VERSION "HNPBNNNYNNNNNNNNNNNNNNNNNNNNNNNNYNYYYYYYYY>4>%%%/4>'%**4YYY///"

NS_ :

BS_:

BU_: ExternalUnit SRR308

BO_ 881 YawRateInformation_7: 2 ExternalUnit
 SG_ RadarDevice_YawRate : 7|16@0+ (0.01,-327.68) [-327.68|327.66] "�/s"  SRR308

BO_ 865 YawRateInformation_6: 2 ExternalUnit
 SG_ RadarDevice_YawRate : 7|16@0+ (0.01,-327.68) [-327.68|327.66] "�/s"  SRR308

BO_ 849 YawRateInformation_5: 2 ExternalUnit
 SG_ RadarDevice_YawRate : 7|16@0+ (0.01,-327.68) [-327.68|327.66] "�/s"  SRR308

BO_ 833 YawRateInformation_4: 2 ExternalUnit
 SG_ RadarDevice_YawRate : 7|16@0+ (0.01,-327.68) [-327.68|327.66] "�/s"  SRR308

BO_ 817 YawRateInformation_3: 2 ExternalUnit
 SG_ RadarDevice_YawRate : 7|16@0+ (0.01,-327.68) [-327.68|327.66] "�/s"  SRR308

BO_ 801 YawRateInformation_2: 2 ExternalUnit
 SG_ RadarDevice_YawRate : 7|16@0+ (0.01,-327.68) [-327.68|327.66] "�/s"  SRR308

BO_ 785 YawRateInformation_1: 2 ExternalUnit
 SG_ RadarDevice_YawRate : 7|16@0+ (0.01,-327.68) [-327.68|327.66] "�/s"  SRR308

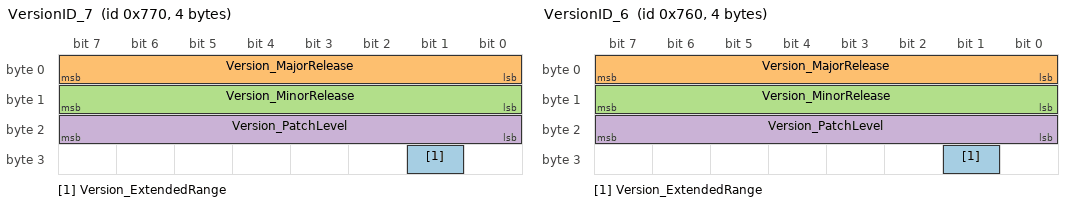
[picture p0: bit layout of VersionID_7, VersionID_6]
BO_ 1904 VersionID_7: 4 SRR308
 SG_ Version_ExtendedRange : 25|1@0+ (1,0) [0|0] ""  ExternalUnit
 SG_ Version_MajorRelease : 7|8@0+ (1,0) [0|256] ""  ExternalUnit
 SG_ Version_MinorRelease : 15|8@0+ (1,0) [0|256] ""  ExternalUnit
 SG_ Version_PatchLevel : 23|8@0+ (1,0) [0|256] ""  ExternalUnit

BO_ 1888 VersionID_6: 4 SRR308
 SG_ Version_ExtendedRange : 25|1@0+ (1,0) [0|0] ""  ExternalUnit
 SG_ Version_MajorRelease : 7|8@0+ (1,0) [0|256] ""  ExternalUnit
 SG_ Version_MinorRelease : 15|8@0+ (1,0) [0|256] ""  ExternalUnit
 SG_ Version_PatchLevel : 23|8@0+ (1,0) [0|256] ""  ExternalUnit

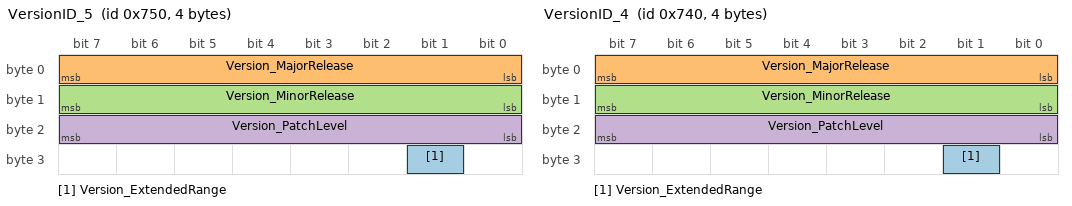
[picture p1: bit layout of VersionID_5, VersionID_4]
BO_ 1872 VersionID_5: 4 SRR308
 SG_ Version_ExtendedRange : 25|1@0+ (1,0) [0|0] ""  ExternalUnit
 SG_ Version_MajorRelease : 7|8@0+ (1,0) [0|256] ""  ExternalUnit
 SG_ Version_MinorRelease : 15|8@0+ (1,0) [0|256] ""  ExternalUnit
 SG_ Version_PatchLevel : 23|8@0+ (1,0) [0|256] ""  ExternalUnit

BO_ 1856 VersionID_4: 4 SRR308
 SG_ Version_ExtendedRange : 25|1@0+ (1,0) [0|0] ""  ExternalUnit
 SG_ Version_MajorRelease : 7|8@0+ (1,0) [0|256] ""  ExternalUnit
 SG_ Version_MinorRelease : 15|8@0+ (1,0) [0|256] ""  ExternalUnit
 SG_ Version_PatchLevel : 23|8@0+ (1,0) [0|256] ""  ExternalUnit

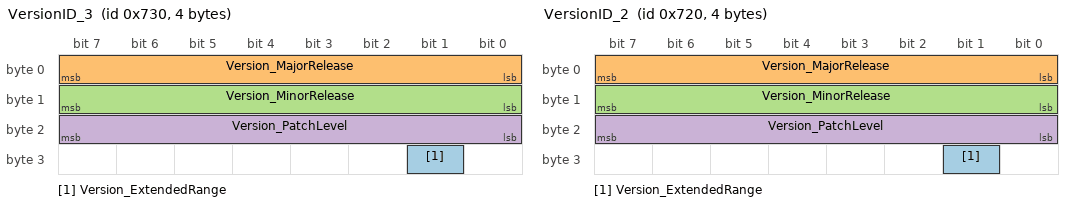
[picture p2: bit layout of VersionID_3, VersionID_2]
BO_ 1840 VersionID_3: 4 SRR308
 SG_ Version_ExtendedRange : 25|1@0+ (1,0) [0|0] ""  ExternalUnit
 SG_ Version_MajorRelease : 7|8@0+ (1,0) [0|256] ""  ExternalUnit
 SG_ Version_MinorRelease : 15|8@0+ (1,0) [0|256] ""  ExternalUnit
 SG_ Version_PatchLevel : 23|8@0+ (1,0) [0|256] ""  ExternalUnit

BO_ 1824 VersionID_2: 4 SRR308
 SG_ Version_ExtendedRange : 25|1@0+ (1,0) [0|0] ""  ExternalUnit
 SG_ Version_MajorRelease : 7|8@0+ (1,0) [0|256] ""  ExternalUnit
 SG_ Version_MinorRelease : 15|8@0+ (1,0) [0|256] ""  ExternalUnit
 SG_ Version_PatchLevel : 23|8@0+ (1,0) [0|256] ""  ExternalUnit

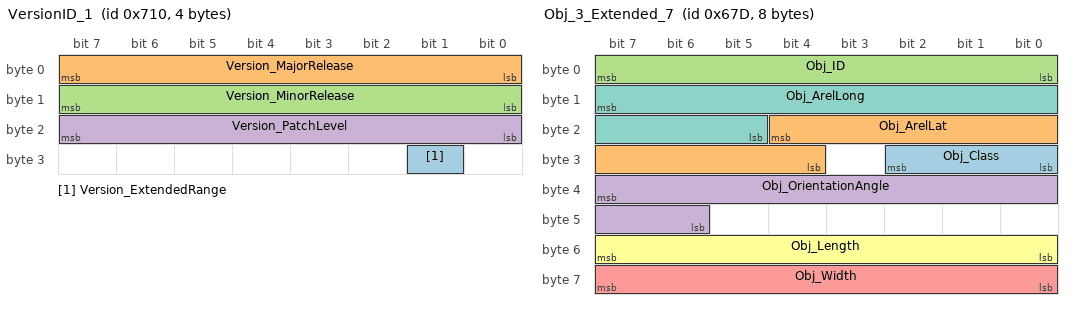
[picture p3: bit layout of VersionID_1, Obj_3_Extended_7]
BO_ 1808 VersionID_1: 4 SRR308
 SG_ Version_ExtendedRange : 25|1@0+ (1,0) [0|0] ""  ExternalUnit
 SG_ Version_MajorRelease : 7|8@0+ (1,0) [0|256] ""  ExternalUnit
 SG_ Version_MinorRelease : 15|8@0+ (1,0) [0|256] ""  ExternalUnit
 SG_ Version_PatchLevel : 23|8@0+ (1,0) [0|256] ""  ExternalUnit

BO_ 880 SpeedInformation_7: 2 ExternalUnit
 SG_ RadarDevice_Speed : 4|13@0+ (0.02,0) [0|163.8] "m/s"  SRR308
 SG_ RadarDevice_SpeedDirection : 7|2@0+ (1,0) [0|2] ""  SRR308

BO_ 864 SpeedInformation_6: 2 ExternalUnit
 SG_ RadarDevice_Speed : 4|13@0+ (0.02,0) [0|163.8] "m/s"  SRR308
 SG_ RadarDevice_SpeedDirection : 7|2@0+ (1,0) [0|2] ""  SRR308

BO_ 848 SpeedInformation_5: 2 ExternalUnit
 SG_ RadarDevice_Speed : 4|13@0+ (0.02,0) [0|163.8] "m/s"  SRR308
 SG_ RadarDevice_SpeedDirection : 7|2@0+ (1,0) [0|2] ""  SRR308

BO_ 832 SpeedInformation_4: 2 ExternalUnit
 SG_ RadarDevice_Speed : 4|13@0+ (0.02,0) [0|163.8] "m/s"  SRR308
 SG_ RadarDevice_SpeedDirection : 7|2@0+ (1,0) [0|2] ""  SRR308

BO_ 816 SpeedInformation_3: 2 ExternalUnit
 SG_ RadarDevice_Speed : 4|13@0+ (0.02,0) [0|163.8] "m/s"  SRR308
 SG_ RadarDevice_SpeedDirection : 7|2@0+ (1,0) [0|2] ""  SRR308

BO_ 800 SpeedInformation_2: 2 ExternalUnit
 SG_ RadarDevice_Speed : 4|13@0+ (0.02,0) [0|163.8] "m/s"  SRR308
 SG_ RadarDevice_SpeedDirection : 7|2@0+ (1,0) [0|2] ""  SRR308

BO_ 784 SpeedInformation_1: 2 ExternalUnit
 SG_ RadarDevice_Speed : 4|13@0+ (0.02,0) [0|163.8] "m/s"  SRR308
 SG_ RadarDevice_SpeedDirection : 7|2@0+ (1,0) [0|2] ""  SRR308

BO_ 625 RadarState_7: 8 SRR308
 SG_ RadarState_InvalidClusters : 55|8@0+ (1,0) [0|255] ""  ExternalUnit
 SG_ RadarState_Voltage_Error : 17|1@0+ (1,0) [0|0] ""  ExternalUnit
 SG_ RadarState_Temporary_Error : 18|1@0+ (1,0) [0|0] ""  ExternalUnit
 SG_ RadarState_Temperature_Error : 19|1@0+ (1,0) [0|0] ""  ExternalUnit
 SG_ RadarState_Interference : 20|1@0+ (1,0) [0|0] ""  ExternalUnit
 SG_ RadarState_Persistent_Error : 21|1@0+ (1,0) [0|0] ""  ExternalUnit
 SG_ RadarState_SortIndex : 38|3@0+ (1,0) [0|0] ""  ExternalUnit
 SG_ RadarState_RCS_Threshold : 60|3@0+ (1,0) [0|7] ""  ExternalUnit
 SG_ RadarState_CtrlRelayCfg : 41|1@0+ (1,0) [0|1] ""  ExternalUnit
 SG_ RadarState_SendQualityCfg : 44|1@0+ (1,0) [0|1] ""  ExternalUnit
 SG_ RadarState_SendExtInfoCfg : 45|1@0+ (1,0) [0|1] ""  ExternalUnit
 SG_ RadarState_MotionRxState : 47|2@0+ (1,0) [0|3] ""  ExternalUnit
 SG_ RadarState_SensorID : 34|3@0+ (1,0) [0|7] ""  ExternalUnit
 SG_ RadarState_OutputTypeCfg : 43|2@0+ (1,0) [0|3] ""  ExternalUnit
 SG_ RadarState_RadarPowerCfg : 25|3@0+ (1,0) [0|7] ""  ExternalUnit
 SG_ RadarState_NVMReadStatus : 6|1@0+ (1,0) [0|1] ""  ExternalUnit
 SG_ RadarState_NVMwriteStatus : 7|1@0+ (1,0) [0|1] ""  ExternalUnit
 SG_ RadarState_MaxDistanceCfg : 15|10@0+ (2,0) [0|2046] ""  ExternalUnit

BO_ 609 RadarState_6: 8 SRR308
 SG_ RadarState_InvalidClusters : 55|8@0+ (1,0) [0|255] ""  ExternalUnit
 SG_ RadarState_Voltage_Error : 17|1@0+ (1,0) [0|0] ""  ExternalUnit
 SG_ RadarState_Temporary_Error : 18|1@0+ (1,0) [0|0] ""  ExternalUnit
 SG_ RadarState_Temperature_Error : 19|1@0+ (1,0) [0|0] ""  ExternalUnit
 SG_ RadarState_Interference : 20|1@0+ (1,0) [0|0] ""  ExternalUnit
 SG_ RadarState_Persistent_Error : 21|1@0+ (1,0) [0|0] ""  ExternalUnit
 SG_ RadarState_SortIndex : 38|3@0+ (1,0) [0|0] ""  ExternalUnit
 SG_ RadarState_RCS_Threshold : 60|3@0+ (1,0) [0|7] ""  ExternalUnit
 SG_ RadarState_CtrlRelayCfg : 41|1@0+ (1,0) [0|1] ""  ExternalUnit
 SG_ RadarState_SendQualityCfg : 44|1@0+ (1,0) [0|1] ""  ExternalUnit
 SG_ RadarState_SendExtInfoCfg : 45|1@0+ (1,0) [0|1] ""  ExternalUnit
 SG_ RadarState_MotionRxState : 47|2@0+ (1,0) [0|3] ""  ExternalUnit
 SG_ RadarState_SensorID : 34|3@0+ (1,0) [0|7] ""  ExternalUnit
 SG_ RadarState_OutputTypeCfg : 43|2@0+ (1,0) [0|3] ""  ExternalUnit
 SG_ RadarState_RadarPowerCfg : 25|3@0+ (1,0) [0|7] ""  ExternalUnit
 SG_ RadarState_NVMReadStatus : 6|1@0+ (1,0) [0|1] ""  ExternalUnit
 SG_ RadarState_NVMwriteStatus : 7|1@0+ (1,0) [0|1] ""  ExternalUnit
 SG_ RadarState_MaxDistanceCfg : 15|10@0+ (2,0) [0|2046] ""  ExternalUnit

BO_ 593 RadarState_5: 8 SRR308
 SG_ RadarState_InvalidClusters : 55|8@0+ (1,0) [0|255] ""  ExternalUnit
 SG_ RadarState_Voltage_Error : 17|1@0+ (1,0) [0|0] ""  ExternalUnit
 SG_ RadarState_Temporary_Error : 18|1@0+ (1,0) [0|0] ""  ExternalUnit
 SG_ RadarState_Temperature_Error : 19|1@0+ (1,0) [0|0] ""  ExternalUnit
 SG_ RadarState_Interference : 20|1@0+ (1,0) [0|0] ""  ExternalUnit
 SG_ RadarState_Persistent_Error : 21|1@0+ (1,0) [0|0] ""  ExternalUnit
 SG_ RadarState_SortIndex : 38|3@0+ (1,0) [0|0] ""  ExternalUnit
 SG_ RadarState_RCS_Threshold : 60|3@0+ (1,0) [0|7] ""  ExternalUnit
 SG_ RadarState_CtrlRelayCfg : 41|1@0+ (1,0) [0|1] ""  ExternalUnit
 SG_ RadarState_SendQualityCfg : 44|1@0+ (1,0) [0|1] ""  ExternalUnit
 SG_ RadarState_SendExtInfoCfg : 45|1@0+ (1,0) [0|1] ""  ExternalUnit
 SG_ RadarState_MotionRxState : 47|2@0+ (1,0) [0|3] ""  ExternalUnit
 SG_ RadarState_SensorID : 34|3@0+ (1,0) [0|7] ""  ExternalUnit
 SG_ RadarState_OutputTypeCfg : 43|2@0+ (1,0) [0|3] ""  ExternalUnit
 SG_ RadarState_RadarPowerCfg : 25|3@0+ (1,0) [0|7] ""  ExternalUnit
 SG_ RadarState_NVMReadStatus : 6|1@0+ (1,0) [0|1] ""  ExternalUnit
 SG_ RadarState_NVMwriteStatus : 7|1@0+ (1,0) [0|1] ""  ExternalUnit
 SG_ RadarState_MaxDistanceCfg : 15|10@0+ (2,0) [0|2046] ""  ExternalUnit

BO_ 577 RadarState_4: 8 SRR308
 SG_ RadarState_InvalidClusters : 55|8@0+ (1,0) [0|255] ""  ExternalUnit
 SG_ RadarState_Voltage_Error : 17|1@0+ (1,0) [0|0] ""  ExternalUnit
 SG_ RadarState_Temporary_Error : 18|1@0+ (1,0) [0|0] ""  ExternalUnit
 SG_ RadarState_Temperature_Error : 19|1@0+ (1,0) [0|0] ""  ExternalUnit
 SG_ RadarState_Interference : 20|1@0+ (1,0) [0|0] ""  ExternalUnit
 SG_ RadarState_Persistent_Error : 21|1@0+ (1,0) [0|0] ""  ExternalUnit
 SG_ RadarState_SortIndex : 38|3@0+ (1,0) [0|0] ""  ExternalUnit
 SG_ RadarState_RCS_Threshold : 60|3@0+ (1,0) [0|7] ""  ExternalUnit
 SG_ RadarState_CtrlRelayCfg : 41|1@0+ (1,0) [0|1] ""  ExternalUnit
 SG_ RadarState_SendQualityCfg : 44|1@0+ (1,0) [0|1] ""  ExternalUnit
 SG_ RadarState_SendExtInfoCfg : 45|1@0+ (1,0) [0|1] ""  ExternalUnit
 SG_ RadarState_MotionRxState : 47|2@0+ (1,0) [0|3] ""  ExternalUnit
 SG_ RadarState_SensorID : 34|3@0+ (1,0) [0|7] ""  ExternalUnit
 SG_ RadarState_OutputTypeCfg : 43|2@0+ (1,0) [0|3] ""  ExternalUnit
 SG_ RadarState_RadarPowerCfg : 25|3@0+ (1,0) [0|7] ""  ExternalUnit
 SG_ RadarState_NVMReadStatus : 6|1@0+ (1,0) [0|1] ""  ExternalUnit
 SG_ RadarState_NVMwriteStatus : 7|1@0+ (1,0) [0|1] ""  ExternalUnit
 SG_ RadarState_MaxDistanceCfg : 15|10@0+ (2,0) [0|2046] ""  ExternalUnit

BO_ 561 RadarState_3: 8 SRR308
 SG_ RadarState_InvalidClusters : 55|8@0+ (1,0) [0|255] ""  ExternalUnit
 SG_ RadarState_Voltage_Error : 17|1@0+ (1,0) [0|0] ""  ExternalUnit
 SG_ RadarState_Temporary_Error : 18|1@0+ (1,0) [0|0] ""  ExternalUnit
 SG_ RadarState_Temperature_Error : 19|1@0+ (1,0) [0|0] ""  ExternalUnit
 SG_ RadarState_Interference : 20|1@0+ (1,0) [0|0] ""  ExternalUnit
 SG_ RadarState_Persistent_Error : 21|1@0+ (1,0) [0|0] ""  ExternalUnit
 SG_ RadarState_SortIndex : 38|3@0+ (1,0) [0|0] ""  ExternalUnit
 SG_ RadarState_RCS_Threshold : 60|3@0+ (1,0) [0|7] ""  ExternalUnit
 SG_ RadarState_CtrlRelayCfg : 41|1@0+ (1,0) [0|1] ""  ExternalUnit
 SG_ RadarState_SendQualityCfg : 44|1@0+ (1,0) [0|1] ""  ExternalUnit
 SG_ RadarState_SendExtInfoCfg : 45|1@0+ (1,0) [0|1] ""  ExternalUnit
 SG_ RadarState_MotionRxState : 47|2@0+ (1,0) [0|3] ""  ExternalUnit
 SG_ RadarState_SensorID : 34|3@0+ (1,0) [0|7] ""  ExternalUnit
 SG_ RadarState_OutputTypeCfg : 43|2@0+ (1,0) [0|3] ""  ExternalUnit
 SG_ RadarState_RadarPowerCfg : 25|3@0+ (1,0) [0|7] ""  ExternalUnit
 SG_ RadarState_NVMReadStatus : 6|1@0+ (1,0) [0|1] ""  ExternalUnit
 SG_ RadarState_NVMwriteStatus : 7|1@0+ (1,0) [0|1] ""  ExternalUnit
 SG_ RadarState_MaxDistanceCfg : 15|10@0+ (2,0) [0|2046] ""  ExternalUnit

BO_ 545 RadarState_2: 8 SRR308
 SG_ RadarState_InvalidClusters : 55|8@0+ (1,0) [0|255] ""  ExternalUnit
 SG_ RadarState_Voltage_Error : 17|1@0+ (1,0) [0|0] ""  ExternalUnit
 SG_ RadarState_Temporary_Error : 18|1@0+ (1,0) [0|0] ""  ExternalUnit
 SG_ RadarState_Temperature_Error : 19|1@0+ (1,0) [0|0] ""  ExternalUnit
 SG_ RadarState_Interference : 20|1@0+ (1,0) [0|0] ""  ExternalUnit
 SG_ RadarState_Persistent_Error : 21|1@0+ (1,0) [0|0] ""  ExternalUnit
 SG_ RadarState_SortIndex : 38|3@0+ (1,0) [0|0] ""  ExternalUnit
 SG_ RadarState_RCS_Threshold : 60|3@0+ (1,0) [0|7] ""  ExternalUnit
 SG_ RadarState_CtrlRelayCfg : 41|1@0+ (1,0) [0|1] ""  ExternalUnit
 SG_ RadarState_SendQualityCfg : 44|1@0+ (1,0) [0|1] ""  ExternalUnit
 SG_ RadarState_SendExtInfoCfg : 45|1@0+ (1,0) [0|1] ""  ExternalUnit
 SG_ RadarState_MotionRxState : 47|2@0+ (1,0) [0|3] ""  ExternalUnit
 SG_ RadarState_SensorID : 34|3@0+ (1,0) [0|7] ""  ExternalUnit
 SG_ RadarState_OutputTypeCfg : 43|2@0+ (1,0) [0|3] ""  ExternalUnit
 SG_ RadarState_RadarPowerCfg : 25|3@0+ (1,0) [0|7] ""  ExternalUnit
 SG_ RadarState_NVMReadStatus : 6|1@0+ (1,0) [0|1] ""  ExternalUnit
 SG_ RadarState_NVMwriteStatus : 7|1@0+ (1,0) [0|1] ""  ExternalUnit
 SG_ RadarState_MaxDistanceCfg : 15|10@0+ (2,0) [0|2046] ""  ExternalUnit

BO_ 529 RadarState_1: 8 SRR308
 SG_ RadarState_InvalidClusters : 55|8@0+ (1,0) [0|255] ""  ExternalUnit
 SG_ RadarState_Voltage_Error : 17|1@0+ (1,0) [0|0] ""  ExternalUnit
 SG_ RadarState_Temporary_Error : 18|1@0+ (1,0) [0|0] ""  ExternalUnit
 SG_ RadarState_Temperature_Error : 19|1@0+ (1,0) [0|0] ""  ExternalUnit
 SG_ RadarState_Interference : 20|1@0+ (1,0) [0|0] ""  ExternalUnit
 SG_ RadarState_Persistent_Error : 21|1@0+ (1,0) [0|0] ""  ExternalUnit
 SG_ RadarState_SortIndex : 38|3@0+ (1,0) [0|0] ""  ExternalUnit
 SG_ RadarState_RCS_Threshold : 60|3@0+ (1,0) [0|7] ""  ExternalUnit
 SG_ RadarState_CtrlRelayCfg : 41|1@0+ (1,0) [0|1] ""  ExternalUnit
 SG_ RadarState_SendQualityCfg : 44|1@0+ (1,0) [0|1] ""  ExternalUnit
 SG_ RadarState_SendExtInfoCfg : 45|1@0+ (1,0) [0|1] ""  ExternalUnit
 SG_ RadarState_MotionRxState : 47|2@0+ (1,0) [0|3] ""  ExternalUnit
 SG_ RadarState_SensorID : 34|3@0+ (1,0) [0|7] ""  ExternalUnit
 SG_ RadarState_OutputTypeCfg : 43|2@0+ (1,0) [0|3] ""  ExternalUnit
 SG_ RadarState_RadarPowerCfg : 25|3@0+ (1,0) [0|7] ""  ExternalUnit
 SG_ RadarState_NVMReadStatus : 6|1@0+ (1,0) [0|1] ""  ExternalUnit
 SG_ RadarState_NVMwriteStatus : 7|1@0+ (1,0) [0|1] ""  ExternalUnit
 SG_ RadarState_MaxDistanceCfg : 15|10@0+ (2,0) [0|2046] ""  ExternalUnit

BO_ 624 RadarConfiguration_7: 8 ExternalUnit
 SG_ RadarCfg_InvalidClusters_valid : 52|1@0+ (1,0) [0|1] ""  SRR308,ExternalUnit
 SG_ RadarCfg_InvalidClusters : 63|8@0+ (1,0) [0|255] ""  SRR308,ExternalUnit
 SG_ RadarCfg_RCS_Threshold_Valid : 48|1@0+ (1,0) [0|1] ""  SRR308,ExternalUnit
 SG_ RadarCfg_RCS_Threshold : 51|3@0+ (1,0) [0|7] ""  SRR308,ExternalUnit
 SG_ RadarCfg_StoreInNVM_valid : 7|1@0+ (1,0) [0|1] ""  SRR308,ExternalUnit
 SG_ RadarCfg_SortIndex_valid : 6|1@0+ (1,0) [0|1] ""  SRR308,ExternalUnit
 SG_ RadarCfg_SortIndex : 46|3@0+ (1,0) [0|7] ""  SRR308,ExternalUnit
 SG_ RadarCfg_StoreInNVM : 47|1@0+ (1,0) [0|1] ""  SRR308,ExternalUnit
 SG_ RadarCfg_SendExtInfo_valid : 5|1@0+ (1,0) [0|1] ""  SRR308,ExternalUnit
 SG_ RadarCfg_SendExtInfo : 43|1@0+ (1,0) [0|1] ""  SRR308,ExternalUnit
 SG_ RadarCfg_CtrlRelay_valid : 40|1@0+ (1,0) [0|1] ""  SRR308,ExternalUnit
 SG_ RadarCfg_CtrlRelay : 41|1@0+ (1,0) [0|1] ""  SRR308,ExternalUnit
 SG_ RadarCfg_SendQuality_valid : 4|1@0+ (1,0) [0|1] ""  SRR308,ExternalUnit
 SG_ RadarCfg_SendQuality : 42|1@0+ (1,0) [0|1] ""  SRR308,ExternalUnit
 SG_ RadarCfg_MaxDistance_valid : 0|1@0+ (1,0) [0|1] ""  SRR308,ExternalUnit
 SG_ RadarCfg_OutputType_valid : 3|1@0+ (1,0) [0|1] ""  SRR308,ExternalUnit
 SG_ RadarCfg_SensorID_valid : 1|1@0+ (1,0) [0|1] ""  SRR308,ExternalUnit
 SG_ RadarCfg_MaxDistance : 15|10@0+ (2,0) [0|2046] "m"  SRR308,ExternalUnit
 SG_ RadarCfg_OutputType : 36|2@0+ (1,0) [0|2] ""  SRR308,ExternalUnit
 SG_ RadarCfg_SensorID : 34|3@0+ (1,0) [0|7] ""  SRR308,ExternalUnit

BO_ 608 RadarConfiguration_6: 8 ExternalUnit
 SG_ RadarCfg_InvalidClusters_valid : 52|1@0+ (1,0) [0|1] ""  SRR308,ExternalUnit
 SG_ RadarCfg_InvalidClusters : 63|8@0+ (1,0) [0|255] ""  SRR308,ExternalUnit
 SG_ RadarCfg_RCS_Threshold_Valid : 48|1@0+ (1,0) [0|1] ""  SRR308,ExternalUnit
 SG_ RadarCfg_RCS_Threshold : 51|3@0+ (1,0) [0|7] ""  SRR308,ExternalUnit
 SG_ RadarCfg_StoreInNVM_valid : 7|1@0+ (1,0) [0|1] ""  SRR308,ExternalUnit
 SG_ RadarCfg_SortIndex_valid : 6|1@0+ (1,0) [0|1] ""  SRR308,ExternalUnit
 SG_ RadarCfg_SortIndex : 46|3@0+ (1,0) [0|7] ""  SRR308,ExternalUnit
 SG_ RadarCfg_StoreInNVM : 47|1@0+ (1,0) [0|1] ""  SRR308,ExternalUnit
 SG_ RadarCfg_SendExtInfo_valid : 5|1@0+ (1,0) [0|1] ""  SRR308,ExternalUnit
 SG_ RadarCfg_SendExtInfo : 43|1@0+ (1,0) [0|1] ""  SRR308,ExternalUnit
 SG_ RadarCfg_CtrlRelay_valid : 40|1@0+ (1,0) [0|1] ""  SRR308,ExternalUnit
 SG_ RadarCfg_CtrlRelay : 41|1@0+ (1,0) [0|1] ""  SRR308,ExternalUnit
 SG_ RadarCfg_SendQuality_valid : 4|1@0+ (1,0) [0|1] ""  SRR308,ExternalUnit
 SG_ RadarCfg_SendQuality : 42|1@0+ (1,0) [0|1] ""  SRR308,ExternalUnit
 SG_ RadarCfg_MaxDistance_valid : 0|1@0+ (1,0) [0|1] ""  SRR308,ExternalUnit
 SG_ RadarCfg_OutputType_valid : 3|1@0+ (1,0) [0|1] ""  SRR308,ExternalUnit
 SG_ RadarCfg_SensorID_valid : 1|1@0+ (1,0) [0|1] ""  SRR308,ExternalUnit
 SG_ RadarCfg_MaxDistance : 15|10@0+ (2,0) [0|2046] "m"  SRR308,ExternalUnit
 SG_ RadarCfg_OutputType : 36|2@0+ (1,0) [0|2] ""  SRR308,ExternalUnit
 SG_ RadarCfg_SensorID : 34|3@0+ (1,0) [0|7] ""  SRR308,ExternalUnit

BO_ 592 RadarConfiguration_5: 8 ExternalUnit
 SG_ RadarCfg_InvalidClusters_valid : 52|1@0+ (1,0) [0|1] ""  SRR308,ExternalUnit
 SG_ RadarCfg_InvalidClusters : 63|8@0+ (1,0) [0|255] ""  SRR308,ExternalUnit
 SG_ RadarCfg_RCS_Threshold_Valid : 48|1@0+ (1,0) [0|1] ""  SRR308,ExternalUnit
 SG_ RadarCfg_RCS_Threshold : 51|3@0+ (1,0) [0|7] ""  SRR308,ExternalUnit
 SG_ RadarCfg_StoreInNVM_valid : 7|1@0+ (1,0) [0|1] ""  SRR308,ExternalUnit
 SG_ RadarCfg_SortIndex_valid : 6|1@0+ (1,0) [0|1] ""  SRR308,ExternalUnit
 SG_ RadarCfg_SortIndex : 46|3@0+ (1,0) [0|7] ""  SRR308,ExternalUnit
 SG_ RadarCfg_StoreInNVM : 47|1@0+ (1,0) [0|1] ""  SRR308,ExternalUnit
 SG_ RadarCfg_SendExtInfo_valid : 5|1@0+ (1,0) [0|1] ""  SRR308,ExternalUnit
 SG_ RadarCfg_SendExtInfo : 43|1@0+ (1,0) [0|1] ""  SRR308,ExternalUnit
 SG_ RadarCfg_CtrlRelay_valid : 40|1@0+ (1,0) [0|1] ""  SRR308,ExternalUnit
 SG_ RadarCfg_CtrlRelay : 41|1@0+ (1,0) [0|1] ""  SRR308,ExternalUnit
 SG_ RadarCfg_SendQuality_valid : 4|1@0+ (1,0) [0|1] ""  SRR308,ExternalUnit
 SG_ RadarCfg_SendQuality : 42|1@0+ (1,0) [0|1] ""  SRR308,ExternalUnit
 SG_ RadarCfg_MaxDistance_valid : 0|1@0+ (1,0) [0|1] ""  SRR308,ExternalUnit
 SG_ RadarCfg_OutputType_valid : 3|1@0+ (1,0) [0|1] ""  SRR308,ExternalUnit
 SG_ RadarCfg_SensorID_valid : 1|1@0+ (1,0) [0|1] ""  SRR308,ExternalUnit
 SG_ RadarCfg_MaxDistance : 15|10@0+ (2,0) [0|2046] "m"  SRR308,ExternalUnit
 SG_ RadarCfg_OutputType : 36|2@0+ (1,0) [0|2] ""  SRR308,ExternalUnit
 SG_ RadarCfg_SensorID : 34|3@0+ (1,0) [0|7] ""  SRR308,ExternalUnit

BO_ 576 RadarConfiguration_4: 8 ExternalUnit
 SG_ RadarCfg_InvalidClusters_valid : 52|1@0+ (1,0) [0|1] ""  SRR308,ExternalUnit
 SG_ RadarCfg_InvalidClusters : 63|8@0+ (1,0) [0|255] ""  SRR308,ExternalUnit
 SG_ RadarCfg_RCS_Threshold_Valid : 48|1@0+ (1,0) [0|1] ""  SRR308,ExternalUnit
 SG_ RadarCfg_RCS_Threshold : 51|3@0+ (1,0) [0|7] ""  SRR308,ExternalUnit
 SG_ RadarCfg_StoreInNVM_valid : 7|1@0+ (1,0) [0|1] ""  SRR308,ExternalUnit
 SG_ RadarCfg_SortIndex_valid : 6|1@0+ (1,0) [0|1] ""  SRR308,ExternalUnit
 SG_ RadarCfg_SortIndex : 46|3@0+ (1,0) [0|7] ""  SRR308,ExternalUnit
 SG_ RadarCfg_StoreInNVM : 47|1@0+ (1,0) [0|1] ""  SRR308,ExternalUnit
 SG_ RadarCfg_SendExtInfo_valid : 5|1@0+ (1,0) [0|1] ""  SRR308,ExternalUnit
 SG_ RadarCfg_SendExtInfo : 43|1@0+ (1,0) [0|1] ""  SRR308,ExternalUnit
 SG_ RadarCfg_CtrlRelay_valid : 40|1@0+ (1,0) [0|1] ""  SRR308,ExternalUnit
 SG_ RadarCfg_CtrlRelay : 41|1@0+ (1,0) [0|1] ""  SRR308,ExternalUnit
 SG_ RadarCfg_SendQuality_valid : 4|1@0+ (1,0) [0|1] ""  SRR308,ExternalUnit
 SG_ RadarCfg_SendQuality : 42|1@0+ (1,0) [0|1] ""  SRR308,ExternalUnit
 SG_ RadarCfg_MaxDistance_valid : 0|1@0+ (1,0) [0|1] ""  SRR308,ExternalUnit
 SG_ RadarCfg_OutputType_valid : 3|1@0+ (1,0) [0|1] ""  SRR308,ExternalUnit
 SG_ RadarCfg_SensorID_valid : 1|1@0+ (1,0) [0|1] ""  SRR308,ExternalUnit
 SG_ RadarCfg_MaxDistance : 15|10@0+ (2,0) [0|2046] "m"  SRR308,ExternalUnit
 SG_ RadarCfg_OutputType : 36|2@0+ (1,0) [0|2] ""  SRR308,ExternalUnit
 SG_ RadarCfg_SensorID : 34|3@0+ (1,0) [0|7] ""  SRR308,ExternalUnit

BO_ 560 RadarConfiguration_3: 8 ExternalUnit
 SG_ RadarCfg_InvalidClusters_valid : 52|1@0+ (1,0) [0|1] ""  SRR308,ExternalUnit
 SG_ RadarCfg_InvalidClusters : 63|8@0+ (1,0) [0|255] ""  SRR308,ExternalUnit
 SG_ RadarCfg_RCS_Threshold_Valid : 48|1@0+ (1,0) [0|1] ""  SRR308,ExternalUnit
 SG_ RadarCfg_RCS_Threshold : 51|3@0+ (1,0) [0|7] ""  SRR308,ExternalUnit
 SG_ RadarCfg_StoreInNVM_valid : 7|1@0+ (1,0) [0|1] ""  SRR308,ExternalUnit
 SG_ RadarCfg_SortIndex_valid : 6|1@0+ (1,0) [0|1] ""  SRR308,ExternalUnit
 SG_ RadarCfg_SortIndex : 46|3@0+ (1,0) [0|7] ""  SRR308,ExternalUnit
 SG_ RadarCfg_StoreInNVM : 47|1@0+ (1,0) [0|1] ""  SRR308,ExternalUnit
 SG_ RadarCfg_SendExtInfo_valid : 5|1@0+ (1,0) [0|1] ""  SRR308,ExternalUnit
 SG_ RadarCfg_SendExtInfo : 43|1@0+ (1,0) [0|1] ""  SRR308,ExternalUnit
 SG_ RadarCfg_CtrlRelay_valid : 40|1@0+ (1,0) [0|1] ""  SRR308,ExternalUnit
 SG_ RadarCfg_CtrlRelay : 41|1@0+ (1,0) [0|1] ""  SRR308,ExternalUnit
 SG_ RadarCfg_SendQuality_valid : 4|1@0+ (1,0) [0|1] ""  SRR308,ExternalUnit
 SG_ RadarCfg_SendQuality : 42|1@0+ (1,0) [0|1] ""  SRR308,ExternalUnit
 SG_ RadarCfg_MaxDistance_valid : 0|1@0+ (1,0) [0|1] ""  SRR308,ExternalUnit
 SG_ RadarCfg_OutputType_valid : 3|1@0+ (1,0) [0|1] ""  SRR308,ExternalUnit
 SG_ RadarCfg_SensorID_valid : 1|1@0+ (1,0) [0|1] ""  SRR308,ExternalUnit
 SG_ RadarCfg_MaxDistance : 15|10@0+ (2,0) [0|2046] "m"  SRR308,ExternalUnit
 SG_ RadarCfg_OutputType : 36|2@0+ (1,0) [0|2] ""  SRR308,ExternalUnit
 SG_ RadarCfg_SensorID : 34|3@0+ (1,0) [0|7] ""  SRR308,ExternalUnit

BO_ 544 RadarConfiguration_2: 8 ExternalUnit
 SG_ RadarCfg_InvalidClusters_valid : 52|1@0+ (1,0) [0|1] ""  SRR308,ExternalUnit
 SG_ RadarCfg_InvalidClusters : 63|8@0+ (1,0) [0|255] ""  SRR308,ExternalUnit
 SG_ RadarCfg_RCS_Threshold_Valid : 48|1@0+ (1,0) [0|1] ""  SRR308,ExternalUnit
 SG_ RadarCfg_RCS_Threshold : 51|3@0+ (1,0) [0|7] ""  SRR308,ExternalUnit
 SG_ RadarCfg_StoreInNVM_valid : 7|1@0+ (1,0) [0|1] ""  SRR308,ExternalUnit
 SG_ RadarCfg_SortIndex_valid : 6|1@0+ (1,0) [0|1] ""  SRR308,ExternalUnit
 SG_ RadarCfg_SortIndex : 46|3@0+ (1,0) [0|7] ""  SRR308,ExternalUnit
 SG_ RadarCfg_StoreInNVM : 47|1@0+ (1,0) [0|1] ""  SRR308,ExternalUnit
 SG_ RadarCfg_SendExtInfo_valid : 5|1@0+ (1,0) [0|1] ""  SRR308,ExternalUnit
 SG_ RadarCfg_SendExtInfo : 43|1@0+ (1,0) [0|1] ""  SRR308,ExternalUnit
 SG_ RadarCfg_CtrlRelay_valid : 40|1@0+ (1,0) [0|1] ""  SRR308,ExternalUnit
 SG_ RadarCfg_CtrlRelay : 41|1@0+ (1,0) [0|1] ""  SRR308,ExternalUnit
 SG_ RadarCfg_SendQuality_valid : 4|1@0+ (1,0) [0|1] ""  SRR308,ExternalUnit
 SG_ RadarCfg_SendQuality : 42|1@0+ (1,0) [0|1] ""  SRR308,ExternalUnit
 SG_ RadarCfg_MaxDistance_valid : 0|1@0+ (1,0) [0|1] ""  SRR308,ExternalUnit
 SG_ RadarCfg_OutputType_valid : 3|1@0+ (1,0) [0|1] ""  SRR308,ExternalUnit
 SG_ RadarCfg_SensorID_valid : 1|1@0+ (1,0) [0|1] ""  SRR308,ExternalUnit
 SG_ RadarCfg_MaxDistance : 15|10@0+ (2,0) [0|2046] "m"  SRR308,ExternalUnit
 SG_ RadarCfg_OutputType : 36|2@0+ (1,0) [0|2] ""  SRR308,ExternalUnit
 SG_ RadarCfg_SensorID : 34|3@0+ (1,0) [0|7] ""  SRR308,ExternalUnit

BO_ 528 RadarConfiguration_1: 8 ExternalUnit
 SG_ RadarCfg_InvalidClusters_valid : 52|1@0+ (1,0) [0|1] ""  SRR308,ExternalUnit
 SG_ RadarCfg_InvalidClusters : 63|8@0+ (1,0) [0|255] ""  SRR308,ExternalUnit
 SG_ RadarCfg_RCS_Threshold_Valid : 48|1@0+ (1,0) [0|1] ""  SRR308,ExternalUnit
 SG_ RadarCfg_RCS_Threshold : 51|3@0+ (1,0) [0|7] ""  SRR308,ExternalUnit
 SG_ RadarCfg_StoreInNVM_valid : 7|1@0+ (1,0) [0|1] ""  SRR308,ExternalUnit
 SG_ RadarCfg_SortIndex_valid : 6|1@0+ (1,0) [0|1] ""  SRR308,ExternalUnit
 SG_ RadarCfg_SortIndex : 46|3@0+ (1,0) [0|7] ""  SRR308,ExternalUnit
 SG_ RadarCfg_StoreInNVM : 47|1@0+ (1,0) [0|1] ""  SRR308,ExternalUnit
 SG_ RadarCfg_SendExtInfo_valid : 5|1@0+ (1,0) [0|1] ""  SRR308,ExternalUnit
 SG_ RadarCfg_SendExtInfo : 43|1@0+ (1,0) [0|1] ""  SRR308,ExternalUnit
 SG_ RadarCfg_CtrlRelay_valid : 40|1@0+ (1,0) [0|1] ""  SRR308,ExternalUnit
 SG_ RadarCfg_CtrlRelay : 41|1@0+ (1,0) [0|1] ""  SRR308,ExternalUnit
 SG_ RadarCfg_SendQuality_valid : 4|1@0+ (1,0) [0|1] ""  SRR308,ExternalUnit
 SG_ RadarCfg_SendQuality : 42|1@0+ (1,0) [0|1] ""  SRR308,ExternalUnit
 SG_ RadarCfg_MaxDistance_valid : 0|1@0+ (1,0) [0|1] ""  SRR308,ExternalUnit
 SG_ RadarCfg_OutputType_valid : 3|1@0+ (1,0) [0|1] ""  SRR308,ExternalUnit
 SG_ RadarCfg_SensorID_valid : 1|1@0+ (1,0) [0|1] ""  SRR308,ExternalUnit
 SG_ RadarCfg_MaxDistance : 15|10@0+ (2,0) [0|2046] "m"  SRR308,ExternalUnit
 SG_ RadarCfg_OutputType : 36|2@0+ (1,0) [0|2] ""  SRR308,ExternalUnit
 SG_ RadarCfg_SensorID : 34|3@0+ (1,0) [0|7] ""  SRR308,ExternalUnit

BO_ 1662 Obj_4_Warning_7: 4 SRR308
 SG_ Obj_CollDetRegionBitfield : 15|8@0+ (1,0) [0|255] ""  ExternalUnit
 SG_ Obj_ID : 7|8@0+ (1,0) [0|255] ""  ExternalUnit

BO_ 1646 Obj_4_Warning_6: 4 SRR308
 SG_ Obj_CollDetRegionBitfield : 15|8@0+ (1,0) [0|255] ""  ExternalUnit
 SG_ Obj_ID : 7|8@0+ (1,0) [0|255] ""  ExternalUnit

BO_ 1630 Obj_4_Warning_5: 4 SRR308
 SG_ Obj_CollDetRegionBitfield : 15|8@0+ (1,0) [0|255] ""  ExternalUnit
 SG_ Obj_ID : 7|8@0+ (1,0) [0|255] ""  ExternalUnit

BO_ 1614 Obj_4_Warning_4: 4 SRR308
 SG_ Obj_CollDetRegionBitfield : 15|8@0+ (1,0) [0|255] ""  ExternalUnit
 SG_ Obj_ID : 7|8@0+ (1,0) [0|255] ""  ExternalUnit

BO_ 1598 Obj_4_Warning_3: 4 SRR308
 SG_ Obj_CollDetRegionBitfield : 15|8@0+ (1,0) [0|255] ""  ExternalUnit
 SG_ Obj_ID : 7|8@0+ (1,0) [0|255] ""  ExternalUnit

BO_ 1582 Obj_4_Warning_2: 4 SRR308
 SG_ Obj_CollDetRegionBitfield : 15|8@0+ (1,0) [0|255] ""  ExternalUnit
 SG_ Obj_ID : 7|8@0+ (1,0) [0|255] ""  ExternalUnit

BO_ 1566 Obj_4_Warning_1: 4 SRR308
 SG_ Obj_CollDetRegionBitfield : 15|8@0+ (1,0) [0|255] ""  ExternalUnit
 SG_ Obj_ID : 7|8@0+ (1,0) [0|255] ""  ExternalUnit

BO_ 1661 Obj_3_Extended_7: 8 SRR308
 SG_ Obj_Class : 26|3@0+ (1,0) [0|7] ""  ExternalUnit
 SG_ Obj_ArelLat : 20|9@0+ (0.01,-2.5) [-2.5|2.61] "m/s�"  ExternalUnit
 SG_ Obj_ID : 7|8@0+ (1,0) [0|255] ""  ExternalUnit
 SG_ Obj_OrientationAngle : 39|10@0+ (0.4,-180) [-180|229.2] "deg"  ExternalUnit
 SG_ Obj_Width : 63|8@0+ (0.2,0) [0|51] "m"  ExternalUnit
 SG_ Obj_Length : 55|8@0+ (0.2,0) [0|51] "m"  ExternalUnit
 SG_ Obj_ArelLong : 15|11@0+ (0.01,-10) [-10|10.47] "m/s�"  ExternalUnit

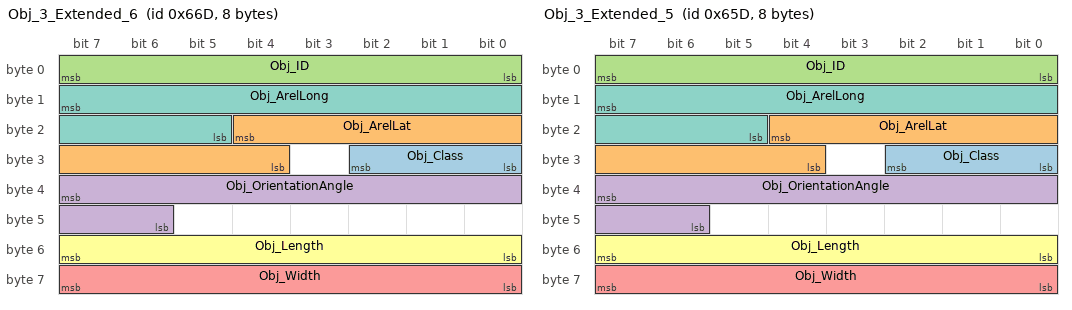
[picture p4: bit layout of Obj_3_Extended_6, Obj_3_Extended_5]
BO_ 1645 Obj_3_Extended_6: 8 SRR308
 SG_ Obj_Class : 26|3@0+ (1,0) [0|7] ""  ExternalUnit
 SG_ Obj_ArelLat : 20|9@0+ (0.01,-2.5) [-2.5|2.61] "m/s�"  ExternalUnit
 SG_ Obj_ID : 7|8@0+ (1,0) [0|255] ""  ExternalUnit
 SG_ Obj_OrientationAngle : 39|10@0+ (0.4,-180) [-180|229.2] "deg"  ExternalUnit
 SG_ Obj_Width : 63|8@0+ (0.2,0) [0|51] "m"  ExternalUnit
 SG_ Obj_Length : 55|8@0+ (0.2,0) [0|51] "m"  ExternalUnit
 SG_ Obj_ArelLong : 15|11@0+ (0.01,-10) [-10|10.47] "m/s�"  ExternalUnit

BO_ 1629 Obj_3_Extended_5: 8 SRR308
 SG_ Obj_Class : 26|3@0+ (1,0) [0|7] ""  ExternalUnit
 SG_ Obj_ArelLat : 20|9@0+ (0.01,-2.5) [-2.5|2.61] "m/s�"  ExternalUnit
 SG_ Obj_ID : 7|8@0+ (1,0) [0|255] ""  ExternalUnit
 SG_ Obj_OrientationAngle : 39|10@0+ (0.4,-180) [-180|229.2] "deg"  ExternalUnit
 SG_ Obj_Width : 63|8@0+ (0.2,0) [0|51] "m"  ExternalUnit
 SG_ Obj_Length : 55|8@0+ (0.2,0) [0|51] "m"  ExternalUnit
 SG_ Obj_ArelLong : 15|11@0+ (0.01,-10) [-10|10.47] "m/s�"  ExternalUnit

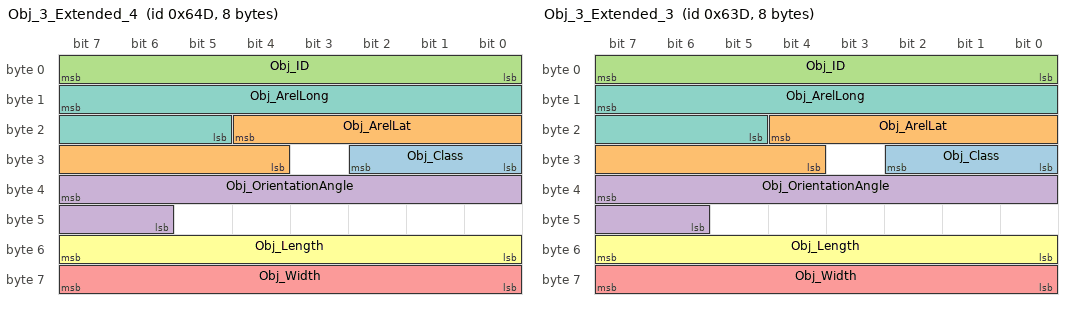
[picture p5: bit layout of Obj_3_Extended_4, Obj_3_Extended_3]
BO_ 1613 Obj_3_Extended_4: 8 SRR308
 SG_ Obj_Class : 26|3@0+ (1,0) [0|7] ""  ExternalUnit
 SG_ Obj_ArelLat : 20|9@0+ (0.01,-2.5) [-2.5|2.61] "m/s�"  ExternalUnit
 SG_ Obj_ID : 7|8@0+ (1,0) [0|255] ""  ExternalUnit
 SG_ Obj_OrientationAngle : 39|10@0+ (0.4,-180) [-180|229.2] "deg"  ExternalUnit
 SG_ Obj_Width : 63|8@0+ (0.2,0) [0|51] "m"  ExternalUnit
 SG_ Obj_Length : 55|8@0+ (0.2,0) [0|51] "m"  ExternalUnit
 SG_ Obj_ArelLong : 15|11@0+ (0.01,-10) [-10|10.47] "m/s�"  ExternalUnit

BO_ 1597 Obj_3_Extended_3: 8 SRR308
 SG_ Obj_Class : 26|3@0+ (1,0) [0|7] ""  ExternalUnit
 SG_ Obj_ArelLat : 20|9@0+ (0.01,-2.5) [-2.5|2.61] "m/s�"  ExternalUnit
 SG_ Obj_ID : 7|8@0+ (1,0) [0|255] ""  ExternalUnit
 SG_ Obj_OrientationAngle : 39|10@0+ (0.4,-180) [-180|229.2] "deg"  ExternalUnit
 SG_ Obj_Width : 63|8@0+ (0.2,0) [0|51] "m"  ExternalUnit
 SG_ Obj_Length : 55|8@0+ (0.2,0) [0|51] "m"  ExternalUnit
 SG_ Obj_ArelLong : 15|11@0+ (0.01,-10) [-10|10.47] "m/s�"  ExternalUnit

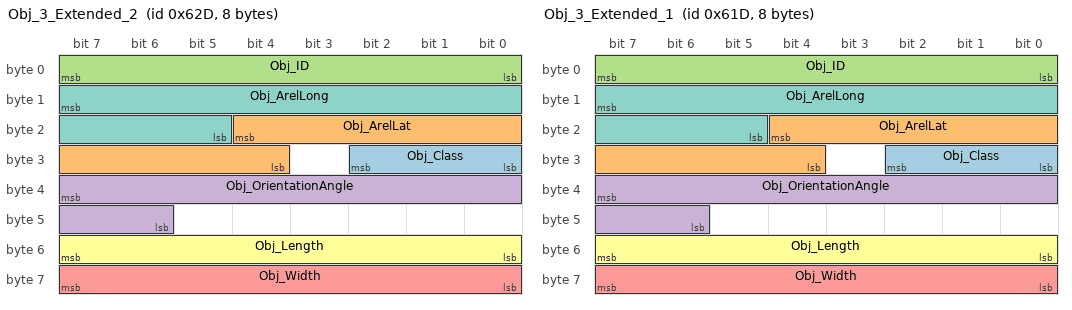
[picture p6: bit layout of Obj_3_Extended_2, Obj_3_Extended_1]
BO_ 1581 Obj_3_Extended_2: 8 SRR308
 SG_ Obj_Class : 26|3@0+ (1,0) [0|7] ""  ExternalUnit
 SG_ Obj_ArelLat : 20|9@0+ (0.01,-2.5) [-2.5|2.61] "m/s�"  ExternalUnit
 SG_ Obj_ID : 7|8@0+ (1,0) [0|255] ""  ExternalUnit
 SG_ Obj_OrientationAngle : 39|10@0+ (0.4,-180) [-180|229.2] "deg"  ExternalUnit
 SG_ Obj_Width : 63|8@0+ (0.2,0) [0|51] "m"  ExternalUnit
 SG_ Obj_Length : 55|8@0+ (0.2,0) [0|51] "m"  ExternalUnit
 SG_ Obj_ArelLong : 15|11@0+ (0.01,-10) [-10|10.47] "m/s�"  ExternalUnit

BO_ 1565 Obj_3_Extended_1: 8 SRR308
 SG_ Obj_Class : 26|3@0+ (1,0) [0|7] ""  ExternalUnit
 SG_ Obj_ArelLat : 20|9@0+ (0.01,-2.5) [-2.5|2.61] "m/s�"  ExternalUnit
 SG_ Obj_ID : 7|8@0+ (1,0) [0|255] ""  ExternalUnit
 SG_ Obj_OrientationAngle : 39|10@0+ (0.4,-180) [-180|229.2] "deg"  ExternalUnit
 SG_ Obj_Width : 63|8@0+ (0.2,0) [0|51] "m"  ExternalUnit
 SG_ Obj_Length : 55|8@0+ (0.2,0) [0|51] "m"  ExternalUnit
 SG_ Obj_ArelLong : 15|11@0+ (0.01,-10) [-10|10.47] "m/s�"  ExternalUnit

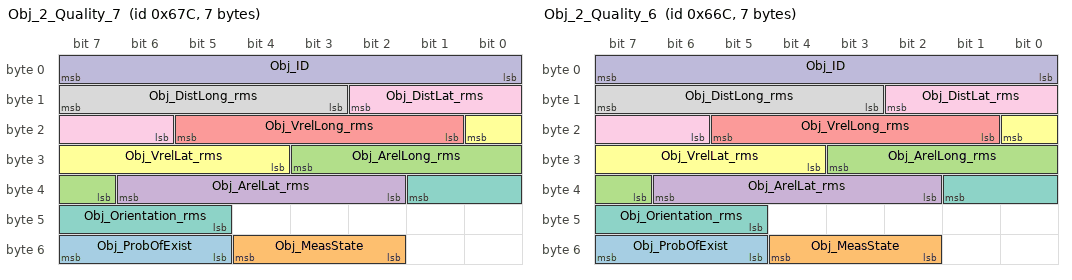
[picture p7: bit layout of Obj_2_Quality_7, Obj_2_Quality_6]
BO_ 1660 Obj_2_Quality_7: 7 SRR308
 SG_ Obj_ProbOfExist : 55|3@0+ (1,0) [0|7] ""  ExternalUnit
 SG_ Obj_MeasState : 52|3@0+ (1,0) [0|7] ""  ExternalUnit
 SG_ Obj_ArelLong_rms : 27|5@0+ (1,0) [0|31] ""  ExternalUnit
 SG_ Obj_ArelLat_rms : 38|5@0+ (1,0) [0|31] ""  ExternalUnit
 SG_ Obj_VrelLong_rms : 21|5@0+ (1,0) [0|31] ""  ExternalUnit
 SG_ Obj_VrelLat_rms : 16|5@0+ (1,0) [0|31] ""  ExternalUnit
 SG_ Obj_Orientation_rms : 33|5@0+ (1,0) [0|31] ""  ExternalUnit
 SG_ Obj_DistLong_rms : 15|5@0+ (1,0) [0|31] ""  ExternalUnit
 SG_ Obj_DistLat_rms : 10|5@0+ (1,0) [0|31] ""  ExternalUnit
 SG_ Obj_ID : 7|8@0+ (1,0) [0|255] ""  ExternalUnit

BO_ 1644 Obj_2_Quality_6: 7 SRR308
 SG_ Obj_ProbOfExist : 55|3@0+ (1,0) [0|7] ""  ExternalUnit
 SG_ Obj_MeasState : 52|3@0+ (1,0) [0|7] ""  ExternalUnit
 SG_ Obj_ArelLong_rms : 27|5@0+ (1,0) [0|31] ""  ExternalUnit
 SG_ Obj_ArelLat_rms : 38|5@0+ (1,0) [0|31] ""  ExternalUnit
 SG_ Obj_VrelLong_rms : 21|5@0+ (1,0) [0|31] ""  ExternalUnit
 SG_ Obj_VrelLat_rms : 16|5@0+ (1,0) [0|31] ""  ExternalUnit
 SG_ Obj_Orientation_rms : 33|5@0+ (1,0) [0|31] ""  ExternalUnit
 SG_ Obj_DistLong_rms : 15|5@0+ (1,0) [0|31] ""  ExternalUnit
 SG_ Obj_DistLat_rms : 10|5@0+ (1,0) [0|31] ""  ExternalUnit
 SG_ Obj_ID : 7|8@0+ (1,0) [0|255] ""  ExternalUnit

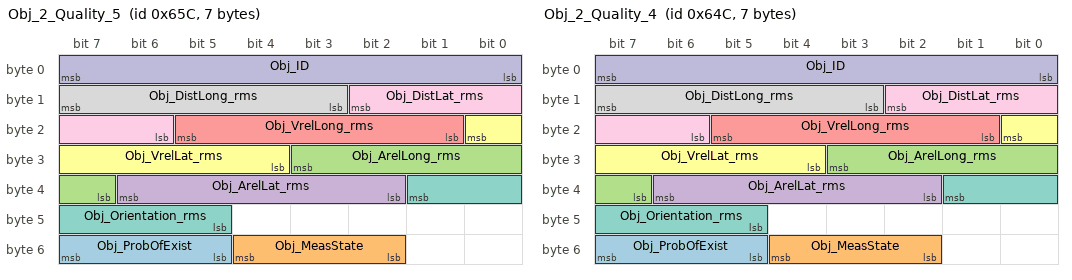
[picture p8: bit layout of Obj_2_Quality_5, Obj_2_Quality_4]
BO_ 1628 Obj_2_Quality_5: 7 SRR308
 SG_ Obj_ProbOfExist : 55|3@0+ (1,0) [0|7] ""  ExternalUnit
 SG_ Obj_MeasState : 52|3@0+ (1,0) [0|7] ""  ExternalUnit
 SG_ Obj_ArelLong_rms : 27|5@0+ (1,0) [0|31] ""  ExternalUnit
 SG_ Obj_ArelLat_rms : 38|5@0+ (1,0) [0|31] ""  ExternalUnit
 SG_ Obj_VrelLong_rms : 21|5@0+ (1,0) [0|31] ""  ExternalUnit
 SG_ Obj_VrelLat_rms : 16|5@0+ (1,0) [0|31] ""  ExternalUnit
 SG_ Obj_Orientation_rms : 33|5@0+ (1,0) [0|31] ""  ExternalUnit
 SG_ Obj_DistLong_rms : 15|5@0+ (1,0) [0|31] ""  ExternalUnit
 SG_ Obj_DistLat_rms : 10|5@0+ (1,0) [0|31] ""  ExternalUnit
 SG_ Obj_ID : 7|8@0+ (1,0) [0|255] ""  ExternalUnit

BO_ 1612 Obj_2_Quality_4: 7 SRR308
 SG_ Obj_ProbOfExist : 55|3@0+ (1,0) [0|7] ""  ExternalUnit
 SG_ Obj_MeasState : 52|3@0+ (1,0) [0|7] ""  ExternalUnit
 SG_ Obj_ArelLong_rms : 27|5@0+ (1,0) [0|31] ""  ExternalUnit
 SG_ Obj_ArelLat_rms : 38|5@0+ (1,0) [0|31] ""  ExternalUnit
 SG_ Obj_VrelLong_rms : 21|5@0+ (1,0) [0|31] ""  ExternalUnit
 SG_ Obj_VrelLat_rms : 16|5@0+ (1,0) [0|31] ""  ExternalUnit
 SG_ Obj_Orientation_rms : 33|5@0+ (1,0) [0|31] ""  ExternalUnit
 SG_ Obj_DistLong_rms : 15|5@0+ (1,0) [0|31] ""  ExternalUnit
 SG_ Obj_DistLat_rms : 10|5@0+ (1,0) [0|31] ""  ExternalUnit
 SG_ Obj_ID : 7|8@0+ (1,0) [0|255] ""  ExternalUnit

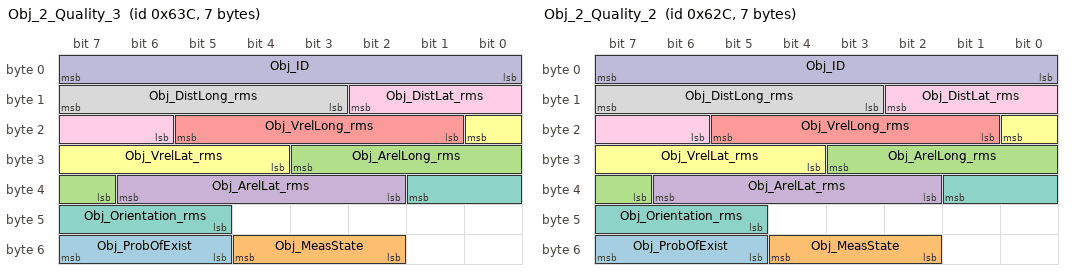
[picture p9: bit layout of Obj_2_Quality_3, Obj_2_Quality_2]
BO_ 1596 Obj_2_Quality_3: 7 SRR308
 SG_ Obj_ProbOfExist : 55|3@0+ (1,0) [0|7] ""  ExternalUnit
 SG_ Obj_MeasState : 52|3@0+ (1,0) [0|7] ""  ExternalUnit
 SG_ Obj_ArelLong_rms : 27|5@0+ (1,0) [0|31] ""  ExternalUnit
 SG_ Obj_ArelLat_rms : 38|5@0+ (1,0) [0|31] ""  ExternalUnit
 SG_ Obj_VrelLong_rms : 21|5@0+ (1,0) [0|31] ""  ExternalUnit
 SG_ Obj_VrelLat_rms : 16|5@0+ (1,0) [0|31] ""  ExternalUnit
 SG_ Obj_Orientation_rms : 33|5@0+ (1,0) [0|31] ""  ExternalUnit
 SG_ Obj_DistLong_rms : 15|5@0+ (1,0) [0|31] ""  ExternalUnit
 SG_ Obj_DistLat_rms : 10|5@0+ (1,0) [0|31] ""  ExternalUnit
 SG_ Obj_ID : 7|8@0+ (1,0) [0|255] ""  ExternalUnit

BO_ 1580 Obj_2_Quality_2: 7 SRR308
 SG_ Obj_ProbOfExist : 55|3@0+ (1,0) [0|7] ""  ExternalUnit
 SG_ Obj_MeasState : 52|3@0+ (1,0) [0|7] ""  ExternalUnit
 SG_ Obj_ArelLong_rms : 27|5@0+ (1,0) [0|31] ""  ExternalUnit
 SG_ Obj_ArelLat_rms : 38|5@0+ (1,0) [0|31] ""  ExternalUnit
 SG_ Obj_VrelLong_rms : 21|5@0+ (1,0) [0|31] ""  ExternalUnit
 SG_ Obj_VrelLat_rms : 16|5@0+ (1,0) [0|31] ""  ExternalUnit
 SG_ Obj_Orientation_rms : 33|5@0+ (1,0) [0|31] ""  ExternalUnit
 SG_ Obj_DistLong_rms : 15|5@0+ (1,0) [0|31] ""  ExternalUnit
 SG_ Obj_DistLat_rms : 10|5@0+ (1,0) [0|31] ""  ExternalUnit
 SG_ Obj_ID : 7|8@0+ (1,0) [0|255] ""  ExternalUnit

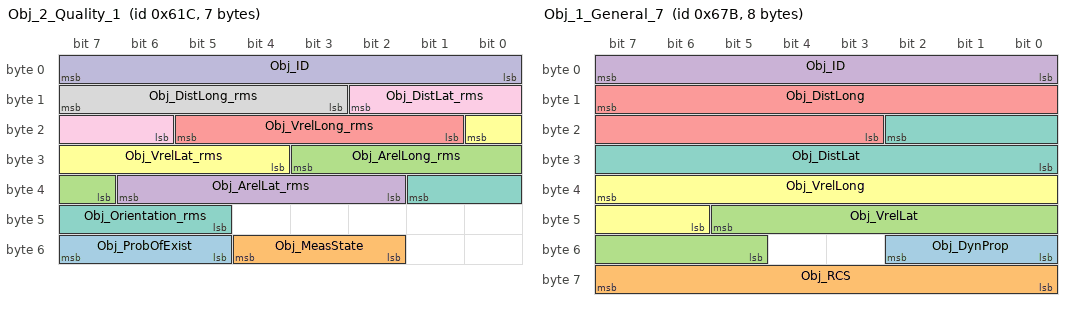
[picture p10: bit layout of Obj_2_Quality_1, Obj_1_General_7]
BO_ 1564 Obj_2_Quality_1: 7 SRR308
 SG_ Obj_ProbOfExist : 55|3@0+ (1,0) [0|7] ""  ExternalUnit
 SG_ Obj_MeasState : 52|3@0+ (1,0) [0|7] ""  ExternalUnit
 SG_ Obj_ArelLong_rms : 27|5@0+ (1,0) [0|31] ""  ExternalUnit
 SG_ Obj_ArelLat_rms : 38|5@0+ (1,0) [0|31] ""  ExternalUnit
 SG_ Obj_VrelLong_rms : 21|5@0+ (1,0) [0|31] ""  ExternalUnit
 SG_ Obj_VrelLat_rms : 16|5@0+ (1,0) [0|31] ""  ExternalUnit
 SG_ Obj_Orientation_rms : 33|5@0+ (1,0) [0|31] ""  ExternalUnit
 SG_ Obj_DistLong_rms : 15|5@0+ (1,0) [0|31] ""  ExternalUnit
 SG_ Obj_DistLat_rms : 10|5@0+ (1,0) [0|31] ""  ExternalUnit
 SG_ Obj_ID : 7|8@0+ (1,0) [0|255] ""  ExternalUnit

BO_ 1659 Obj_1_General_7: 8 SRR308
 SG_ Obj_DynProp : 50|3@0+ (1,0) [0|7] ""  ExternalUnit
 SG_ Obj_RCS : 63|8@0+ (0.5,-64) [-64|63.5] "dBm�"  ExternalUnit
 SG_ Obj_VrelLat : 45|9@0+ (0.25,-64) [-64|63.75] "m/s"  ExternalUnit
 SG_ Obj_ID : 7|8@0+ (1,0) [0|255] ""  ExternalUnit
 SG_ Obj_DistLong : 15|13@0+ (0.2,-500) [-500|1138.2] "m"  ExternalUnit
 SG_ Obj_VrelLong : 39|10@0+ (0.25,-128) [-128|127.75] "m/s"  ExternalUnit
 SG_ Obj_DistLat : 18|11@0+ (0.2,-204.6) [-204.6|204.8] "m"  ExternalUnit

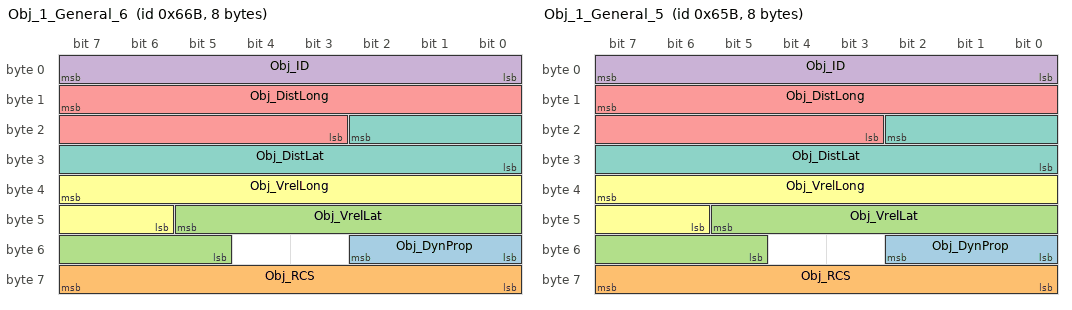
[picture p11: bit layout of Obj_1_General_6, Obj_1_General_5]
BO_ 1643 Obj_1_General_6: 8 SRR308
 SG_ Obj_DynProp : 50|3@0+ (1,0) [0|7] ""  ExternalUnit
 SG_ Obj_RCS : 63|8@0+ (0.5,-64) [-64|63.5] "dBm�"  ExternalUnit
 SG_ Obj_VrelLat : 45|9@0+ (0.25,-64) [-64|63.75] "m/s"  ExternalUnit
 SG_ Obj_ID : 7|8@0+ (1,0) [0|255] ""  ExternalUnit
 SG_ Obj_DistLong : 15|13@0+ (0.2,-500) [-500|1138.2] "m"  ExternalUnit
 SG_ Obj_VrelLong : 39|10@0+ (0.25,-128) [-128|127.75] "m/s"  ExternalUnit
 SG_ Obj_DistLat : 18|11@0+ (0.2,-204.6) [-204.6|204.8] "m"  ExternalUnit

BO_ 1627 Obj_1_General_5: 8 SRR308
 SG_ Obj_DynProp : 50|3@0+ (1,0) [0|7] ""  ExternalUnit
 SG_ Obj_RCS : 63|8@0+ (0.5,-64) [-64|63.5] "dBm�"  ExternalUnit
 SG_ Obj_VrelLat : 45|9@0+ (0.25,-64) [-64|63.75] "m/s"  ExternalUnit
 SG_ Obj_ID : 7|8@0+ (1,0) [0|255] ""  ExternalUnit
 SG_ Obj_DistLong : 15|13@0+ (0.2,-500) [-500|1138.2] "m"  ExternalUnit
 SG_ Obj_VrelLong : 39|10@0+ (0.25,-128) [-128|127.75] "m/s"  ExternalUnit
 SG_ Obj_DistLat : 18|11@0+ (0.2,-204.6) [-204.6|204.8] "m"  ExternalUnit

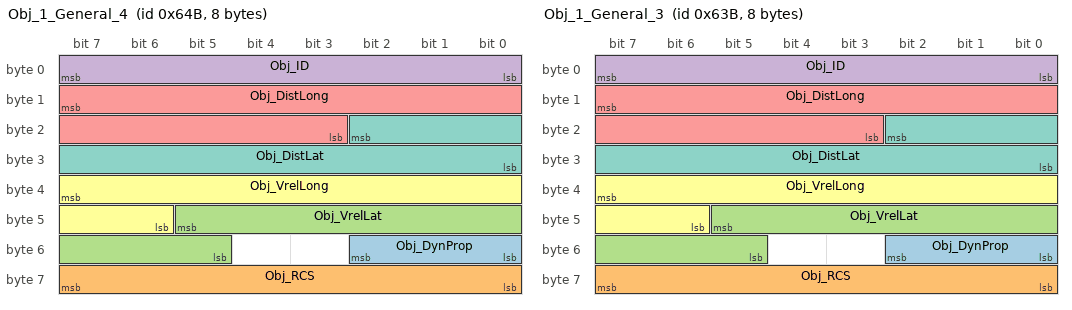
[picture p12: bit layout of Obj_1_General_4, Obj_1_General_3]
BO_ 1611 Obj_1_General_4: 8 SRR308
 SG_ Obj_DynProp : 50|3@0+ (1,0) [0|7] ""  ExternalUnit
 SG_ Obj_RCS : 63|8@0+ (0.5,-64) [-64|63.5] "dBm�"  ExternalUnit
 SG_ Obj_VrelLat : 45|9@0+ (0.25,-64) [-64|63.75] "m/s"  ExternalUnit
 SG_ Obj_ID : 7|8@0+ (1,0) [0|255] ""  ExternalUnit
 SG_ Obj_DistLong : 15|13@0+ (0.2,-500) [-500|1138.2] "m"  ExternalUnit
 SG_ Obj_VrelLong : 39|10@0+ (0.25,-128) [-128|127.75] "m/s"  ExternalUnit
 SG_ Obj_DistLat : 18|11@0+ (0.2,-204.6) [-204.6|204.8] "m"  ExternalUnit

BO_ 1595 Obj_1_General_3: 8 SRR308
 SG_ Obj_DynProp : 50|3@0+ (1,0) [0|7] ""  ExternalUnit
 SG_ Obj_RCS : 63|8@0+ (0.5,-64) [-64|63.5] "dBm�"  ExternalUnit
 SG_ Obj_VrelLat : 45|9@0+ (0.25,-64) [-64|63.75] "m/s"  ExternalUnit
 SG_ Obj_ID : 7|8@0+ (1,0) [0|255] ""  ExternalUnit
 SG_ Obj_DistLong : 15|13@0+ (0.2,-500) [-500|1138.2] "m"  ExternalUnit
 SG_ Obj_VrelLong : 39|10@0+ (0.25,-128) [-128|127.75] "m/s"  ExternalUnit
 SG_ Obj_DistLat : 18|11@0+ (0.2,-204.6) [-204.6|204.8] "m"  ExternalUnit

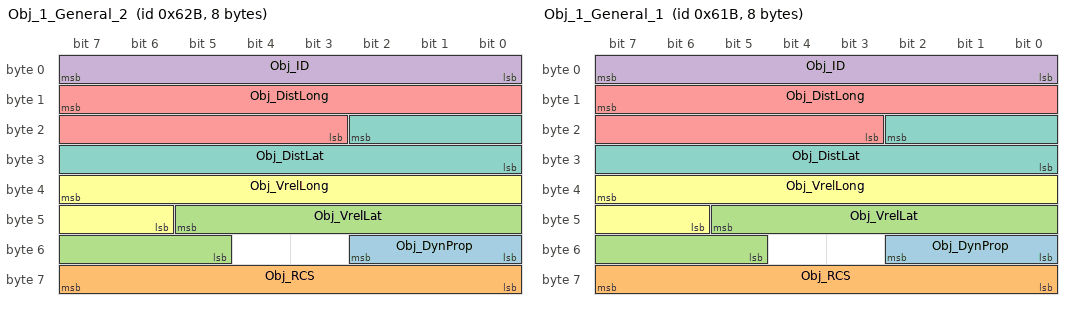
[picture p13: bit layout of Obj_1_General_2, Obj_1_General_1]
BO_ 1579 Obj_1_General_2: 8 SRR308
 SG_ Obj_DynProp : 50|3@0+ (1,0) [0|7] ""  ExternalUnit
 SG_ Obj_RCS : 63|8@0+ (0.5,-64) [-64|63.5] "dBm�"  ExternalUnit
 SG_ Obj_VrelLat : 45|9@0+ (0.25,-64) [-64|63.75] "m/s"  ExternalUnit
 SG_ Obj_ID : 7|8@0+ (1,0) [0|255] ""  ExternalUnit
 SG_ Obj_DistLong : 15|13@0+ (0.2,-500) [-500|1138.2] "m"  ExternalUnit
 SG_ Obj_VrelLong : 39|10@0+ (0.25,-128) [-128|127.75] "m/s"  ExternalUnit
 SG_ Obj_DistLat : 18|11@0+ (0.2,-204.6) [-204.6|204.8] "m"  ExternalUnit

BO_ 1563 Obj_1_General_1: 8 SRR308
 SG_ Obj_DynProp : 50|3@0+ (1,0) [0|7] ""  ExternalUnit
 SG_ Obj_RCS : 63|8@0+ (0.5,-64) [-64|63.5] "dBm�"  ExternalUnit
 SG_ Obj_VrelLat : 45|9@0+ (0.25,-64) [-64|63.75] "m/s"  ExternalUnit
 SG_ Obj_ID : 7|8@0+ (1,0) [0|255] ""  ExternalUnit
 SG_ Obj_DistLong : 15|13@0+ (0.2,-500) [-500|1138.2] "m"  ExternalUnit
 SG_ Obj_VrelLong : 39|10@0+ (0.25,-128) [-128|127.75] "m/s"  ExternalUnit
 SG_ Obj_DistLat : 18|11@0+ (0.2,-204.6) [-204.6|204.8] "m"  ExternalUnit

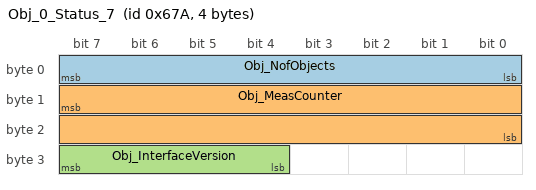
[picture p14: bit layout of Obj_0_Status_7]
BO_ 1658 Obj_0_Status_7: 4 SRR308
 SG_ Obj_NofObjects : 7|8@0+ (1,0) [0|255] "1"  ExternalUnit
 SG_ Obj_MeasCounter : 15|16@0+ (1,0) [0|65535] ""  ExternalUnit
 SG_ Obj_InterfaceVersion : 31|4@0+ (1,0) [0|16] ""  ExternalUnit

CM_ BO_ 881 "Device movement yaw rate";
CM_ SG_ 881 RadarDevice_YawRate "Yaw rate of the radar unit";
CM_ BO_ 865 "Device movement yaw rate";
CM_ SG_ 865 RadarDevice_YawRate "Yaw rate of the radar unit";
CM_ BO_ 849 "Device movement yaw rate";
CM_ SG_ 849 RadarDevice_YawRate "Yaw rate of the radar unit";
CM_ BO_ 833 "Device movement yaw rate";
CM_ SG_ 833 RadarDevice_YawRate "Yaw rate of the radar unit";
CM_ BO_ 817 "Device movement yaw rate";
CM_ SG_ 817 RadarDevice_YawRate "Yaw rate of the radar unit";
CM_ BO_ 801 "Device movement yaw rate";
CM_ SG_ 801 RadarDevice_YawRate "Yaw rate of the radar unit";
CM_ BO_ 785 "Device movement yaw rate";
CM_ SG_ 785 RadarDevice_YawRate "Yaw rate of the radar unit";
CM_ BO_ 1904 "Firmware version";
CM_ SG_ 1904 Version_MajorRelease "Major Release Number";
CM_ SG_ 1904 Version_MinorRelease "Minor Release Number";
CM_ SG_ 1904 Version_PatchLevel "Patch Level";
CM_ BO_ 1888 "Firmware version";
CM_ SG_ 1888 Version_MajorRelease "Major Release Number";
CM_ SG_ 1888 Version_MinorRelease "Minor Release Number";
CM_ SG_ 1888 Version_PatchLevel "Patch Level";
CM_ BO_ 1872 "Firmware version";
CM_ SG_ 1872 Version_MajorRelease "Major Release Number";
CM_ SG_ 1872 Version_MinorRelease "Minor Release Number";
CM_ SG_ 1872 Version_PatchLevel "Patch Level";
CM_ BO_ 1856 "Firmware version";
CM_ SG_ 1856 Version_MajorRelease "Major Release Number";
CM_ SG_ 1856 Version_MinorRelease "Minor Release Number";
CM_ SG_ 1856 Version_PatchLevel "Patch Level";
CM_ BO_ 1840 "Firmware version";
CM_ SG_ 1840 Version_MajorRelease "Major Release Number";
CM_ SG_ 1840 Version_MinorRelease "Minor Release Number";
CM_ SG_ 1840 Version_PatchLevel "Patch Level";
CM_ BO_ 1824 "Firmware version";
CM_ SG_ 1824 Version_MajorRelease "Major Release Number";
CM_ SG_ 1824 Version_MinorRelease "Minor Release Number";
CM_ SG_ 1824 Version_PatchLevel "Patch Level";
CM_ BO_ 1808 "Firmware version";
CM_ SG_ 1808 Version_MajorRelease "Major Release Number";
CM_ SG_ 1808 Version_MinorRelease "Minor Release Number";
CM_ SG_ 1808 Version_PatchLevel "Patch Level";
CM_ BO_ 880 "Device movement speed";
CM_ SG_ 880 RadarDevice_Speed "Speed of the radar unit";
CM_ SG_ 880 RadarDevice_SpeedDirection "Speed direction of the radar unit";
CM_ BO_ 864 "Device movement speed";
CM_ SG_ 864 RadarDevice_Speed "Speed of the radar unit";
CM_ SG_ 864 RadarDevice_SpeedDirection "Speed direction of the radar unit";
CM_ BO_ 848 "Device movement speed";
CM_ SG_ 848 RadarDevice_Speed "Speed of the radar unit";
CM_ SG_ 848 RadarDevice_SpeedDirection "Speed direction of the radar unit";
CM_ BO_ 832 "Device movement speed";
CM_ SG_ 832 RadarDevice_Speed "Speed of the radar unit";
CM_ SG_ 832 RadarDevice_SpeedDirection "Speed direction of the radar unit";
CM_ BO_ 816 "Device movement speed";
CM_ SG_ 816 RadarDevice_Speed "Speed of the radar unit";
CM_ SG_ 816 RadarDevice_SpeedDirection "Speed direction of the radar unit";
CM_ BO_ 800 "Device movement speed";
CM_ SG_ 800 RadarDevice_Speed "Speed of the radar unit";
CM_ SG_ 800 RadarDevice_SpeedDirection "Speed direction of the radar unit";
CM_ BO_ 784 "Device movement speed";
CM_ SG_ 784 RadarDevice_Speed "Speed of the radar unit";
CM_ SG_ 784 RadarDevice_SpeedDirection "Speed direction of the radar unit";
CM_ BO_ 625 "Radar configuration status";
CM_ SG_ 625 RadarState_InvalidClusters "Status of invalid clusters output";
CM_ SG_ 625 RadarState_SortIndex "Current sorting of object list";
CM_ SG_ 625 RadarState_RCS_Threshold "Current sensitivity mode";
CM_ SG_ 625 RadarState_CtrlRelayCfg "Status of control relay message output";
CM_ SG_ 625 RadarState_SendQualityCfg "Status of quality information output";
CM_ SG_ 625 RadarState_SendExtInfoCfg "Status of extended information output";
CM_ SG_ 625 RadarState_MotionRxState "Status of motion input signals";
CM_ SG_ 625 RadarState_SensorID "Sensor ID (0 to 7)";
CM_ SG_ 625 RadarState_OutputTypeCfg "Current output list type";
CM_ SG_ 625 RadarState_RadarPowerCfg "Radar Tx output level (Tx attenuation)";
CM_ SG_ 625 RadarState_NVMReadStatus "Gives the status of reading the radar configuration from EEPROM";
CM_ SG_ 625 RadarState_NVMwriteStatus "Gives the status of writing the radar configuration from EEPROM";
CM_ SG_ 625 RadarState_MaxDistanceCfg "Currently configured maximum distance of far scan";
CM_ BO_ 609 "Radar configuration status";
CM_ SG_ 609 RadarState_InvalidClusters "Status of invalid clusters output";
CM_ SG_ 609 RadarState_SortIndex "Current sorting of object list";
CM_ SG_ 609 RadarState_RCS_Threshold "Current sensitivity mode";
CM_ SG_ 609 RadarState_CtrlRelayCfg "Status of control relay message output";
CM_ SG_ 609 RadarState_SendQualityCfg "Status of quality information output";
CM_ SG_ 609 RadarState_SendExtInfoCfg "Status of extended information output";
CM_ SG_ 609 RadarState_MotionRxState "Status of motion input signals";
CM_ SG_ 609 RadarState_SensorID "Sensor ID (0 to 7)";
CM_ SG_ 609 RadarState_OutputTypeCfg "Current output list type";
CM_ SG_ 609 RadarState_RadarPowerCfg "Radar Tx output level (Tx attenuation)";
CM_ SG_ 609 RadarState_NVMReadStatus "Gives the status of reading the radar configuration from EEPROM";
CM_ SG_ 609 RadarState_NVMwriteStatus "Gives the status of writing the radar configuration from EEPROM";
CM_ SG_ 609 RadarState_MaxDistanceCfg "Currently configured maximum distance of far scan";
CM_ BO_ 593 "Radar configuration status";
CM_ SG_ 593 RadarState_InvalidClusters "Status of invalid clusters output";
CM_ SG_ 593 RadarState_SortIndex "Current sorting of object list";
CM_ SG_ 593 RadarState_RCS_Threshold "Current sensitivity mode";
CM_ SG_ 593 RadarState_CtrlRelayCfg "Status of control relay message output";
CM_ SG_ 593 RadarState_SendQualityCfg "Status of quality information output";
CM_ SG_ 593 RadarState_SendExtInfoCfg "Status of extended information output";
CM_ SG_ 593 RadarState_MotionRxState "Status of motion input signals";
CM_ SG_ 593 RadarState_SensorID "Sensor ID (0 to 7)";
CM_ SG_ 593 RadarState_OutputTypeCfg "Current output list type";
CM_ SG_ 593 RadarState_RadarPowerCfg "Radar Tx output level (Tx attenuation)";
CM_ SG_ 593 RadarState_NVMReadStatus "Gives the status of reading the radar configuration from EEPROM";
CM_ SG_ 593 RadarState_NVMwriteStatus "Gives the status of writing the radar configuration from EEPROM";
CM_ SG_ 593 RadarState_MaxDistanceCfg "Currently configured maximum distance of far scan";
CM_ BO_ 577 "Radar configuration status";
CM_ SG_ 577 RadarState_InvalidClusters "Status of invalid clusters output";
CM_ SG_ 577 RadarState_SortIndex "Current sorting of object list";
CM_ SG_ 577 RadarState_RCS_Threshold "Current sensitivity mode";
CM_ SG_ 577 RadarState_CtrlRelayCfg "Status of control relay message output";
CM_ SG_ 577 RadarState_SendQualityCfg "Status of quality information output";
CM_ SG_ 577 RadarState_SendExtInfoCfg "Status of extended information output";
CM_ SG_ 577 RadarState_MotionRxState "Status of motion input signals";
CM_ SG_ 577 RadarState_SensorID "Sensor ID (0 to 7)";
CM_ SG_ 577 RadarState_OutputTypeCfg "Current output list type";
CM_ SG_ 577 RadarState_RadarPowerCfg "Radar Tx output level (Tx attenuation)";
CM_ SG_ 577 RadarState_NVMReadStatus "Gives the status of reading the radar configuration from EEPROM";
CM_ SG_ 577 RadarState_NVMwriteStatus "Gives the status of writing the radar configuration from EEPROM";
CM_ SG_ 577 RadarState_MaxDistanceCfg "Currently configured maximum distance of far scan";
CM_ BO_ 561 "Radar configuration status";
CM_ SG_ 561 RadarState_InvalidClusters "Status of invalid clusters output";
CM_ SG_ 561 RadarState_SortIndex "Current sorting of object list";
CM_ SG_ 561 RadarState_RCS_Threshold "Current sensitivity mode";
CM_ SG_ 561 RadarState_CtrlRelayCfg "Status of control relay message output";
CM_ SG_ 561 RadarState_SendQualityCfg "Status of quality information output";
CM_ SG_ 561 RadarState_SendExtInfoCfg "Status of extended information output";
CM_ SG_ 561 RadarState_MotionRxState "Status of motion input signals";
CM_ SG_ 561 RadarState_SensorID "Sensor ID (0 to 7)";
CM_ SG_ 561 RadarState_OutputTypeCfg "Current output list type";
CM_ SG_ 561 RadarState_RadarPowerCfg "Radar Tx output level (Tx attenuation)";
CM_ SG_ 561 RadarState_NVMReadStatus "Gives the status of reading the radar configuration from EEPROM";
CM_ SG_ 561 RadarState_NVMwriteStatus "Gives the status of writing the radar configuration from EEPROM";
CM_ SG_ 561 RadarState_MaxDistanceCfg "Currently configured maximum distance of far scan";
CM_ BO_ 545 "Radar configuration status";
CM_ SG_ 545 RadarState_InvalidClusters "Status of invalid clusters output";
CM_ SG_ 545 RadarState_SortIndex "Current sorting of object list";
CM_ SG_ 545 RadarState_RCS_Threshold "Current sensitivity mode";
CM_ SG_ 545 RadarState_CtrlRelayCfg "Status of control relay message output";
CM_ SG_ 545 RadarState_SendQualityCfg "Status of quality information output";
CM_ SG_ 545 RadarState_SendExtInfoCfg "Status of extended information output";
CM_ SG_ 545 RadarState_MotionRxState "Status of motion input signals";
CM_ SG_ 545 RadarState_SensorID "Sensor ID (0 to 7)";
CM_ SG_ 545 RadarState_OutputTypeCfg "Current output list type";
CM_ SG_ 545 RadarState_RadarPowerCfg "Radar Tx output level (Tx attenuation)";
CM_ SG_ 545 RadarState_NVMReadStatus "Gives the status of reading the radar configuration from EEPROM";
CM_ SG_ 545 RadarState_NVMwriteStatus "Gives the status of writing the radar configuration from EEPROM";
CM_ SG_ 545 RadarState_MaxDistanceCfg "Currently configured maximum distance of far scan";
CM_ BO_ 529 "Radar configuration status";
CM_ SG_ 529 RadarState_InvalidClusters "Status of invalid clusters output";
CM_ SG_ 529 RadarState_SortIndex "Current sorting of object list";
CM_ SG_ 529 RadarState_RCS_Threshold "Current sensitivity mode";
CM_ SG_ 529 RadarState_CtrlRelayCfg "Status of control relay message output";
CM_ SG_ 529 RadarState_SendQualityCfg "Status of quality information output";
CM_ SG_ 529 RadarState_SendExtInfoCfg "Status of extended information output";
CM_ SG_ 529 RadarState_MotionRxState "Status of motion input signals";
CM_ SG_ 529 RadarState_SensorID "Sensor ID (0 to 7)";
CM_ SG_ 529 RadarState_OutputTypeCfg "Current output list type";
CM_ SG_ 529 RadarState_RadarPowerCfg "Radar Tx output level (Tx attenuation)";
CM_ SG_ 529 RadarState_NVMReadStatus "Gives the status of reading the radar configuration from EEPROM";
CM_ SG_ 529 RadarState_NVMwriteStatus "Gives the status of writing the radar configuration from EEPROM";
CM_ SG_ 529 RadarState_MaxDistanceCfg "Currently configured maximum distance of far scan";
CM_ BO_ 624 "Radar configuration";
CM_ SG_ 624 RadarCfg_InvalidClusters_valid "Allows changing the InvalidClusters parameter";
CM_ SG_ 624 RadarCfg_InvalidClusters "Enables selective output of invalid clusters";
CM_ SG_ 624 RadarCfg_RCS_Threshold_Valid "Allows changing the RCS_Threshold parameter";
CM_ SG_ 624 RadarCfg_RCS_Threshold "Standard or high sensitivity for cluster list output";
CM_ SG_ 624 RadarCfg_StoreInNVM_valid "Allows changing the StoreInNvm parameter";
CM_ SG_ 624 RadarCfg_SortIndex_valid "Allows changing the SortIndex parameter";
CM_ SG_ 624 RadarCfg_SortIndex "Object sort index";
CM_ SG_ 624 RadarCfg_StoreInNVM "Store configuration in Nvm";
CM_ SG_ 624 RadarCfg_SendExtInfo_valid "Allows changing the SendExtInfo parameter";
CM_ SG_ 624 RadarCfg_SendExtInfo "Enables output of extended message";
CM_ SG_ 624 RadarCfg_CtrlRelay_valid "Allows changing the CtrlRelay parameter";
CM_ SG_ 624 RadarCfg_CtrlRelay "Enables output of CtrlRelay message if CollDet is active";
CM_ SG_ 624 RadarCfg_SendQuality_valid "Allows changing the SendQuality parameter";
CM_ SG_ 624 RadarCfg_SendQuality "Enables output of quality message";
CM_ SG_ 624 RadarCfg_MaxDistance_valid "Allows changing the MaxDistance parameter";
CM_ SG_ 624 RadarCfg_OutputType_valid "Allows changing the OutputType parameter";
CM_ SG_ 624 RadarCfg_SensorID_valid "Allows changing the SensorId parameter";
CM_ SG_ 624 RadarCfg_MaxDistance "Maximum distance of far scan";
CM_ SG_ 624 RadarCfg_OutputType "Data output type";
CM_ SG_ 624 RadarCfg_SensorID "Sensor ID (0 to 7)";
CM_ BO_ 608 "Radar configuration";
CM_ SG_ 608 RadarCfg_InvalidClusters_valid "Allows changing the InvalidClusters parameter";
CM_ SG_ 608 RadarCfg_InvalidClusters "Enables selective output of invalid clusters";
CM_ SG_ 608 RadarCfg_RCS_Threshold_Valid "Allows changing the RCS_Threshold parameter";
CM_ SG_ 608 RadarCfg_RCS_Threshold "Standard or high sensitivity for cluster list output";
CM_ SG_ 608 RadarCfg_StoreInNVM_valid "Allows changing the StoreInNvm parameter";
CM_ SG_ 608 RadarCfg_SortIndex_valid "Allows changing the SortIndex parameter";
CM_ SG_ 608 RadarCfg_SortIndex "Object sort index";
CM_ SG_ 608 RadarCfg_StoreInNVM "Store configuration in Nvm";
CM_ SG_ 608 RadarCfg_SendExtInfo_valid "Allows changing the SendExtInfo parameter";
CM_ SG_ 608 RadarCfg_SendExtInfo "Enables output of extended message";
CM_ SG_ 608 RadarCfg_CtrlRelay_valid "Allows changing the CtrlRelay parameter";
CM_ SG_ 608 RadarCfg_CtrlRelay "Enables output of CtrlRelay message if CollDet is active";
CM_ SG_ 608 RadarCfg_SendQuality_valid "Allows changing the SendQuality parameter";
CM_ SG_ 608 RadarCfg_SendQuality "Enables output of quality message";
CM_ SG_ 608 RadarCfg_MaxDistance_valid "Allows changing the MaxDistance parameter";
CM_ SG_ 608 RadarCfg_OutputType_valid "Allows changing the OutputType parameter";
CM_ SG_ 608 RadarCfg_SensorID_valid "Allows changing the SensorId parameter";
CM_ SG_ 608 RadarCfg_MaxDistance "Maximum distance of far scan";
CM_ SG_ 608 RadarCfg_OutputType "Data output type";
CM_ SG_ 608 RadarCfg_SensorID "Sensor ID (0 to 7)";
CM_ BO_ 592 "Radar configuration";
CM_ SG_ 592 RadarCfg_InvalidClusters_valid "Allows changing the InvalidClusters parameter";
CM_ SG_ 592 RadarCfg_InvalidClusters "Enables selective output of invalid clusters";
CM_ SG_ 592 RadarCfg_RCS_Threshold_Valid "Allows changing the RCS_Threshold parameter";
CM_ SG_ 592 RadarCfg_RCS_Threshold "Standard or high sensitivity for cluster list output";
CM_ SG_ 592 RadarCfg_StoreInNVM_valid "Allows changing the StoreInNvm parameter";
CM_ SG_ 592 RadarCfg_SortIndex_valid "Allows changing the SortIndex parameter";
CM_ SG_ 592 RadarCfg_SortIndex "Object sort index";
CM_ SG_ 592 RadarCfg_StoreInNVM "Store configuration in Nvm";
CM_ SG_ 592 RadarCfg_SendExtInfo_valid "Allows changing the SendExtInfo parameter";
CM_ SG_ 592 RadarCfg_SendExtInfo "Enables output of extended message";
CM_ SG_ 592 RadarCfg_CtrlRelay_valid "Allows changing the CtrlRelay parameter";
CM_ SG_ 592 RadarCfg_CtrlRelay "Enables output of CtrlRelay message if CollDet is active";
CM_ SG_ 592 RadarCfg_SendQuality_valid "Allows changing the SendQuality parameter";
CM_ SG_ 592 RadarCfg_SendQuality "Enables output of quality message";
CM_ SG_ 592 RadarCfg_MaxDistance_valid "Allows changing the MaxDistance parameter";
CM_ SG_ 592 RadarCfg_OutputType_valid "Allows changing the OutputType parameter";
CM_ SG_ 592 RadarCfg_SensorID_valid "Allows changing the SensorId parameter";
CM_ SG_ 592 RadarCfg_MaxDistance "Maximum distance of far scan";
CM_ SG_ 592 RadarCfg_OutputType "Data output type";
CM_ SG_ 592 RadarCfg_SensorID "Sensor ID (0 to 7)";
CM_ BO_ 576 "Radar configuration";
CM_ SG_ 576 RadarCfg_InvalidClusters_valid "Allows changing the InvalidClusters parameter";
CM_ SG_ 576 RadarCfg_InvalidClusters "Enables selective output of invalid clusters";
CM_ SG_ 576 RadarCfg_RCS_Threshold_Valid "Allows changing the RCS_Threshold parameter";
CM_ SG_ 576 RadarCfg_RCS_Threshold "Standard or high sensitivity for cluster list output";
CM_ SG_ 576 RadarCfg_StoreInNVM_valid "Allows changing the StoreInNvm parameter";
CM_ SG_ 576 RadarCfg_SortIndex_valid "Allows changing the SortIndex parameter";
CM_ SG_ 576 RadarCfg_SortIndex "Object sort index";
CM_ SG_ 576 RadarCfg_StoreInNVM "Store configuration in Nvm";
CM_ SG_ 576 RadarCfg_SendExtInfo_valid "Allows changing the SendExtInfo parameter";
CM_ SG_ 576 RadarCfg_SendExtInfo "Enables output of extended message";
CM_ SG_ 576 RadarCfg_CtrlRelay_valid "Allows changing the CtrlRelay parameter";
CM_ SG_ 576 RadarCfg_CtrlRelay "Enables output of CtrlRelay message if CollDet is active";
CM_ SG_ 576 RadarCfg_SendQuality_valid "Allows changing the SendQuality parameter";
CM_ SG_ 576 RadarCfg_SendQuality "Enables output of quality message";
CM_ SG_ 576 RadarCfg_MaxDistance_valid "Allows changing the MaxDistance parameter";
CM_ SG_ 576 RadarCfg_OutputType_valid "Allows changing the OutputType parameter";
CM_ SG_ 576 RadarCfg_SensorID_valid "Allows changing the SensorId parameter";
CM_ SG_ 576 RadarCfg_MaxDistance "Maximum distance of far scan";
CM_ SG_ 576 RadarCfg_OutputType "Data output type";
CM_ SG_ 576 RadarCfg_SensorID "Sensor ID (0 to 7)";
CM_ BO_ 560 "Radar configuration";
CM_ SG_ 560 RadarCfg_InvalidClusters_valid "Allows changing the InvalidClusters parameter";
CM_ SG_ 560 RadarCfg_InvalidClusters "Enables selective output of invalid clusters";
CM_ SG_ 560 RadarCfg_RCS_Threshold_Valid "Allows changing the RCS_Threshold parameter";
CM_ SG_ 560 RadarCfg_RCS_Threshold "Standard or high sensitivity for cluster list output";
CM_ SG_ 560 RadarCfg_StoreInNVM_valid "Allows changing the StoreInNvm parameter";
CM_ SG_ 560 RadarCfg_SortIndex_valid "Allows changing the SortIndex parameter";
CM_ SG_ 560 RadarCfg_SortIndex "Object sort index";
CM_ SG_ 560 RadarCfg_StoreInNVM "Store configuration in Nvm";
CM_ SG_ 560 RadarCfg_SendExtInfo_valid "Allows changing the SendExtInfo parameter";
CM_ SG_ 560 RadarCfg_SendExtInfo "Enables output of extended message";
CM_ SG_ 560 RadarCfg_CtrlRelay_valid "Allows changing the CtrlRelay parameter";
CM_ SG_ 560 RadarCfg_CtrlRelay "Enables output of CtrlRelay message if CollDet is active";
CM_ SG_ 560 RadarCfg_SendQuality_valid "Allows changing the SendQuality parameter";
CM_ SG_ 560 RadarCfg_SendQuality "Enables output of quality message";
CM_ SG_ 560 RadarCfg_MaxDistance_valid "Allows changing the MaxDistance parameter";
CM_ SG_ 560 RadarCfg_OutputType_valid "Allows changing the OutputType parameter";
CM_ SG_ 560 RadarCfg_SensorID_valid "Allows changing the SensorId parameter";
CM_ SG_ 560 RadarCfg_MaxDistance "Maximum distance of far scan";
CM_ SG_ 560 RadarCfg_OutputType "Data output type";
CM_ SG_ 560 RadarCfg_SensorID "Sensor ID (0 to 7)";
CM_ BO_ 544 "Radar configuration";
CM_ SG_ 544 RadarCfg_InvalidClusters_valid "Allows changing the InvalidClusters parameter";
CM_ SG_ 544 RadarCfg_InvalidClusters "Enables selective output of invalid clusters";
CM_ SG_ 544 RadarCfg_RCS_Threshold_Valid "Allows changing the RCS_Threshold parameter";
CM_ SG_ 544 RadarCfg_RCS_Threshold "Standard or high sensitivity for cluster list output";
CM_ SG_ 544 RadarCfg_StoreInNVM_valid "Allows changing the StoreInNvm parameter";
CM_ SG_ 544 RadarCfg_SortIndex_valid "Allows changing the SortIndex parameter";
CM_ SG_ 544 RadarCfg_SortIndex "Object sort index";
CM_ SG_ 544 RadarCfg_StoreInNVM "Store configuration in Nvm";
CM_ SG_ 544 RadarCfg_SendExtInfo_valid "Allows changing the SendExtInfo parameter";
CM_ SG_ 544 RadarCfg_SendExtInfo "Enables output of extended message";
CM_ SG_ 544 RadarCfg_CtrlRelay_valid "Allows changing the CtrlRelay parameter";
CM_ SG_ 544 RadarCfg_CtrlRelay "Enables output of CtrlRelay message if CollDet is active";
CM_ SG_ 544 RadarCfg_SendQuality_valid "Allows changing the SendQuality parameter";
CM_ SG_ 544 RadarCfg_SendQuality "Enables output of quality message";
CM_ SG_ 544 RadarCfg_MaxDistance_valid "Allows changing the MaxDistance parameter";
CM_ SG_ 544 RadarCfg_OutputType_valid "Allows changing the OutputType parameter";
CM_ SG_ 544 RadarCfg_SensorID_valid "Allows changing the SensorId parameter";
CM_ SG_ 544 RadarCfg_MaxDistance "Maximum distance of far scan";
CM_ SG_ 544 RadarCfg_OutputType "Data output type";
CM_ SG_ 544 RadarCfg_SensorID "Sensor ID (0 to 7)";
CM_ BO_ 528 "Radar configuration";
CM_ SG_ 528 RadarCfg_InvalidClusters_valid "Allows changing the InvalidClusters parameter";
CM_ SG_ 528 RadarCfg_InvalidClusters "Enables selective output of invalid clusters";
CM_ SG_ 528 RadarCfg_RCS_Threshold_Valid "Allows changing the RCS_Threshold parameter";
CM_ SG_ 528 RadarCfg_RCS_Threshold "Standard or high sensitivity for cluster list output";
CM_ SG_ 528 RadarCfg_StoreInNVM_valid "Allows changing the StoreInNvm parameter";
CM_ SG_ 528 RadarCfg_SortIndex_valid "Allows changing the SortIndex parameter";
CM_ SG_ 528 RadarCfg_SortIndex "Object sort index";
CM_ SG_ 528 RadarCfg_StoreInNVM "Store configuration in Nvm";
CM_ SG_ 528 RadarCfg_SendExtInfo_valid "Allows changing the SendExtInfo parameter";
CM_ SG_ 528 RadarCfg_SendExtInfo "Enables output of extended message";
CM_ SG_ 528 RadarCfg_CtrlRelay_valid "Allows changing the CtrlRelay parameter";
CM_ SG_ 528 RadarCfg_CtrlRelay "Enables output of CtrlRelay message if CollDet is active";
CM_ SG_ 528 RadarCfg_SendQuality_valid "Allows changing the SendQuality parameter";
CM_ SG_ 528 RadarCfg_SendQuality "Enables output of quality message";
CM_ SG_ 528 RadarCfg_MaxDistance_valid "Allows changing the MaxDistance parameter";
CM_ SG_ 528 RadarCfg_OutputType_valid "Allows changing the OutputType parameter";
CM_ SG_ 528 RadarCfg_SensorID_valid "Allows changing the SensorId parameter";
CM_ SG_ 528 RadarCfg_MaxDistance "Maximum distance of far scan";
CM_ SG_ 528 RadarCfg_OutputType "Data output type";
CM_ SG_ 528 RadarCfg_SensorID "Sensor ID (0 to 7)";
CM_ BO_ 1662 "Collision detection warning object information";
CM_ SG_ 1662 Obj_CollDetRegionBitfield "Region bit field with collision detection";
CM_ SG_ 1662 Obj_ID "Object ID";
CM_ BO_ 1646 "Collision detection warning object information";
CM_ SG_ 1646 Obj_CollDetRegionBitfield "Region bit field with collision detection";
CM_ SG_ 1646 Obj_ID "Object ID";
CM_ BO_ 1630 "Collision detection warning object information";
CM_ SG_ 1630 Obj_CollDetRegionBitfield "Region bit field with collision detection";
CM_ SG_ 1630 Obj_ID "Object ID";
CM_ BO_ 1614 "Collision detection warning object information";
CM_ SG_ 1614 Obj_CollDetRegionBitfield "Region bit field with collision detection";
CM_ SG_ 1614 Obj_ID "Object ID";
CM_ BO_ 1598 "Collision detection warning object information";
CM_ SG_ 1598 Obj_CollDetRegionBitfield "Region bit field with collision detection";
CM_ SG_ 1598 Obj_ID "Object ID";
CM_ BO_ 1582 "Collision detection warning object information";
CM_ SG_ 1582 Obj_CollDetRegionBitfield "Region bit field with collision detection";
CM_ SG_ 1582 Obj_ID "Object ID";
CM_ BO_ 1566 "Collision detection warning object information";
CM_ SG_ 1566 Obj_CollDetRegionBitfield "Region bit field with collision detection";
CM_ SG_ 1566 Obj_ID "Object ID";
CM_ BO_ 1661 "Extended object information";
CM_ SG_ 1661 Obj_Class "Object classification";
CM_ SG_ 1661 Obj_ArelLat "Object relative lateral acceleration";
CM_ SG_ 1661 Obj_ID "Object ID";
CM_ SG_ 1661 Obj_OrientationAngle "Object orientation angle";
CM_ SG_ 1661 Obj_Width "Object width";
CM_ SG_ 1661 Obj_Length "Object length";
CM_ SG_ 1661 Obj_ArelLong "Object relative longitudinal acceleration";
CM_ BO_ 1645 "Extended object information";
CM_ SG_ 1645 Obj_Class "Object classification";
CM_ SG_ 1645 Obj_ArelLat "Object relative lateral acceleration";
CM_ SG_ 1645 Obj_ID "Object ID";
CM_ SG_ 1645 Obj_OrientationAngle "Object orientation angle";
CM_ SG_ 1645 Obj_Width "Object width";
CM_ SG_ 1645 Obj_Length "Object length";
CM_ SG_ 1645 Obj_ArelLong "Object relative longitudinal acceleration";
CM_ BO_ 1629 "Extended object information";
CM_ SG_ 1629 Obj_Class "Object classification";
CM_ SG_ 1629 Obj_ArelLat "Object relative lateral acceleration";
CM_ SG_ 1629 Obj_ID "Object ID";
CM_ SG_ 1629 Obj_OrientationAngle "Object orientation angle";
CM_ SG_ 1629 Obj_Width "Object width";
CM_ SG_ 1629 Obj_Length "Object length";
CM_ SG_ 1629 Obj_ArelLong "Object relative longitudinal acceleration";
CM_ BO_ 1613 "Extended object information";
CM_ SG_ 1613 Obj_Class "Object classification";
CM_ SG_ 1613 Obj_ArelLat "Object relative lateral acceleration";
CM_ SG_ 1613 Obj_ID "Object ID";
CM_ SG_ 1613 Obj_OrientationAngle "Object orientation angle";
CM_ SG_ 1613 Obj_Width "Object width";
CM_ SG_ 1613 Obj_Length "Object length";
CM_ SG_ 1613 Obj_ArelLong "Object relative longitudinal acceleration";
CM_ BO_ 1597 "Extended object information";
CM_ SG_ 1597 Obj_Class "Object classification";
CM_ SG_ 1597 Obj_ArelLat "Object relative lateral acceleration";
CM_ SG_ 1597 Obj_ID "Object ID";
CM_ SG_ 1597 Obj_OrientationAngle "Object orientation angle";
CM_ SG_ 1597 Obj_Width "Object width";
CM_ SG_ 1597 Obj_Length "Object length";
CM_ SG_ 1597 Obj_ArelLong "Object relative longitudinal acceleration";
CM_ BO_ 1581 "Extended object information";
CM_ SG_ 1581 Obj_Class "Object classification";
CM_ SG_ 1581 Obj_ArelLat "Object relative lateral acceleration";
CM_ SG_ 1581 Obj_ID "Object ID";
CM_ SG_ 1581 Obj_OrientationAngle "Object orientation angle";
CM_ SG_ 1581 Obj_Width "Object width";
CM_ SG_ 1581 Obj_Length "Object length";
CM_ SG_ 1581 Obj_ArelLong "Object relative longitudinal acceleration";
CM_ BO_ 1565 "Extended object information";
CM_ SG_ 1565 Obj_Class "Object classification";
CM_ SG_ 1565 Obj_ArelLat "Object relative lateral acceleration";
CM_ SG_ 1565 Obj_ID "Object ID";
CM_ SG_ 1565 Obj_OrientationAngle "Object orientation angle";
CM_ SG_ 1565 Obj_Width "Object width";
CM_ SG_ 1565 Obj_Length "Object length";
CM_ SG_ 1565 Obj_ArelLong "Object relative longitudinal acceleration";
CM_ BO_ 1660 "Quality object information";
CM_ SG_ 1660 Obj_ProbOfExist "Object probability of existence";
CM_ SG_ 1660 Obj_MeasState "Object measurement status";
CM_ SG_ 1660 Obj_ArelLong_rms "Object relative longitudinal acceleration standard deviation";
CM_ SG_ 1660 Obj_ArelLat_rms "Object relative lateral acceleration standard deviation";
CM_ SG_ 1660 Obj_VrelLong_rms "Object relative longitudinal velocity standard deviation";
CM_ SG_ 1660 Obj_VrelLat_rms "Object relative lateral velocity standard deviation";
CM_ SG_ 1660 Obj_Orientation_rms "Object orientation angle";
CM_ SG_ 1660 Obj_DistLong_rms "Object longitudinal distance standard deviation";
CM_ SG_ 1660 Obj_DistLat_rms "Object lateral distance standard deviation";
CM_ SG_ 1660 Obj_ID "Object ID";
CM_ BO_ 1644 "Quality object information";
CM_ SG_ 1644 Obj_ProbOfExist "Object probability of existence";
CM_ SG_ 1644 Obj_MeasState "Object measurement status";
CM_ SG_ 1644 Obj_ArelLong_rms "Object relative longitudinal acceleration standard deviation";
CM_ SG_ 1644 Obj_ArelLat_rms "Object relative lateral acceleration standard deviation";
CM_ SG_ 1644 Obj_VrelLong_rms "Object relative longitudinal velocity standard deviation";
CM_ SG_ 1644 Obj_VrelLat_rms "Object relative lateral velocity standard deviation";
CM_ SG_ 1644 Obj_Orientation_rms "Object orientation angle";
CM_ SG_ 1644 Obj_DistLong_rms "Object longitudinal distance standard deviation";
CM_ SG_ 1644 Obj_DistLat_rms "Object lateral distance standard deviation";
CM_ SG_ 1644 Obj_ID "Object ID";
CM_ BO_ 1628 "Quality object information";
CM_ SG_ 1628 Obj_ProbOfExist "Object probability of existence";
CM_ SG_ 1628 Obj_MeasState "Object measurement status";
CM_ SG_ 1628 Obj_ArelLong_rms "Object relative longitudinal acceleration standard deviation";
CM_ SG_ 1628 Obj_ArelLat_rms "Object relative lateral acceleration standard deviation";
CM_ SG_ 1628 Obj_VrelLong_rms "Object relative longitudinal velocity standard deviation";
CM_ SG_ 1628 Obj_VrelLat_rms "Object relative lateral velocity standard deviation";
CM_ SG_ 1628 Obj_Orientation_rms "Object orientation angle";
CM_ SG_ 1628 Obj_DistLong_rms "Object longitudinal distance standard deviation";
CM_ SG_ 1628 Obj_DistLat_rms "Object lateral distance standard deviation";
CM_ SG_ 1628 Obj_ID "Object ID";
CM_ BO_ 1612 "Quality object information";
CM_ SG_ 1612 Obj_ProbOfExist "Object probability of existence";
CM_ SG_ 1612 Obj_MeasState "Object measurement status";
CM_ SG_ 1612 Obj_ArelLong_rms "Object relative longitudinal acceleration standard deviation";
CM_ SG_ 1612 Obj_ArelLat_rms "Object relative lateral acceleration standard deviation";
CM_ SG_ 1612 Obj_VrelLong_rms "Object relative longitudinal velocity standard deviation";
CM_ SG_ 1612 Obj_VrelLat_rms "Object relative lateral velocity standard deviation";
CM_ SG_ 1612 Obj_Orientation_rms "Object orientation angle";
CM_ SG_ 1612 Obj_DistLong_rms "Object longitudinal distance standard deviation";
CM_ SG_ 1612 Obj_DistLat_rms "Object lateral distance standard deviation";
CM_ SG_ 1612 Obj_ID "Object ID";
CM_ BO_ 1596 "Quality object information";
CM_ SG_ 1596 Obj_ProbOfExist "Object probability of existence";
CM_ SG_ 1596 Obj_MeasState "Object measurement status";
CM_ SG_ 1596 Obj_ArelLong_rms "Object relative longitudinal acceleration standard deviation";
CM_ SG_ 1596 Obj_ArelLat_rms "Object relative lateral acceleration standard deviation";
CM_ SG_ 1596 Obj_VrelLong_rms "Object relative longitudinal velocity standard deviation";
CM_ SG_ 1596 Obj_VrelLat_rms "Object relative lateral velocity standard deviation";
CM_ SG_ 1596 Obj_Orientation_rms "Object orientation angle";
CM_ SG_ 1596 Obj_DistLong_rms "Object longitudinal distance standard deviation";
CM_ SG_ 1596 Obj_DistLat_rms "Object lateral distance standard deviation";
CM_ SG_ 1596 Obj_ID "Object ID";
CM_ BO_ 1580 "Quality object information";
CM_ SG_ 1580 Obj_ProbOfExist "Object probability of existence";
CM_ SG_ 1580 Obj_MeasState "Object measurement status";
CM_ SG_ 1580 Obj_ArelLong_rms "Object relative longitudinal acceleration standard deviation";
CM_ SG_ 1580 Obj_ArelLat_rms "Object relative lateral acceleration standard deviation";
CM_ SG_ 1580 Obj_VrelLong_rms "Object relative longitudinal velocity standard deviation";
CM_ SG_ 1580 Obj_VrelLat_rms "Object relative lateral velocity standard deviation";
CM_ SG_ 1580 Obj_Orientation_rms "Object orientation angle";
CM_ SG_ 1580 Obj_DistLong_rms "Object longitudinal distance standard deviation";
CM_ SG_ 1580 Obj_DistLat_rms "Object lateral distance standard deviation";
CM_ SG_ 1580 Obj_ID "Object ID";
CM_ BO_ 1564 "Quality object information";
CM_ SG_ 1564 Obj_ProbOfExist "Object probability of existence";
CM_ SG_ 1564 Obj_MeasState "Object measurement status";
CM_ SG_ 1564 Obj_ArelLong_rms "Object relative longitudinal acceleration standard deviation";
CM_ SG_ 1564 Obj_ArelLat_rms "Object relative lateral acceleration standard deviation";
CM_ SG_ 1564 Obj_VrelLong_rms "Object relative longitudinal velocity standard deviation";
CM_ SG_ 1564 Obj_VrelLat_rms "Object relative lateral velocity standard deviation";
CM_ SG_ 1564 Obj_Orientation_rms "Object orientation angle";
CM_ SG_ 1564 Obj_DistLong_rms "Object longitudinal distance standard deviation";
CM_ SG_ 1564 Obj_DistLat_rms "Object lateral distance standard deviation";
CM_ SG_ 1564 Obj_ID "Object ID";
CM_ BO_ 1659 "General object information";
CM_ SG_ 1659 Obj_DynProp "Object dynamic property";
CM_ SG_ 1659 Obj_RCS "Object RCS value (radar cross section)";
CM_ SG_ 1659 Obj_VrelLat "Object relative lateral velocity";
CM_ SG_ 1659 Obj_ID "Object ID";
CM_ SG_ 1659 Obj_DistLong "Object longitudinal displacement";
CM_ SG_ 1659 Obj_VrelLong "Object relative longitudinal velocity";
CM_ SG_ 1659 Obj_DistLat "Object lateral displacement";
CM_ BO_ 1643 "General object information";
CM_ SG_ 1643 Obj_DynProp "Object dynamic property";
CM_ SG_ 1643 Obj_RCS "Object RCS value (radar cross section)";
CM_ SG_ 1643 Obj_VrelLat "Object relative lateral velocity";
CM_ SG_ 1643 Obj_ID "Object ID";
CM_ SG_ 1643 Obj_DistLong "Object longitudinal displacement";
CM_ SG_ 1643 Obj_VrelLong "Object relative longitudinal velocity";
CM_ SG_ 1643 Obj_DistLat "Object lateral displacement";
CM_ BO_ 1627 "General object information";
CM_ SG_ 1627 Obj_DynProp "Object dynamic property";
CM_ SG_ 1627 Obj_RCS "Object RCS value (radar cross section)";
CM_ SG_ 1627 Obj_VrelLat "Object relative lateral velocity";
CM_ SG_ 1627 Obj_ID "Object ID";
CM_ SG_ 1627 Obj_DistLong "Object longitudinal displacement";
CM_ SG_ 1627 Obj_VrelLong "Object relative longitudinal velocity";
CM_ SG_ 1627 Obj_DistLat "Object lateral displacement";
CM_ BO_ 1611 "General object information";
CM_ SG_ 1611 Obj_DynProp "Object dynamic property";
CM_ SG_ 1611 Obj_RCS "Object RCS value (radar cross section)";
CM_ SG_ 1611 Obj_VrelLat "Object relative lateral velocity";
CM_ SG_ 1611 Obj_ID "Object ID";
CM_ SG_ 1611 Obj_DistLong "Object longitudinal displacement";
CM_ SG_ 1611 Obj_VrelLong "Object relative longitudinal velocity";
CM_ SG_ 1611 Obj_DistLat "Object lateral displacement";
CM_ BO_ 1595 "General object information";
CM_ SG_ 1595 Obj_DynProp "Object dynamic property";
CM_ SG_ 1595 Obj_RCS "Object RCS value (radar cross section)";
CM_ SG_ 1595 Obj_VrelLat "Object relative lateral velocity";
CM_ SG_ 1595 Obj_ID "Object ID";
CM_ SG_ 1595 Obj_DistLong "Object longitudinal displacement";
CM_ SG_ 1595 Obj_VrelLong "Object relative longitudinal velocity";
CM_ SG_ 1595 Obj_DistLat "Object lateral displacement";
CM_ BO_ 1579 "General object information";
CM_ SG_ 1579 Obj_DynProp "Object dynamic property";
CM_ SG_ 1579 Obj_RCS "Object RCS value (radar cross section)";
CM_ SG_ 1579 Obj_VrelLat "Object relative lateral velocity";
CM_ SG_ 1579 Obj_ID "Object ID";
CM_ SG_ 1579 Obj_DistLong "Object longitudinal displacement";
CM_ SG_ 1579 Obj_VrelLong "Object relative longitudinal velocity";
CM_ SG_ 1579 Obj_DistLat "Object lateral displacement";
CM_ BO_ 1563 "General object information";
CM_ SG_ 1563 Obj_DynProp "Object dynamic property";
CM_ SG_ 1563 Obj_RCS "Object RCS value (radar cross section)";
CM_ SG_ 1563 Obj_VrelLat "Object relative lateral velocity";
CM_ SG_ 1563 Obj_ID "Object ID";
CM_ SG_ 1563 Obj_DistLong "Object longitudinal displacement";
CM_ SG_ 1563 Obj_VrelLong "Object relative longitudinal velocity";
CM_ SG_ 1563 Obj_DistLat "Object lateral displacement";
CM_ BO_ 1658 "Status information about object";
CM_ SG_ 1658 Obj_NofObjects "Number of Objects sent";
CM_ SG_ 1658 Obj_MeasCounter "Measurement Counter";
CM_ SG_ 1658 Obj_InterfaceVersion "Object CAN Interface Version Number";
VAL_ 1904 Version_ExtendedRange 1 "Extended range" 0 "Standard range" ;
VAL_ 1888 Version_ExtendedRange 1 "Extended range" 0 "Standard range" ;
VAL_ 1872 Version_ExtendedRange 1 "Extended range" 0 "Standard range" ;
VAL_ 1856 Version_ExtendedRange 1 "Extended range" 0 "Standard range" ;
VAL_ 1840 Version_ExtendedRange 1 "Extended range" 0 "Standard range" ;
VAL_ 1824 Version_ExtendedRange 1 "Extended range" 0 "Standard range" ;
VAL_ 1808 Version_ExtendedRange 1 "Extended range" 0 "Standard range" ;
VAL_ 880 RadarDevice_SpeedDirection 3 "reserved" 2 "reverse" 1 "forward" 0 "standstill" ;
VAL_ 864 RadarDevice_SpeedDirection 3 "reserved" 2 "reverse" 1 "forward" 0 "standstill" ;
VAL_ 848 RadarDevice_SpeedDirection 3 "reserved" 2 "reverse" 1 "forward" 0 "standstill" ;
VAL_ 832 RadarDevice_SpeedDirection 3 "reserved" 2 "reverse" 1 "forward" 0 "standstill" ;
VAL_ 816 RadarDevice_SpeedDirection 3 "reserved" 2 "reverse" 1 "forward" 0 "standstill" ;
VAL_ 800 RadarDevice_SpeedDirection 3 "reserved" 2 "reverse" 1 "forward" 0 "standstill" ;
VAL_ 784 RadarDevice_SpeedDirection 3 "reserved" 2 "reverse" 1 "forward" 0 "standstill" ;
VAL_ 625 RadarState_InvalidClusters 64 "Wrapped stationary enabled" 32 "Ego mirror enabled" 16 "Range <1m enabled" 8 "Invalid range rate enabled" 4 "Low RCS static enabled" 2 "Low RCS dynamic enabled" 1 "All invalid clusters enabled" 0 "All invalid clusters disabled" ;
VAL_ 625 RadarState_Voltage_Error 1 "Error active" 0 "No error" ;
VAL_ 625 RadarState_Temporary_Error 1 "Error active" 0 "No error" ;
VAL_ 625 RadarState_Temperature_Error 1 "Error active" 0 "No error" ;
VAL_ 625 RadarState_Interference 1 "Interference present" 0 "No interference" ;
VAL_ 625 RadarState_Persistent_Error 1 "Error active" 0 "No error" ;
VAL_ 625 RadarState_RCS_Threshold 7 "Reserved" 6 "Reserved" 5 "Reserved" 4 "Reserved" 3 "Reserved" 2 "Reserved" 1 "High Sensitivity" 0 "Standard" ;
VAL_ 625 RadarState_CtrlRelayCfg 1 "Active" 0 "Inactive" ;
VAL_ 625 RadarState_SendQualityCfg 1 "Active" 0 "Inactive" ;
VAL_ 625 RadarState_SendExtInfoCfg 1 "Active" 0 "Inactive" ;
VAL_ 625 RadarState_MotionRxState 3 "Speed and yaw rate missing" 2 "Yaw rate missing" 1 "Speed missing" 0 "Input ok" ;
VAL_ 625 RadarState_OutputTypeCfg 3 "reserved 2" 2 "SendClusters" 1 "SendObjects" 0 "None" ;
VAL_ 625 RadarState_RadarPowerCfg 7 "Reserved" 6 "Reserved" 5 "Reserved" 4 "Reserved" 3 "-9 dB Tx gain" 2 "-6 dB Tx gain" 1 "-3 dB Tx gain" 0 "Standard" ;
VAL_ 625 RadarState_NVMReadStatus 1 "successful" 0 "pending" ;
VAL_ 625 RadarState_NVMwriteStatus 1 "successful" 0 "failed" ;
VAL_ 609 RadarState_InvalidClusters 64 "Wrapped stationary enabled" 32 "Ego mirror enabled" 16 "Range <1m enabled" 8 "Invalid range rate enabled" 4 "Low RCS static enabled" 2 "Low RCS dynamic enabled" 1 "All invalid clusters enabled" 0 "All invalid clusters disabled" ;
VAL_ 609 RadarState_Voltage_Error 1 "Error active" 0 "No error" ;
VAL_ 609 RadarState_Temporary_Error 1 "Error active" 0 "No error" ;
VAL_ 609 RadarState_Temperature_Error 1 "Error active" 0 "No error" ;
VAL_ 609 RadarState_Interference 1 "Interference present" 0 "No interference" ;
VAL_ 609 RadarState_Persistent_Error 1 "Error active" 0 "No error" ;
VAL_ 609 RadarState_RCS_Threshold 7 "Reserved" 6 "Reserved" 5 "Reserved" 4 "Reserved" 3 "Reserved" 2 "Reserved" 1 "High Sensitivity" 0 "Standard" ;
VAL_ 609 RadarState_CtrlRelayCfg 1 "Active" 0 "Inactive" ;
VAL_ 609 RadarState_SendQualityCfg 1 "Active" 0 "Inactive" ;
VAL_ 609 RadarState_SendExtInfoCfg 1 "Active" 0 "Inactive" ;
VAL_ 609 RadarState_MotionRxState 3 "Speed and yaw rate missing" 2 "Yaw rate missing" 1 "Speed missing" 0 "Input ok" ;
VAL_ 609 RadarState_OutputTypeCfg 3 "reserved 2" 2 "SendClusters" 1 "SendObjects" 0 "None" ;
VAL_ 609 RadarState_RadarPowerCfg 7 "Reserved" 6 "Reserved" 5 "Reserved" 4 "Reserved" 3 "-9 dB Tx gain" 2 "-6 dB Tx gain" 1 "-3 dB Tx gain" 0 "Standard" ;
VAL_ 609 RadarState_NVMReadStatus 1 "successful" 0 "pending" ;
VAL_ 609 RadarState_NVMwriteStatus 1 "successful" 0 "failed" ;
VAL_ 593 RadarState_InvalidClusters 64 "Wrapped stationary enabled" 32 "Ego mirror enabled" 16 "Range <1m enabled" 8 "Invalid range rate enabled" 4 "Low RCS static enabled" 2 "Low RCS dynamic enabled" 1 "All invalid clusters enabled" 0 "All invalid clusters disabled" ;
VAL_ 593 RadarState_Voltage_Error 1 "Error active" 0 "No error" ;
VAL_ 593 RadarState_Temporary_Error 1 "Error active" 0 "No error" ;
VAL_ 593 RadarState_Temperature_Error 1 "Error active" 0 "No error" ;
VAL_ 593 RadarState_Interference 1 "Interference present" 0 "No interference" ;
VAL_ 593 RadarState_Persistent_Error 1 "Error active" 0 "No error" ;
VAL_ 593 RadarState_RCS_Threshold 7 "Reserved" 6 "Reserved" 5 "Reserved" 4 "Reserved" 3 "Reserved" 2 "Reserved" 1 "High Sensitivity" 0 "Standard" ;
VAL_ 593 RadarState_CtrlRelayCfg 1 "Active" 0 "Inactive" ;
VAL_ 593 RadarState_SendQualityCfg 1 "Active" 0 "Inactive" ;
VAL_ 593 RadarState_SendExtInfoCfg 1 "Active" 0 "Inactive" ;
VAL_ 593 RadarState_MotionRxState 3 "Speed and yaw rate missing" 2 "Yaw rate missing" 1 "Speed missing" 0 "Input ok" ;
VAL_ 593 RadarState_OutputTypeCfg 3 "reserved 2" 2 "SendClusters" 1 "SendObjects" 0 "None" ;
VAL_ 593 RadarState_RadarPowerCfg 7 "Reserved" 6 "Reserved" 5 "Reserved" 4 "Reserved" 3 "-9 dB Tx gain" 2 "-6 dB Tx gain" 1 "-3 dB Tx gain" 0 "Standard" ;
VAL_ 593 RadarState_NVMReadStatus 1 "successful" 0 "pending" ;
VAL_ 593 RadarState_NVMwriteStatus 1 "successful" 0 "failed" ;
VAL_ 577 RadarState_InvalidClusters 64 "Wrapped stationary enabled" 32 "Ego mirror enabled" 16 "Range <1m enabled" 8 "Invalid range rate enabled" 4 "Low RCS static enabled" 2 "Low RCS dynamic enabled" 1 "All invalid clusters enabled" 0 "All invalid clusters disabled" ;
VAL_ 577 RadarState_Voltage_Error 1 "Error active" 0 "No error" ;
VAL_ 577 RadarState_Temporary_Error 1 "Error active" 0 "No error" ;
VAL_ 577 RadarState_Temperature_Error 1 "Error active" 0 "No error" ;
VAL_ 577 RadarState_Interference 1 "Interference present" 0 "No interference" ;
VAL_ 577 RadarState_Persistent_Error 1 "Error active" 0 "No error" ;
VAL_ 577 RadarState_RCS_Threshold 7 "Reserved" 6 "Reserved" 5 "Reserved" 4 "Reserved" 3 "Reserved" 2 "Reserved" 1 "High Sensitivity" 0 "Standard" ;
VAL_ 577 RadarState_CtrlRelayCfg 1 "Active" 0 "Inactive" ;
VAL_ 577 RadarState_SendQualityCfg 1 "Active" 0 "Inactive" ;
VAL_ 577 RadarState_SendExtInfoCfg 1 "Active" 0 "Inactive" ;
VAL_ 577 RadarState_MotionRxState 3 "Speed and yaw rate missing" 2 "Yaw rate missing" 1 "Speed missing" 0 "Input ok" ;
VAL_ 577 RadarState_OutputTypeCfg 3 "reserved 2" 2 "SendClusters" 1 "SendObjects" 0 "None" ;
VAL_ 577 RadarState_RadarPowerCfg 7 "Reserved" 6 "Reserved" 5 "Reserved" 4 "Reserved" 3 "-9 dB Tx gain" 2 "-6 dB Tx gain" 1 "-3 dB Tx gain" 0 "Standard" ;
VAL_ 577 RadarState_NVMReadStatus 1 "successful" 0 "pending" ;
VAL_ 577 RadarState_NVMwriteStatus 1 "successful" 0 "failed" ;
VAL_ 561 RadarState_InvalidClusters 64 "Wrapped stationary enabled" 32 "Ego mirror enabled" 16 "Range <1m enabled" 8 "Invalid range rate enabled" 4 "Low RCS static enabled" 2 "Low RCS dynamic enabled" 1 "All invalid clusters enabled" 0 "All invalid clusters disabled" ;
VAL_ 561 RadarState_Voltage_Error 1 "Error active" 0 "No error" ;
VAL_ 561 RadarState_Temporary_Error 1 "Error active" 0 "No error" ;
VAL_ 561 RadarState_Temperature_Error 1 "Error active" 0 "No error" ;
VAL_ 561 RadarState_Interference 1 "Interference present" 0 "No interference" ;
VAL_ 561 RadarState_Persistent_Error 1 "Error active" 0 "No error" ;
VAL_ 561 RadarState_RCS_Threshold 7 "Reserved" 6 "Reserved" 5 "Reserved" 4 "Reserved" 3 "Reserved" 2 "Reserved" 1 "High Sensitivity" 0 "Standard" ;
VAL_ 561 RadarState_CtrlRelayCfg 1 "Active" 0 "Inactive" ;
VAL_ 561 RadarState_SendQualityCfg 1 "Active" 0 "Inactive" ;
VAL_ 561 RadarState_SendExtInfoCfg 1 "Active" 0 "Inactive" ;
VAL_ 561 RadarState_MotionRxState 3 "Speed and yaw rate missing" 2 "Yaw rate missing" 1 "Speed missing" 0 "Input ok" ;
VAL_ 561 RadarState_OutputTypeCfg 3 "reserved 2" 2 "SendClusters" 1 "SendObjects" 0 "None" ;
VAL_ 561 RadarState_RadarPowerCfg 7 "Reserved" 6 "Reserved" 5 "Reserved" 4 "Reserved" 3 "-9 dB Tx gain" 2 "-6 dB Tx gain" 1 "-3 dB Tx gain" 0 "Standard" ;
VAL_ 561 RadarState_NVMReadStatus 1 "successful" 0 "pending" ;
VAL_ 561 RadarState_NVMwriteStatus 1 "successful" 0 "failed" ;
VAL_ 545 RadarState_InvalidClusters 64 "Wrapped stationary enabled" 32 "Ego mirror enabled" 16 "Range <1m enabled" 8 "Invalid range rate enabled" 4 "Low RCS static enabled" 2 "Low RCS dynamic enabled" 1 "All invalid clusters enabled" 0 "All invalid clusters disabled" ;
VAL_ 545 RadarState_Voltage_Error 1 "Error active" 0 "No error" ;
VAL_ 545 RadarState_Temporary_Error 1 "Error active" 0 "No error" ;
VAL_ 545 RadarState_Temperature_Error 1 "Error active" 0 "No error" ;
VAL_ 545 RadarState_Interference 1 "Interference present" 0 "No interference" ;
VAL_ 545 RadarState_Persistent_Error 1 "Error active" 0 "No error" ;
VAL_ 545 RadarState_RCS_Threshold 7 "Reserved" 6 "Reserved" 5 "Reserved" 4 "Reserved" 3 "Reserved" 2 "Reserved" 1 "High Sensitivity" 0 "Standard" ;
VAL_ 545 RadarState_CtrlRelayCfg 1 "Active" 0 "Inactive" ;
VAL_ 545 RadarState_SendQualityCfg 1 "Active" 0 "Inactive" ;
VAL_ 545 RadarState_SendExtInfoCfg 1 "Active" 0 "Inactive" ;
VAL_ 545 RadarState_MotionRxState 3 "Speed and yaw rate missing" 2 "Yaw rate missing" 1 "Speed missing" 0 "Input ok" ;
VAL_ 545 RadarState_OutputTypeCfg 3 "reserved 2" 2 "SendClusters" 1 "SendObjects" 0 "None" ;
VAL_ 545 RadarState_RadarPowerCfg 7 "Reserved" 6 "Reserved" 5 "Reserved" 4 "Reserved" 3 "-9 dB Tx gain" 2 "-6 dB Tx gain" 1 "-3 dB Tx gain" 0 "Standard" ;
VAL_ 545 RadarState_NVMReadStatus 1 "successful" 0 "pending" ;
VAL_ 545 RadarState_NVMwriteStatus 1 "successful" 0 "failed" ;
VAL_ 529 RadarState_InvalidClusters 64 "Wrapped stationary enabled" 32 "Ego mirror enabled" 16 "Range <1m enabled" 8 "Invalid range rate enabled" 4 "Low RCS static enabled" 2 "Low RCS dynamic enabled" 1 "All invalid clusters enabled" 0 "All invalid clusters disabled" ;
VAL_ 529 RadarState_Voltage_Error 1 "Error active" 0 "No error" ;
VAL_ 529 RadarState_Temporary_Error 1 "Error active" 0 "No error" ;
VAL_ 529 RadarState_Temperature_Error 1 "Error active" 0 "No error" ;
VAL_ 529 RadarState_Interference 1 "Interference present" 0 "No interference" ;
VAL_ 529 RadarState_Persistent_Error 1 "Error active" 0 "No error" ;
VAL_ 529 RadarState_RCS_Threshold 7 "Reserved" 6 "Reserved" 5 "Reserved" 4 "Reserved" 3 "Reserved" 2 "Reserved" 1 "High Sensitivity" 0 "Standard" ;
VAL_ 529 RadarState_CtrlRelayCfg 1 "Active" 0 "Inactive" ;
VAL_ 529 RadarState_SendQualityCfg 1 "Active" 0 "Inactive" ;
VAL_ 529 RadarState_SendExtInfoCfg 1 "Active" 0 "Inactive" ;
VAL_ 529 RadarState_MotionRxState 3 "Speed and yaw rate missing" 2 "Yaw rate missing" 1 "Speed missing" 0 "Input ok" ;
VAL_ 529 RadarState_OutputTypeCfg 3 "reserved 2" 2 "SendClusters" 1 "SendObjects" 0 "None" ;
VAL_ 529 RadarState_RadarPowerCfg 7 "Reserved" 6 "Reserved" 5 "Reserved" 4 "Reserved" 3 "-9 dB Tx gain" 2 "-6 dB Tx gain" 1 "-3 dB Tx gain" 0 "Standard" ;
VAL_ 529 RadarState_NVMReadStatus 1 "successful" 0 "pending" ;
VAL_ 529 RadarState_NVMwriteStatus 1 "successful" 0 "failed" ;
VAL_ 624 RadarCfg_InvalidClusters_valid 1 "Valid" 0 "Invalid" ;
VAL_ 624 RadarCfg_InvalidClusters 64 "Enable wrapped stationary" 32 "Enable ego mirror" 16 "Enable range < 1m" 8 "Enable invalid range rate" 4 "Enable low RCS static" 2 "Enable low RCS dynamic" 1 "Enable all invalid clusters" 0 "Disable" ;
VAL_ 624 RadarCfg_RCS_Threshold_Valid 1 "Valid" 0 "Invalid" ;
VAL_ 624 RadarCfg_RCS_Threshold 7 "Reserved" 6 "Reserved" 5 "Reserved" 4 "Reserved" 3 "Reserved" 2 "Reserved" 1 "High Sensitivity" 0 "Standard" ;
VAL_ 624 RadarCfg_StoreInNVM_valid 1 "Valid" 0 "Invalid" ;
VAL_ 624 RadarCfg_SortIndex_valid 1 "Valid" 0 "Invalid" ;
VAL_ 624 RadarCfg_SortIndex 2 "Sorted by RCS" 1 "Sorted by range" 0 "No sorting" ;
VAL_ 624 RadarCfg_StoreInNVM 1 "Active" 0 "Inactive" ;
VAL_ 624 RadarCfg_SendExtInfo_valid 1 "Valid" 0 "Invalid" ;
VAL_ 624 RadarCfg_SendExtInfo 1 "Active" 0 "Inactive" ;
VAL_ 624 RadarCfg_CtrlRelay_valid 1 "Valid" 0 "Invalid" ;
VAL_ 624 RadarCfg_CtrlRelay 1 "Active" 0 "Inactive" ;
VAL_ 624 RadarCfg_SendQuality_valid 1 "Valid" 0 "Invalid" ;
VAL_ 624 RadarCfg_SendQuality 1 "Active" 0 "Inactive" ;
VAL_ 624 RadarCfg_MaxDistance_valid 1 "Valid" 0 "Invalid" ;
VAL_ 624 RadarCfg_OutputType_valid 1 "Valid" 0 "Invalid" ;
VAL_ 624 RadarCfg_SensorID_valid 1 "Valid" 0 "Invalid" ;
VAL_ 624 RadarCfg_OutputType 3 "reserved 2" 2 "SendClusters" 1 "SendObjects" 0 "None" ;
VAL_ 608 RadarCfg_InvalidClusters_valid 1 "Valid" 0 "Invalid" ;
VAL_ 608 RadarCfg_InvalidClusters 64 "Enable wrapped stationary" 32 "Enable ego mirror" 16 "Enable range < 1m" 8 "Enable invalid range rate" 4 "Enable low RCS static" 2 "Enable low RCS dynamic" 1 "Enable all invalid clusters" 0 "Disable" ;
VAL_ 608 RadarCfg_RCS_Threshold_Valid 1 "Valid" 0 "Invalid" ;
VAL_ 608 RadarCfg_RCS_Threshold 7 "Reserved" 6 "Reserved" 5 "Reserved" 4 "Reserved" 3 "Reserved" 2 "Reserved" 1 "High Sensitivity" 0 "Standard" ;
VAL_ 608 RadarCfg_StoreInNVM_valid 1 "Valid" 0 "Invalid" ;
VAL_ 608 RadarCfg_SortIndex_valid 1 "Valid" 0 "Invalid" ;
VAL_ 608 RadarCfg_SortIndex 2 "Sorted by RCS" 1 "Sorted by range" 0 "No sorting" ;
VAL_ 608 RadarCfg_StoreInNVM 1 "Active" 0 "Inactive" ;
VAL_ 608 RadarCfg_SendExtInfo_valid 1 "Valid" 0 "Invalid" ;
VAL_ 608 RadarCfg_SendExtInfo 1 "Active" 0 "Inactive" ;
VAL_ 608 RadarCfg_CtrlRelay_valid 1 "Valid" 0 "Invalid" ;
VAL_ 608 RadarCfg_CtrlRelay 1 "Active" 0 "Inactive" ;
VAL_ 608 RadarCfg_SendQuality_valid 1 "Valid" 0 "Invalid" ;
VAL_ 608 RadarCfg_SendQuality 1 "Active" 0 "Inactive" ;
VAL_ 608 RadarCfg_MaxDistance_valid 1 "Valid" 0 "Invalid" ;
VAL_ 608 RadarCfg_OutputType_valid 1 "Valid" 0 "Invalid" ;
VAL_ 608 RadarCfg_SensorID_valid 1 "Valid" 0 "Invalid" ;
VAL_ 608 RadarCfg_OutputType 3 "reserved 2" 2 "SendClusters" 1 "SendObjects" 0 "None" ;
VAL_ 592 RadarCfg_InvalidClusters_valid 1 "Valid" 0 "Invalid" ;
VAL_ 592 RadarCfg_InvalidClusters 64 "Enable wrapped stationary" 32 "Enable ego mirror" 16 "Enable range < 1m" 8 "Enable invalid range rate" 4 "Enable low RCS static" 2 "Enable low RCS dynamic" 1 "Enable all invalid clusters" 0 "Disable" ;
VAL_ 592 RadarCfg_RCS_Threshold_Valid 1 "Valid" 0 "Invalid" ;
VAL_ 592 RadarCfg_RCS_Threshold 7 "Reserved" 6 "Reserved" 5 "Reserved" 4 "Reserved" 3 "Reserved" 2 "Reserved" 1 "High Sensitivity" 0 "Standard" ;
VAL_ 592 RadarCfg_StoreInNVM_valid 1 "Valid" 0 "Invalid" ;
VAL_ 592 RadarCfg_SortIndex_valid 1 "Valid" 0 "Invalid" ;
VAL_ 592 RadarCfg_SortIndex 2 "Sorted by RCS" 1 "Sorted by range" 0 "No sorting" ;
VAL_ 592 RadarCfg_StoreInNVM 1 "Active" 0 "Inactive" ;
VAL_ 592 RadarCfg_SendExtInfo_valid 1 "Valid" 0 "Invalid" ;
VAL_ 592 RadarCfg_SendExtInfo 1 "Active" 0 "Inactive" ;
VAL_ 592 RadarCfg_CtrlRelay_valid 1 "Valid" 0 "Invalid" ;
VAL_ 592 RadarCfg_CtrlRelay 1 "Active" 0 "Inactive" ;
VAL_ 592 RadarCfg_SendQuality_valid 1 "Valid" 0 "Invalid" ;
VAL_ 592 RadarCfg_SendQuality 1 "Active" 0 "Inactive" ;
VAL_ 592 RadarCfg_MaxDistance_valid 1 "Valid" 0 "Invalid" ;
VAL_ 592 RadarCfg_OutputType_valid 1 "Valid" 0 "Invalid" ;
VAL_ 592 RadarCfg_SensorID_valid 1 "Valid" 0 "Invalid" ;
VAL_ 592 RadarCfg_OutputType 3 "reserved 2" 2 "SendClusters" 1 "SendObjects" 0 "None" ;
VAL_ 576 RadarCfg_InvalidClusters_valid 1 "Valid" 0 "Invalid" ;
VAL_ 576 RadarCfg_InvalidClusters 64 "Enable wrapped stationary" 32 "Enable ego mirror" 16 "Enable range < 1m" 8 "Enable invalid range rate" 4 "Enable low RCS static" 2 "Enable low RCS dynamic" 1 "Enable all invalid clusters" 0 "Disable" ;
VAL_ 576 RadarCfg_RCS_Threshold_Valid 1 "Valid" 0 "Invalid" ;
VAL_ 576 RadarCfg_RCS_Threshold 7 "Reserved" 6 "Reserved" 5 "Reserved" 4 "Reserved" 3 "Reserved" 2 "Reserved" 1 "High Sensitivity" 0 "Standard" ;
VAL_ 576 RadarCfg_StoreInNVM_valid 1 "Valid" 0 "Invalid" ;
VAL_ 576 RadarCfg_SortIndex_valid 1 "Valid" 0 "Invalid" ;
VAL_ 576 RadarCfg_SortIndex 2 "Sorted by RCS" 1 "Sorted by range" 0 "No sorting" ;
VAL_ 576 RadarCfg_StoreInNVM 1 "Active" 0 "Inactive" ;
VAL_ 576 RadarCfg_SendExtInfo_valid 1 "Valid" 0 "Invalid" ;
VAL_ 576 RadarCfg_SendExtInfo 1 "Active" 0 "Inactive" ;
VAL_ 576 RadarCfg_CtrlRelay_valid 1 "Valid" 0 "Invalid" ;
VAL_ 576 RadarCfg_CtrlRelay 1 "Active" 0 "Inactive" ;
VAL_ 576 RadarCfg_SendQuality_valid 1 "Valid" 0 "Invalid" ;
VAL_ 576 RadarCfg_SendQuality 1 "Active" 0 "Inactive" ;
VAL_ 576 RadarCfg_MaxDistance_valid 1 "Valid" 0 "Invalid" ;
VAL_ 576 RadarCfg_OutputType_valid 1 "Valid" 0 "Invalid" ;
VAL_ 576 RadarCfg_SensorID_valid 1 "Valid" 0 "Invalid" ;
VAL_ 576 RadarCfg_OutputType 3 "reserved 2" 2 "SendClusters" 1 "SendObjects" 0 "None" ;
VAL_ 560 RadarCfg_InvalidClusters_valid 1 "Valid" 0 "Invalid" ;
VAL_ 560 RadarCfg_InvalidClusters 64 "Enable wrapped stationary" 32 "Enable ego mirror" 16 "Enable range < 1m" 8 "Enable invalid range rate" 4 "Enable low RCS static" 2 "Enable low RCS dynamic" 1 "Enable all invalid clusters" 0 "Disable" ;
VAL_ 560 RadarCfg_RCS_Threshold_Valid 1 "Valid" 0 "Invalid" ;
VAL_ 560 RadarCfg_RCS_Threshold 7 "Reserved" 6 "Reserved" 5 "Reserved" 4 "Reserved" 3 "Reserved" 2 "Reserved" 1 "High Sensitivity" 0 "Standard" ;
VAL_ 560 RadarCfg_StoreInNVM_valid 1 "Valid" 0 "Invalid" ;
VAL_ 560 RadarCfg_SortIndex_valid 1 "Valid" 0 "Invalid" ;
VAL_ 560 RadarCfg_SortIndex 2 "Sorted by RCS" 1 "Sorted by range" 0 "No sorting" ;
VAL_ 560 RadarCfg_StoreInNVM 1 "Active" 0 "Inactive" ;
VAL_ 560 RadarCfg_SendExtInfo_valid 1 "Valid" 0 "Invalid" ;
VAL_ 560 RadarCfg_SendExtInfo 1 "Active" 0 "Inactive" ;
VAL_ 560 RadarCfg_CtrlRelay_valid 1 "Valid" 0 "Invalid" ;
VAL_ 560 RadarCfg_CtrlRelay 1 "Active" 0 "Inactive" ;
VAL_ 560 RadarCfg_SendQuality_valid 1 "Valid" 0 "Invalid" ;
VAL_ 560 RadarCfg_SendQuality 1 "Active" 0 "Inactive" ;
VAL_ 560 RadarCfg_MaxDistance_valid 1 "Valid" 0 "Invalid" ;
VAL_ 560 RadarCfg_OutputType_valid 1 "Valid" 0 "Invalid" ;
VAL_ 560 RadarCfg_SensorID_valid 1 "Valid" 0 "Invalid" ;
VAL_ 560 RadarCfg_OutputType 3 "reserved 2" 2 "SendClusters" 1 "SendObjects" 0 "None" ;
VAL_ 544 RadarCfg_InvalidClusters_valid 1 "Valid" 0 "Invalid" ;
VAL_ 544 RadarCfg_InvalidClusters 64 "Enable wrapped stationary" 32 "Enable ego mirror" 16 "Enable range < 1m" 8 "Enable invalid range rate" 4 "Enable low RCS static" 2 "Enable low RCS dynamic" 1 "Enable all invalid clusters" 0 "Disable" ;
VAL_ 544 RadarCfg_RCS_Threshold_Valid 1 "Valid" 0 "Invalid" ;
VAL_ 544 RadarCfg_RCS_Threshold 7 "Reserved" 6 "Reserved" 5 "Reserved" 4 "Reserved" 3 "Reserved" 2 "Reserved" 1 "High Sensitivity" 0 "Standard" ;
VAL_ 544 RadarCfg_StoreInNVM_valid 1 "Valid" 0 "Invalid" ;
VAL_ 544 RadarCfg_SortIndex_valid 1 "Valid" 0 "Invalid" ;
VAL_ 544 RadarCfg_SortIndex 2 "Sorted by RCS" 1 "Sorted by range" 0 "No sorting" ;
VAL_ 544 RadarCfg_StoreInNVM 1 "Active" 0 "Inactive" ;
VAL_ 544 RadarCfg_SendExtInfo_valid 1 "Valid" 0 "Invalid" ;
VAL_ 544 RadarCfg_SendExtInfo 1 "Active" 0 "Inactive" ;
VAL_ 544 RadarCfg_CtrlRelay_valid 1 "Valid" 0 "Invalid" ;
VAL_ 544 RadarCfg_CtrlRelay 1 "Active" 0 "Inactive" ;
VAL_ 544 RadarCfg_SendQuality_valid 1 "Valid" 0 "Invalid" ;
VAL_ 544 RadarCfg_SendQuality 1 "Active" 0 "Inactive" ;
VAL_ 544 RadarCfg_MaxDistance_valid 1 "Valid" 0 "Invalid" ;
VAL_ 544 RadarCfg_OutputType_valid 1 "Valid" 0 "Invalid" ;
VAL_ 544 RadarCfg_SensorID_valid 1 "Valid" 0 "Invalid" ;
VAL_ 544 RadarCfg_OutputType 3 "reserved 2" 2 "SendClusters" 1 "SendObjects" 0 "None" ;
VAL_ 528 RadarCfg_InvalidClusters_valid 1 "Valid" 0 "Invalid" ;
VAL_ 528 RadarCfg_InvalidClusters 64 "Enable wrapped stationary" 32 "Enable ego mirror" 16 "Enable range < 1m" 8 "Enable invalid range rate" 4 "Enable low RCS static" 2 "Enable low RCS dynamic" 1 "Enable all invalid clusters" 0 "Disable" ;
VAL_ 528 RadarCfg_RCS_Threshold_Valid 1 "Valid" 0 "Invalid" ;
VAL_ 528 RadarCfg_RCS_Threshold 7 "Reserved" 6 "Reserved" 5 "Reserved" 4 "Reserved" 3 "Reserved" 2 "Reserved" 1 "High Sensitivity" 0 "Standard" ;
VAL_ 528 RadarCfg_StoreInNVM_valid 1 "Valid" 0 "Invalid" ;
VAL_ 528 RadarCfg_SortIndex_valid 1 "Valid" 0 "Invalid" ;
VAL_ 528 RadarCfg_SortIndex 2 "Sorted by RCS" 1 "Sorted by range" 0 "No sorting" ;
VAL_ 528 RadarCfg_StoreInNVM 1 "Active" 0 "Inactive" ;
VAL_ 528 RadarCfg_SendExtInfo_valid 1 "Valid" 0 "Invalid" ;
VAL_ 528 RadarCfg_SendExtInfo 1 "Active" 0 "Inactive" ;
VAL_ 528 RadarCfg_CtrlRelay_valid 1 "Valid" 0 "Invalid" ;
VAL_ 528 RadarCfg_CtrlRelay 1 "Active" 0 "Inactive" ;
VAL_ 528 RadarCfg_SendQuality_valid 1 "Valid" 0 "Invalid" ;
VAL_ 528 RadarCfg_SendQuality 1 "Active" 0 "Inactive" ;
VAL_ 528 RadarCfg_MaxDistance_valid 1 "Valid" 0 "Invalid" ;
VAL_ 528 RadarCfg_OutputType_valid 1 "Valid" 0 "Invalid" ;
VAL_ 528 RadarCfg_SensorID_valid 1 "Valid" 0 "Invalid" ;
VAL_ 528 RadarCfg_OutputType 3 "reserved 2" 2 "SendClusters" 1 "SendObjects" 0 "None" ;
VAL_ 1661 Obj_Class 7 "Description for the value '0x7'" 6 "Wide" 5 "Bicycle" 4 "Motorcycle" 3 "Pedestrian" 2 "Truck" 1 "Car" 0 "Point" ;
VAL_ 1645 Obj_Class 7 "Description for the value '0x7'" 6 "Wide" 5 "Bicycle" 4 "Motorcycle" 3 "Pedestrian" 2 "Truck" 1 "Car" 0 "Point" ;
VAL_ 1629 Obj_Class 7 "Description for the value '0x7'" 6 "Wide" 5 "Bicycle" 4 "Motorcycle" 3 "Pedestrian" 2 "Truck" 1 "Car" 0 "Point" ;
VAL_ 1613 Obj_Class 7 "Description for the value '0x7'" 6 "Wide" 5 "Bicycle" 4 "Motorcycle" 3 "Pedestrian" 2 "Truck" 1 "Car" 0 "Point" ;
VAL_ 1597 Obj_Class 7 "Description for the value '0x7'" 6 "Wide" 5 "Bicycle" 4 "Motorcycle" 3 "Pedestrian" 2 "Truck" 1 "Car" 0 "Point" ;
VAL_ 1581 Obj_Class 7 "Description for the value '0x7'" 6 "Wide" 5 "Bicycle" 4 "Motorcycle" 3 "Pedestrian" 2 "Truck" 1 "Car" 0 "Point" ;
VAL_ 1565 Obj_Class 7 "Description for the value '0x7'" 6 "Wide" 5 "Bicycle" 4 "Motorcycle" 3 "Pedestrian" 2 "Truck" 1 "Car" 0 "Point" ;
VAL_ 1660 Obj_ProbOfExist 7 "<=100%" 6 "<99.9%" 5 "<99%" 4 "<90%" 3 "<75%" 2 "<50%" 1 "<25%" 0 "invalid" ;
VAL_ 1660 Obj_MeasState 5 "New from merge" 4 "Deleted for merge" 3 "Predicted" 2 "Measured" 1 "New" 0 "Deleted" ;
VAL_ 1660 Obj_ArelLong_rms 31 "Invalid" 30 "<10.000 m/s�" 29 "<7.762 m/s�" 28 "<6.025 m/s�" 27 "<4.676 m/s�" 26 "<3.630 m/s�" 25 "<2.817 m/s�" 24 "<2.187 m/s�" 23 "<1.697 m/s�" 22 "<1.317 m/s�" 21 "<1.023 m/s�" 20 "<0.794 m/s�" 19 "<0.616 m/s�" 18 "<0.478 m/s�" 17 "<0.371 m/s�" 16 "<0.288 m/s�" 15 "<0.224 m/s�" 14 "<0.174 m/s�" 13 "<0.135 m/s�" 12 "<0.105 m/s�" 11 "<0.081 m/s�" 10 "<0.063 m/s�" 9 "<0.049 m/s�" 8 "<0.038 m/s�" 7 "<0.029 m/s�" 6 "<0.023 m/s�" 5 "<0.018 m/s�" 4 "<0.014 m/s�" 3 "<0.011 m/s�" 2 "<0.008 m/s�" 1 "<0.006 m/s�" 0 "<0.005 m/s�" ;
VAL_ 1660 Obj_ArelLat_rms 31 "Invalid" 30 "<10.000 m/s�" 29 "<7.762 m/s�" 28 "<6.025 m/s�" 27 "<4.676 m/s�" 26 "<3.630 m/s�" 25 "<2.817 m/s�" 24 "<2.187 m/s�" 23 "<1.697 m/s�" 22 "<1.317 m/s�" 21 "<1.023 m/s�" 20 "<0.794 m/s�" 19 "<0.616 m/s�" 18 "<0.478 m/s�" 17 "<0.371 m/s�" 16 "<0.288 m/s�" 15 "<0.224 m/s�" 14 "<0.174 m/s�" 13 "<0.135 m/s�" 12 "<0.105 m/s�" 11 "<0.081 m/s�" 10 "<0.063 m/s�" 9 "<0.049 m/s�" 8 "<0.038 m/s�" 7 "<0.029 m/s�" 6 "<0.023 m/s�" 5 "<0.018 m/s�" 4 "<0.014 m/s�" 3 "<0.011 m/s�" 2 "<0.008 m/s�" 1 "<0.006 m/s�" 0 "<0.005 m/s�" ;
VAL_ 1660 Obj_VrelLong_rms 31 "Invalid" 30 "<10.000 m/s" 29 "<7.762 m/s" 28 "<6.025 m/s" 27 "<4.676 m/s" 26 "<3.630 m/s" 25 "<2.817 m/s" 24 "<2.187 m/s" 23 "<1.697 m/s" 22 "<1.317 m/s" 21 "<1.023 m/s" 20 "<0.794 m/s" 19 "<0.616 m/s" 18 "<0.478 m/s" 17 "<0.371 m/s" 16 "<0.288 m/s" 15 "<0.224 m/s" 14 "<0.174 m/s" 13 "<0.135 m/s" 12 "<0.105 m/s" 11 "<0.081 m/s" 10 "<0.063 m/s" 9 "<0.049 m/s" 8 "<0.038 m/s" 7 "<0.029 m/s" 6 "<0.023 m/s" 5 "<0.018 m/s" 4 "<0.014 m/s" 3 "<0.011 m/s" 2 "<0.008 m/s" 1 "<0.006 m/s" 0 "<0.005 m/s" ;
VAL_ 1660 Obj_VrelLat_rms 31 "Invalid" 30 "<10.000 m/s" 29 "<7.762 m/s" 28 "<6.025 m/s" 27 "<4.676 m/s" 26 "<3.630 m/s" 25 "<2.817 m/s" 24 "<2.187 m/s" 23 "<1.697 m/s" 22 "<1.317 m/s" 21 "<1.023 m/s" 20 "<0.794 m/s" 19 "<0.616 m/s" 18 "<0.478 m/s" 17 "<0.371 m/s" 16 "<0.288 m/s" 15 "<0.224 m/s" 14 "<0.174 m/s" 13 "<0.135 m/s" 12 "<0.105 m/s" 11 "<0.081 m/s" 10 "<0.063 m/s" 9 "<0.049 m/s" 8 "<0.038 m/s" 7 "<0.029 m/s" 6 "<0.023 m/s" 5 "<0.018 m/s" 4 "<0.014 m/s" 3 "<0.011 m/s" 2 "<0.008 m/s" 1 "<0.006 m/s" 0 "<0.005 m/s" ;
VAL_ 1660 Obj_Orientation_rms 31 "Invalid" 30 "<180.000 deg" 29 "<126.881 deg" 28 "<89.437 deg" 27 "<63.044 deg" 26 "<44.439 deg" 25 "<31.325 deg" 24 "<22.081 deg" 23 "<15.565 deg" 22 "<10.971 deg" 21 "<7.734 deg" 20 "<5.451 deg" 19 "<3.843 deg" 18 "<2.709 deg" 17 "<1.909 deg" 16 "<1.346 deg" 15 "<0.949 deg" 14 "<0.669 deg" 13 "<0.471 deg" 12 "<0.332 deg" 11 "<0.234 deg" 10 "<0.165 deg" 9 "<0.116 deg" 8 "<0.082 deg" 7 "<0.058 deg" 6 "<0.041 deg" 5 "<0.029 deg" 4 "<0.020 deg" 3 "<0.014 deg" 2 "<0.010 deg" 1 "<0.007 deg" 0 "<0.005 deg" ;
VAL_ 1660 Obj_DistLong_rms 31 "Invalid" 30 "<10.000 m" 29 "<7.762 m" 28 "<6.025 m" 27 "<4.676 m" 26 "<3.630 m" 25 "<2.817 m" 24 "<2.187 m" 23 "<1.697 m" 22 "<1.317 m" 21 "<1.023 m" 20 "<0.794 m" 19 "<0.616 m" 18 "<0.478 m" 17 "<0.371 m" 16 "<0.288 m" 15 "<0.224 m" 14 "<0.174 m" 13 "<0.135 m" 12 "<0.105 m" 11 "<0.081 m" 10 "<0.063 m" 9 "<0.049 m" 8 "<0.038 m" 7 "<0.029 m" 6 "<0.023 m" 5 "<0.018 m" 4 "<0.014 m" 3 "<0.011 m" 2 "<0.008 m" 1 "<0.006 m" 0 "<0.005 m" ;
VAL_ 1660 Obj_DistLat_rms 31 "Invalid" 30 "<10.000 m" 29 "<7.762 m" 28 "<6.025 m" 27 "<4.676 m" 26 "<3.630 m" 25 "<2.817 m" 24 "<2.187 m" 23 "<1.697 m" 22 "<1.317 m" 21 "<1.023 m" 20 "<0.794 m" 19 "<0.616 m" 18 "<0.478 m" 17 "<0.371 m" 16 "<0.288 m" 15 "<0.224 m" 14 "<0.174 m" 13 "<0.135 m" 12 "<0.105 m" 11 "<0.081 m" 10 "<0.063 m" 9 "<0.049 m" 8 "<0.038 m" 7 "<0.029 m" 6 "<0.023 m" 5 "<0.018 m" 4 "<0.014 m" 3 "<0.011 m" 2 "<0.008 m" 1 "<0.006 m" 0 "<0.005 m" ;
VAL_ 1644 Obj_ProbOfExist 7 "<=100%" 6 "<99.9%" 5 "<99%" 4 "<90%" 3 "<75%" 2 "<50%" 1 "<25%" 0 "invalid" ;
VAL_ 1644 Obj_MeasState 5 "New from merge" 4 "Deleted for merge" 3 "Predicted" 2 "Measured" 1 "New" 0 "Deleted" ;
VAL_ 1644 Obj_ArelLong_rms 31 "Invalid" 30 "<10.000 m/s�" 29 "<7.762 m/s�" 28 "<6.025 m/s�" 27 "<4.676 m/s�" 26 "<3.630 m/s�" 25 "<2.817 m/s�" 24 "<2.187 m/s�" 23 "<1.697 m/s�" 22 "<1.317 m/s�" 21 "<1.023 m/s�" 20 "<0.794 m/s�" 19 "<0.616 m/s�" 18 "<0.478 m/s�" 17 "<0.371 m/s�" 16 "<0.288 m/s�" 15 "<0.224 m/s�" 14 "<0.174 m/s�" 13 "<0.135 m/s�" 12 "<0.105 m/s�" 11 "<0.081 m/s�" 10 "<0.063 m/s�" 9 "<0.049 m/s�" 8 "<0.038 m/s�" 7 "<0.029 m/s�" 6 "<0.023 m/s�" 5 "<0.018 m/s�" 4 "<0.014 m/s�" 3 "<0.011 m/s�" 2 "<0.008 m/s�" 1 "<0.006 m/s�" 0 "<0.005 m/s�" ;
VAL_ 1644 Obj_ArelLat_rms 31 "Invalid" 30 "<10.000 m/s�" 29 "<7.762 m/s�" 28 "<6.025 m/s�" 27 "<4.676 m/s�" 26 "<3.630 m/s�" 25 "<2.817 m/s�" 24 "<2.187 m/s�" 23 "<1.697 m/s�" 22 "<1.317 m/s�" 21 "<1.023 m/s�" 20 "<0.794 m/s�" 19 "<0.616 m/s�" 18 "<0.478 m/s�" 17 "<0.371 m/s�" 16 "<0.288 m/s�" 15 "<0.224 m/s�" 14 "<0.174 m/s�" 13 "<0.135 m/s�" 12 "<0.105 m/s�" 11 "<0.081 m/s�" 10 "<0.063 m/s�" 9 "<0.049 m/s�" 8 "<0.038 m/s�" 7 "<0.029 m/s�" 6 "<0.023 m/s�" 5 "<0.018 m/s�" 4 "<0.014 m/s�" 3 "<0.011 m/s�" 2 "<0.008 m/s�" 1 "<0.006 m/s�" 0 "<0.005 m/s�" ;
VAL_ 1644 Obj_VrelLong_rms 31 "Invalid" 30 "<10.000 m/s" 29 "<7.762 m/s" 28 "<6.025 m/s" 27 "<4.676 m/s" 26 "<3.630 m/s" 25 "<2.817 m/s" 24 "<2.187 m/s" 23 "<1.697 m/s" 22 "<1.317 m/s" 21 "<1.023 m/s" 20 "<0.794 m/s" 19 "<0.616 m/s" 18 "<0.478 m/s" 17 "<0.371 m/s" 16 "<0.288 m/s" 15 "<0.224 m/s" 14 "<0.174 m/s" 13 "<0.135 m/s" 12 "<0.105 m/s" 11 "<0.081 m/s" 10 "<0.063 m/s" 9 "<0.049 m/s" 8 "<0.038 m/s" 7 "<0.029 m/s" 6 "<0.023 m/s" 5 "<0.018 m/s" 4 "<0.014 m/s" 3 "<0.011 m/s" 2 "<0.008 m/s" 1 "<0.006 m/s" 0 "<0.005 m/s" ;
VAL_ 1644 Obj_VrelLat_rms 31 "Invalid" 30 "<10.000 m/s" 29 "<7.762 m/s" 28 "<6.025 m/s" 27 "<4.676 m/s" 26 "<3.630 m/s" 25 "<2.817 m/s" 24 "<2.187 m/s" 23 "<1.697 m/s" 22 "<1.317 m/s" 21 "<1.023 m/s" 20 "<0.794 m/s" 19 "<0.616 m/s" 18 "<0.478 m/s" 17 "<0.371 m/s" 16 "<0.288 m/s" 15 "<0.224 m/s" 14 "<0.174 m/s" 13 "<0.135 m/s" 12 "<0.105 m/s" 11 "<0.081 m/s" 10 "<0.063 m/s" 9 "<0.049 m/s" 8 "<0.038 m/s" 7 "<0.029 m/s" 6 "<0.023 m/s" 5 "<0.018 m/s" 4 "<0.014 m/s" 3 "<0.011 m/s" 2 "<0.008 m/s" 1 "<0.006 m/s" 0 "<0.005 m/s" ;
VAL_ 1644 Obj_Orientation_rms 31 "Invalid" 30 "<180.000 deg" 29 "<126.881 deg" 28 "<89.437 deg" 27 "<63.044 deg" 26 "<44.439 deg" 25 "<31.325 deg" 24 "<22.081 deg" 23 "<15.565 deg" 22 "<10.971 deg" 21 "<7.734 deg" 20 "<5.451 deg" 19 "<3.843 deg" 18 "<2.709 deg" 17 "<1.909 deg" 16 "<1.346 deg" 15 "<0.949 deg" 14 "<0.669 deg" 13 "<0.471 deg" 12 "<0.332 deg" 11 "<0.234 deg" 10 "<0.165 deg" 9 "<0.116 deg" 8 "<0.082 deg" 7 "<0.058 deg" 6 "<0.041 deg" 5 "<0.029 deg" 4 "<0.020 deg" 3 "<0.014 deg" 2 "<0.010 deg" 1 "<0.007 deg" 0 "<0.005 deg" ;
VAL_ 1644 Obj_DistLong_rms 31 "Invalid" 30 "<10.000 m" 29 "<7.762 m" 28 "<6.025 m" 27 "<4.676 m" 26 "<3.630 m" 25 "<2.817 m" 24 "<2.187 m" 23 "<1.697 m" 22 "<1.317 m" 21 "<1.023 m" 20 "<0.794 m" 19 "<0.616 m" 18 "<0.478 m" 17 "<0.371 m" 16 "<0.288 m" 15 "<0.224 m" 14 "<0.174 m" 13 "<0.135 m" 12 "<0.105 m" 11 "<0.081 m" 10 "<0.063 m" 9 "<0.049 m" 8 "<0.038 m" 7 "<0.029 m" 6 "<0.023 m" 5 "<0.018 m" 4 "<0.014 m" 3 "<0.011 m" 2 "<0.008 m" 1 "<0.006 m" 0 "<0.005 m" ;
VAL_ 1644 Obj_DistLat_rms 31 "Invalid" 30 "<10.000 m" 29 "<7.762 m" 28 "<6.025 m" 27 "<4.676 m" 26 "<3.630 m" 25 "<2.817 m" 24 "<2.187 m" 23 "<1.697 m" 22 "<1.317 m" 21 "<1.023 m" 20 "<0.794 m" 19 "<0.616 m" 18 "<0.478 m" 17 "<0.371 m" 16 "<0.288 m" 15 "<0.224 m" 14 "<0.174 m" 13 "<0.135 m" 12 "<0.105 m" 11 "<0.081 m" 10 "<0.063 m" 9 "<0.049 m" 8 "<0.038 m" 7 "<0.029 m" 6 "<0.023 m" 5 "<0.018 m" 4 "<0.014 m" 3 "<0.011 m" 2 "<0.008 m" 1 "<0.006 m" 0 "<0.005 m" ;
VAL_ 1628 Obj_ProbOfExist 7 "<=100%" 6 "<99.9%" 5 "<99%" 4 "<90%" 3 "<75%" 2 "<50%" 1 "<25%" 0 "invalid" ;
VAL_ 1628 Obj_MeasState 5 "New from merge" 4 "Deleted for merge" 3 "Predicted" 2 "Measured" 1 "New" 0 "Deleted" ;
VAL_ 1628 Obj_ArelLong_rms 31 "Invalid" 30 "<10.000 m/s�" 29 "<7.762 m/s�" 28 "<6.025 m/s�" 27 "<4.676 m/s�" 26 "<3.630 m/s�" 25 "<2.817 m/s�" 24 "<2.187 m/s�" 23 "<1.697 m/s�" 22 "<1.317 m/s�" 21 "<1.023 m/s�" 20 "<0.794 m/s�" 19 "<0.616 m/s�" 18 "<0.478 m/s�" 17 "<0.371 m/s�" 16 "<0.288 m/s�" 15 "<0.224 m/s�" 14 "<0.174 m/s�" 13 "<0.135 m/s�" 12 "<0.105 m/s�" 11 "<0.081 m/s�" 10 "<0.063 m/s�" 9 "<0.049 m/s�" 8 "<0.038 m/s�" 7 "<0.029 m/s�" 6 "<0.023 m/s�" 5 "<0.018 m/s�" 4 "<0.014 m/s�" 3 "<0.011 m/s�" 2 "<0.008 m/s�" 1 "<0.006 m/s�" 0 "<0.005 m/s�" ;
VAL_ 1628 Obj_ArelLat_rms 31 "Invalid" 30 "<10.000 m/s�" 29 "<7.762 m/s�" 28 "<6.025 m/s�" 27 "<4.676 m/s�" 26 "<3.630 m/s�" 25 "<2.817 m/s�" 24 "<2.187 m/s�" 23 "<1.697 m/s�" 22 "<1.317 m/s�" 21 "<1.023 m/s�" 20 "<0.794 m/s�" 19 "<0.616 m/s�" 18 "<0.478 m/s�" 17 "<0.371 m/s�" 16 "<0.288 m/s�" 15 "<0.224 m/s�" 14 "<0.174 m/s�" 13 "<0.135 m/s�" 12 "<0.105 m/s�" 11 "<0.081 m/s�" 10 "<0.063 m/s�" 9 "<0.049 m/s�" 8 "<0.038 m/s�" 7 "<0.029 m/s�" 6 "<0.023 m/s�" 5 "<0.018 m/s�" 4 "<0.014 m/s�" 3 "<0.011 m/s�" 2 "<0.008 m/s�" 1 "<0.006 m/s�" 0 "<0.005 m/s�" ;
VAL_ 1628 Obj_VrelLong_rms 31 "Invalid" 30 "<10.000 m/s" 29 "<7.762 m/s" 28 "<6.025 m/s" 27 "<4.676 m/s" 26 "<3.630 m/s" 25 "<2.817 m/s" 24 "<2.187 m/s" 23 "<1.697 m/s" 22 "<1.317 m/s" 21 "<1.023 m/s" 20 "<0.794 m/s" 19 "<0.616 m/s" 18 "<0.478 m/s" 17 "<0.371 m/s" 16 "<0.288 m/s" 15 "<0.224 m/s" 14 "<0.174 m/s" 13 "<0.135 m/s" 12 "<0.105 m/s" 11 "<0.081 m/s" 10 "<0.063 m/s" 9 "<0.049 m/s" 8 "<0.038 m/s" 7 "<0.029 m/s" 6 "<0.023 m/s" 5 "<0.018 m/s" 4 "<0.014 m/s" 3 "<0.011 m/s" 2 "<0.008 m/s" 1 "<0.006 m/s" 0 "<0.005 m/s" ;
VAL_ 1628 Obj_VrelLat_rms 31 "Invalid" 30 "<10.000 m/s" 29 "<7.762 m/s" 28 "<6.025 m/s" 27 "<4.676 m/s" 26 "<3.630 m/s" 25 "<2.817 m/s" 24 "<2.187 m/s" 23 "<1.697 m/s" 22 "<1.317 m/s" 21 "<1.023 m/s" 20 "<0.794 m/s" 19 "<0.616 m/s" 18 "<0.478 m/s" 17 "<0.371 m/s" 16 "<0.288 m/s" 15 "<0.224 m/s" 14 "<0.174 m/s" 13 "<0.135 m/s" 12 "<0.105 m/s" 11 "<0.081 m/s" 10 "<0.063 m/s" 9 "<0.049 m/s" 8 "<0.038 m/s" 7 "<0.029 m/s" 6 "<0.023 m/s" 5 "<0.018 m/s" 4 "<0.014 m/s" 3 "<0.011 m/s" 2 "<0.008 m/s" 1 "<0.006 m/s" 0 "<0.005 m/s" ;
VAL_ 1628 Obj_Orientation_rms 31 "Invalid" 30 "<180.000 deg" 29 "<126.881 deg" 28 "<89.437 deg" 27 "<63.044 deg" 26 "<44.439 deg" 25 "<31.325 deg" 24 "<22.081 deg" 23 "<15.565 deg" 22 "<10.971 deg" 21 "<7.734 deg" 20 "<5.451 deg" 19 "<3.843 deg" 18 "<2.709 deg" 17 "<1.909 deg" 16 "<1.346 deg" 15 "<0.949 deg" 14 "<0.669 deg" 13 "<0.471 deg" 12 "<0.332 deg" 11 "<0.234 deg" 10 "<0.165 deg" 9 "<0.116 deg" 8 "<0.082 deg" 7 "<0.058 deg" 6 "<0.041 deg" 5 "<0.029 deg" 4 "<0.020 deg" 3 "<0.014 deg" 2 "<0.010 deg" 1 "<0.007 deg" 0 "<0.005 deg" ;
VAL_ 1628 Obj_DistLong_rms 31 "Invalid" 30 "<10.000 m" 29 "<7.762 m" 28 "<6.025 m" 27 "<4.676 m" 26 "<3.630 m" 25 "<2.817 m" 24 "<2.187 m" 23 "<1.697 m" 22 "<1.317 m" 21 "<1.023 m" 20 "<0.794 m" 19 "<0.616 m" 18 "<0.478 m" 17 "<0.371 m" 16 "<0.288 m" 15 "<0.224 m" 14 "<0.174 m" 13 "<0.135 m" 12 "<0.105 m" 11 "<0.081 m" 10 "<0.063 m" 9 "<0.049 m" 8 "<0.038 m" 7 "<0.029 m" 6 "<0.023 m" 5 "<0.018 m" 4 "<0.014 m" 3 "<0.011 m" 2 "<0.008 m" 1 "<0.006 m" 0 "<0.005 m" ;
VAL_ 1628 Obj_DistLat_rms 31 "Invalid" 30 "<10.000 m" 29 "<7.762 m" 28 "<6.025 m" 27 "<4.676 m" 26 "<3.630 m" 25 "<2.817 m" 24 "<2.187 m" 23 "<1.697 m" 22 "<1.317 m" 21 "<1.023 m" 20 "<0.794 m" 19 "<0.616 m" 18 "<0.478 m" 17 "<0.371 m" 16 "<0.288 m" 15 "<0.224 m" 14 "<0.174 m" 13 "<0.135 m" 12 "<0.105 m" 11 "<0.081 m" 10 "<0.063 m" 9 "<0.049 m" 8 "<0.038 m" 7 "<0.029 m" 6 "<0.023 m" 5 "<0.018 m" 4 "<0.014 m" 3 "<0.011 m" 2 "<0.008 m" 1 "<0.006 m" 0 "<0.005 m" ;
VAL_ 1612 Obj_ProbOfExist 7 "<=100%" 6 "<99.9%" 5 "<99%" 4 "<90%" 3 "<75%" 2 "<50%" 1 "<25%" 0 "invalid" ;
VAL_ 1612 Obj_MeasState 5 "New from merge" 4 "Deleted for merge" 3 "Predicted" 2 "Measured" 1 "New" 0 "Deleted" ;
VAL_ 1612 Obj_ArelLong_rms 31 "Invalid" 30 "<10.000 m/s�" 29 "<7.762 m/s�" 28 "<6.025 m/s�" 27 "<4.676 m/s�" 26 "<3.630 m/s�" 25 "<2.817 m/s�" 24 "<2.187 m/s�" 23 "<1.697 m/s�" 22 "<1.317 m/s�" 21 "<1.023 m/s�" 20 "<0.794 m/s�" 19 "<0.616 m/s�" 18 "<0.478 m/s�" 17 "<0.371 m/s�" 16 "<0.288 m/s�" 15 "<0.224 m/s�" 14 "<0.174 m/s�" 13 "<0.135 m/s�" 12 "<0.105 m/s�" 11 "<0.081 m/s�" 10 "<0.063 m/s�" 9 "<0.049 m/s�" 8 "<0.038 m/s�" 7 "<0.029 m/s�" 6 "<0.023 m/s�" 5 "<0.018 m/s�" 4 "<0.014 m/s�" 3 "<0.011 m/s�" 2 "<0.008 m/s�" 1 "<0.006 m/s�" 0 "<0.005 m/s�" ;
VAL_ 1612 Obj_ArelLat_rms 31 "Invalid" 30 "<10.000 m/s�" 29 "<7.762 m/s�" 28 "<6.025 m/s�" 27 "<4.676 m/s�" 26 "<3.630 m/s�" 25 "<2.817 m/s�" 24 "<2.187 m/s�" 23 "<1.697 m/s�" 22 "<1.317 m/s�" 21 "<1.023 m/s�" 20 "<0.794 m/s�" 19 "<0.616 m/s�" 18 "<0.478 m/s�" 17 "<0.371 m/s�" 16 "<0.288 m/s�" 15 "<0.224 m/s�" 14 "<0.174 m/s�" 13 "<0.135 m/s�" 12 "<0.105 m/s�" 11 "<0.081 m/s�" 10 "<0.063 m/s�" 9 "<0.049 m/s�" 8 "<0.038 m/s�" 7 "<0.029 m/s�" 6 "<0.023 m/s�" 5 "<0.018 m/s�" 4 "<0.014 m/s�" 3 "<0.011 m/s�" 2 "<0.008 m/s�" 1 "<0.006 m/s�" 0 "<0.005 m/s�" ;
VAL_ 1612 Obj_VrelLong_rms 31 "Invalid" 30 "<10.000 m/s" 29 "<7.762 m/s" 28 "<6.025 m/s" 27 "<4.676 m/s" 26 "<3.630 m/s" 25 "<2.817 m/s" 24 "<2.187 m/s" 23 "<1.697 m/s" 22 "<1.317 m/s" 21 "<1.023 m/s" 20 "<0.794 m/s" 19 "<0.616 m/s" 18 "<0.478 m/s" 17 "<0.371 m/s" 16 "<0.288 m/s" 15 "<0.224 m/s" 14 "<0.174 m/s" 13 "<0.135 m/s" 12 "<0.105 m/s" 11 "<0.081 m/s" 10 "<0.063 m/s" 9 "<0.049 m/s" 8 "<0.038 m/s" 7 "<0.029 m/s" 6 "<0.023 m/s" 5 "<0.018 m/s" 4 "<0.014 m/s" 3 "<0.011 m/s" 2 "<0.008 m/s" 1 "<0.006 m/s" 0 "<0.005 m/s" ;
VAL_ 1612 Obj_VrelLat_rms 31 "Invalid" 30 "<10.000 m/s" 29 "<7.762 m/s" 28 "<6.025 m/s" 27 "<4.676 m/s" 26 "<3.630 m/s" 25 "<2.817 m/s" 24 "<2.187 m/s" 23 "<1.697 m/s" 22 "<1.317 m/s" 21 "<1.023 m/s" 20 "<0.794 m/s" 19 "<0.616 m/s" 18 "<0.478 m/s" 17 "<0.371 m/s" 16 "<0.288 m/s" 15 "<0.224 m/s" 14 "<0.174 m/s" 13 "<0.135 m/s" 12 "<0.105 m/s" 11 "<0.081 m/s" 10 "<0.063 m/s" 9 "<0.049 m/s" 8 "<0.038 m/s" 7 "<0.029 m/s" 6 "<0.023 m/s" 5 "<0.018 m/s" 4 "<0.014 m/s" 3 "<0.011 m/s" 2 "<0.008 m/s" 1 "<0.006 m/s" 0 "<0.005 m/s" ;
VAL_ 1612 Obj_Orientation_rms 31 "Invalid" 30 "<180.000 deg" 29 "<126.881 deg" 28 "<89.437 deg" 27 "<63.044 deg" 26 "<44.439 deg" 25 "<31.325 deg" 24 "<22.081 deg" 23 "<15.565 deg" 22 "<10.971 deg" 21 "<7.734 deg" 20 "<5.451 deg" 19 "<3.843 deg" 18 "<2.709 deg" 17 "<1.909 deg" 16 "<1.346 deg" 15 "<0.949 deg" 14 "<0.669 deg" 13 "<0.471 deg" 12 "<0.332 deg" 11 "<0.234 deg" 10 "<0.165 deg" 9 "<0.116 deg" 8 "<0.082 deg" 7 "<0.058 deg" 6 "<0.041 deg" 5 "<0.029 deg" 4 "<0.020 deg" 3 "<0.014 deg" 2 "<0.010 deg" 1 "<0.007 deg" 0 "<0.005 deg" ;
VAL_ 1612 Obj_DistLong_rms 31 "Invalid" 30 "<10.000 m" 29 "<7.762 m" 28 "<6.025 m" 27 "<4.676 m" 26 "<3.630 m" 25 "<2.817 m" 24 "<2.187 m" 23 "<1.697 m" 22 "<1.317 m" 21 "<1.023 m" 20 "<0.794 m" 19 "<0.616 m" 18 "<0.478 m" 17 "<0.371 m" 16 "<0.288 m" 15 "<0.224 m" 14 "<0.174 m" 13 "<0.135 m" 12 "<0.105 m" 11 "<0.081 m" 10 "<0.063 m" 9 "<0.049 m" 8 "<0.038 m" 7 "<0.029 m" 6 "<0.023 m" 5 "<0.018 m" 4 "<0.014 m" 3 "<0.011 m" 2 "<0.008 m" 1 "<0.006 m" 0 "<0.005 m" ;
VAL_ 1612 Obj_DistLat_rms 31 "Invalid" 30 "<10.000 m" 29 "<7.762 m" 28 "<6.025 m" 27 "<4.676 m" 26 "<3.630 m" 25 "<2.817 m" 24 "<2.187 m" 23 "<1.697 m" 22 "<1.317 m" 21 "<1.023 m" 20 "<0.794 m" 19 "<0.616 m" 18 "<0.478 m" 17 "<0.371 m" 16 "<0.288 m" 15 "<0.224 m" 14 "<0.174 m" 13 "<0.135 m" 12 "<0.105 m" 11 "<0.081 m" 10 "<0.063 m" 9 "<0.049 m" 8 "<0.038 m" 7 "<0.029 m" 6 "<0.023 m" 5 "<0.018 m" 4 "<0.014 m" 3 "<0.011 m" 2 "<0.008 m" 1 "<0.006 m" 0 "<0.005 m" ;
VAL_ 1596 Obj_ProbOfExist 7 "<=100%" 6 "<99.9%" 5 "<99%" 4 "<90%" 3 "<75%" 2 "<50%" 1 "<25%" 0 "invalid" ;
VAL_ 1596 Obj_MeasState 5 "New from merge" 4 "Deleted for merge" 3 "Predicted" 2 "Measured" 1 "New" 0 "Deleted" ;
VAL_ 1596 Obj_ArelLong_rms 31 "Invalid" 30 "<10.000 m/s�" 29 "<7.762 m/s�" 28 "<6.025 m/s�" 27 "<4.676 m/s�" 26 "<3.630 m/s�" 25 "<2.817 m/s�" 24 "<2.187 m/s�" 23 "<1.697 m/s�" 22 "<1.317 m/s�" 21 "<1.023 m/s�" 20 "<0.794 m/s�" 19 "<0.616 m/s�" 18 "<0.478 m/s�" 17 "<0.371 m/s�" 16 "<0.288 m/s�" 15 "<0.224 m/s�" 14 "<0.174 m/s�" 13 "<0.135 m/s�" 12 "<0.105 m/s�" 11 "<0.081 m/s�" 10 "<0.063 m/s�" 9 "<0.049 m/s�" 8 "<0.038 m/s�" 7 "<0.029 m/s�" 6 "<0.023 m/s�" 5 "<0.018 m/s�" 4 "<0.014 m/s�" 3 "<0.011 m/s�" 2 "<0.008 m/s�" 1 "<0.006 m/s�" 0 "<0.005 m/s�" ;
VAL_ 1596 Obj_ArelLat_rms 31 "Invalid" 30 "<10.000 m/s�" 29 "<7.762 m/s�" 28 "<6.025 m/s�" 27 "<4.676 m/s�" 26 "<3.630 m/s�" 25 "<2.817 m/s�" 24 "<2.187 m/s�" 23 "<1.697 m/s�" 22 "<1.317 m/s�" 21 "<1.023 m/s�" 20 "<0.794 m/s�" 19 "<0.616 m/s�" 18 "<0.478 m/s�" 17 "<0.371 m/s�" 16 "<0.288 m/s�" 15 "<0.224 m/s�" 14 "<0.174 m/s�" 13 "<0.135 m/s�" 12 "<0.105 m/s�" 11 "<0.081 m/s�" 10 "<0.063 m/s�" 9 "<0.049 m/s�" 8 "<0.038 m/s�" 7 "<0.029 m/s�" 6 "<0.023 m/s�" 5 "<0.018 m/s�" 4 "<0.014 m/s�" 3 "<0.011 m/s�" 2 "<0.008 m/s�" 1 "<0.006 m/s�" 0 "<0.005 m/s�" ;
VAL_ 1596 Obj_VrelLong_rms 31 "Invalid" 30 "<10.000 m/s" 29 "<7.762 m/s" 28 "<6.025 m/s" 27 "<4.676 m/s" 26 "<3.630 m/s" 25 "<2.817 m/s" 24 "<2.187 m/s" 23 "<1.697 m/s" 22 "<1.317 m/s" 21 "<1.023 m/s" 20 "<0.794 m/s" 19 "<0.616 m/s" 18 "<0.478 m/s" 17 "<0.371 m/s" 16 "<0.288 m/s" 15 "<0.224 m/s" 14 "<0.174 m/s" 13 "<0.135 m/s" 12 "<0.105 m/s" 11 "<0.081 m/s" 10 "<0.063 m/s" 9 "<0.049 m/s" 8 "<0.038 m/s" 7 "<0.029 m/s" 6 "<0.023 m/s" 5 "<0.018 m/s" 4 "<0.014 m/s" 3 "<0.011 m/s" 2 "<0.008 m/s" 1 "<0.006 m/s" 0 "<0.005 m/s" ;
VAL_ 1596 Obj_VrelLat_rms 31 "Invalid" 30 "<10.000 m/s" 29 "<7.762 m/s" 28 "<6.025 m/s" 27 "<4.676 m/s" 26 "<3.630 m/s" 25 "<2.817 m/s" 24 "<2.187 m/s" 23 "<1.697 m/s" 22 "<1.317 m/s" 21 "<1.023 m/s" 20 "<0.794 m/s" 19 "<0.616 m/s" 18 "<0.478 m/s" 17 "<0.371 m/s" 16 "<0.288 m/s" 15 "<0.224 m/s" 14 "<0.174 m/s" 13 "<0.135 m/s" 12 "<0.105 m/s" 11 "<0.081 m/s" 10 "<0.063 m/s" 9 "<0.049 m/s" 8 "<0.038 m/s" 7 "<0.029 m/s" 6 "<0.023 m/s" 5 "<0.018 m/s" 4 "<0.014 m/s" 3 "<0.011 m/s" 2 "<0.008 m/s" 1 "<0.006 m/s" 0 "<0.005 m/s" ;
VAL_ 1596 Obj_Orientation_rms 31 "Invalid" 30 "<180.000 deg" 29 "<126.881 deg" 28 "<89.437 deg" 27 "<63.044 deg" 26 "<44.439 deg" 25 "<31.325 deg" 24 "<22.081 deg" 23 "<15.565 deg" 22 "<10.971 deg" 21 "<7.734 deg" 20 "<5.451 deg" 19 "<3.843 deg" 18 "<2.709 deg" 17 "<1.909 deg" 16 "<1.346 deg" 15 "<0.949 deg" 14 "<0.669 deg" 13 "<0.471 deg" 12 "<0.332 deg" 11 "<0.234 deg" 10 "<0.165 deg" 9 "<0.116 deg" 8 "<0.082 deg" 7 "<0.058 deg" 6 "<0.041 deg" 5 "<0.029 deg" 4 "<0.020 deg" 3 "<0.014 deg" 2 "<0.010 deg" 1 "<0.007 deg" 0 "<0.005 deg" ;
VAL_ 1596 Obj_DistLong_rms 31 "Invalid" 30 "<10.000 m" 29 "<7.762 m" 28 "<6.025 m" 27 "<4.676 m" 26 "<3.630 m" 25 "<2.817 m" 24 "<2.187 m" 23 "<1.697 m" 22 "<1.317 m" 21 "<1.023 m" 20 "<0.794 m" 19 "<0.616 m" 18 "<0.478 m" 17 "<0.371 m" 16 "<0.288 m" 15 "<0.224 m" 14 "<0.174 m" 13 "<0.135 m" 12 "<0.105 m" 11 "<0.081 m" 10 "<0.063 m" 9 "<0.049 m" 8 "<0.038 m" 7 "<0.029 m" 6 "<0.023 m" 5 "<0.018 m" 4 "<0.014 m" 3 "<0.011 m" 2 "<0.008 m" 1 "<0.006 m" 0 "<0.005 m" ;
VAL_ 1596 Obj_DistLat_rms 31 "Invalid" 30 "<10.000 m" 29 "<7.762 m" 28 "<6.025 m" 27 "<4.676 m" 26 "<3.630 m" 25 "<2.817 m" 24 "<2.187 m" 23 "<1.697 m" 22 "<1.317 m" 21 "<1.023 m" 20 "<0.794 m" 19 "<0.616 m" 18 "<0.478 m" 17 "<0.371 m" 16 "<0.288 m" 15 "<0.224 m" 14 "<0.174 m" 13 "<0.135 m" 12 "<0.105 m" 11 "<0.081 m" 10 "<0.063 m" 9 "<0.049 m" 8 "<0.038 m" 7 "<0.029 m" 6 "<0.023 m" 5 "<0.018 m" 4 "<0.014 m" 3 "<0.011 m" 2 "<0.008 m" 1 "<0.006 m" 0 "<0.005 m" ;
VAL_ 1580 Obj_ProbOfExist 7 "<=100%" 6 "<99.9%" 5 "<99%" 4 "<90%" 3 "<75%" 2 "<50%" 1 "<25%" 0 "invalid" ;
VAL_ 1580 Obj_MeasState 5 "New from merge" 4 "Deleted for merge" 3 "Predicted" 2 "Measured" 1 "New" 0 "Deleted" ;
VAL_ 1580 Obj_ArelLong_rms 31 "Invalid" 30 "<10.000 m/s�" 29 "<7.762 m/s�" 28 "<6.025 m/s�" 27 "<4.676 m/s�" 26 "<3.630 m/s�" 25 "<2.817 m/s�" 24 "<2.187 m/s�" 23 "<1.697 m/s�" 22 "<1.317 m/s�" 21 "<1.023 m/s�" 20 "<0.794 m/s�" 19 "<0.616 m/s�" 18 "<0.478 m/s�" 17 "<0.371 m/s�" 16 "<0.288 m/s�" 15 "<0.224 m/s�" 14 "<0.174 m/s�" 13 "<0.135 m/s�" 12 "<0.105 m/s�" 11 "<0.081 m/s�" 10 "<0.063 m/s�" 9 "<0.049 m/s�" 8 "<0.038 m/s�" 7 "<0.029 m/s�" 6 "<0.023 m/s�" 5 "<0.018 m/s�" 4 "<0.014 m/s�" 3 "<0.011 m/s�" 2 "<0.008 m/s�" 1 "<0.006 m/s�" 0 "<0.005 m/s�" ;
VAL_ 1580 Obj_ArelLat_rms 31 "Invalid" 30 "<10.000 m/s�" 29 "<7.762 m/s�" 28 "<6.025 m/s�" 27 "<4.676 m/s�" 26 "<3.630 m/s�" 25 "<2.817 m/s�" 24 "<2.187 m/s�" 23 "<1.697 m/s�" 22 "<1.317 m/s�" 21 "<1.023 m/s�" 20 "<0.794 m/s�" 19 "<0.616 m/s�" 18 "<0.478 m/s�" 17 "<0.371 m/s�" 16 "<0.288 m/s�" 15 "<0.224 m/s�" 14 "<0.174 m/s�" 13 "<0.135 m/s�" 12 "<0.105 m/s�" 11 "<0.081 m/s�" 10 "<0.063 m/s�" 9 "<0.049 m/s�" 8 "<0.038 m/s�" 7 "<0.029 m/s�" 6 "<0.023 m/s�" 5 "<0.018 m/s�" 4 "<0.014 m/s�" 3 "<0.011 m/s�" 2 "<0.008 m/s�" 1 "<0.006 m/s�" 0 "<0.005 m/s�" ;
VAL_ 1580 Obj_VrelLong_rms 31 "Invalid" 30 "<10.000 m/s" 29 "<7.762 m/s" 28 "<6.025 m/s" 27 "<4.676 m/s" 26 "<3.630 m/s" 25 "<2.817 m/s" 24 "<2.187 m/s" 23 "<1.697 m/s" 22 "<1.317 m/s" 21 "<1.023 m/s" 20 "<0.794 m/s" 19 "<0.616 m/s" 18 "<0.478 m/s" 17 "<0.371 m/s" 16 "<0.288 m/s" 15 "<0.224 m/s" 14 "<0.174 m/s" 13 "<0.135 m/s" 12 "<0.105 m/s" 11 "<0.081 m/s" 10 "<0.063 m/s" 9 "<0.049 m/s" 8 "<0.038 m/s" 7 "<0.029 m/s" 6 "<0.023 m/s" 5 "<0.018 m/s" 4 "<0.014 m/s" 3 "<0.011 m/s" 2 "<0.008 m/s" 1 "<0.006 m/s" 0 "<0.005 m/s" ;
VAL_ 1580 Obj_VrelLat_rms 31 "Invalid" 30 "<10.000 m/s" 29 "<7.762 m/s" 28 "<6.025 m/s" 27 "<4.676 m/s" 26 "<3.630 m/s" 25 "<2.817 m/s" 24 "<2.187 m/s" 23 "<1.697 m/s" 22 "<1.317 m/s" 21 "<1.023 m/s" 20 "<0.794 m/s" 19 "<0.616 m/s" 18 "<0.478 m/s" 17 "<0.371 m/s" 16 "<0.288 m/s" 15 "<0.224 m/s" 14 "<0.174 m/s" 13 "<0.135 m/s" 12 "<0.105 m/s" 11 "<0.081 m/s" 10 "<0.063 m/s" 9 "<0.049 m/s" 8 "<0.038 m/s" 7 "<0.029 m/s" 6 "<0.023 m/s" 5 "<0.018 m/s" 4 "<0.014 m/s" 3 "<0.011 m/s" 2 "<0.008 m/s" 1 "<0.006 m/s" 0 "<0.005 m/s" ;
VAL_ 1580 Obj_Orientation_rms 31 "Invalid" 30 "<180.000 deg" 29 "<126.881 deg" 28 "<89.437 deg" 27 "<63.044 deg" 26 "<44.439 deg" 25 "<31.325 deg" 24 "<22.081 deg" 23 "<15.565 deg" 22 "<10.971 deg" 21 "<7.734 deg" 20 "<5.451 deg" 19 "<3.843 deg" 18 "<2.709 deg" 17 "<1.909 deg" 16 "<1.346 deg" 15 "<0.949 deg" 14 "<0.669 deg" 13 "<0.471 deg" 12 "<0.332 deg" 11 "<0.234 deg" 10 "<0.165 deg" 9 "<0.116 deg" 8 "<0.082 deg" 7 "<0.058 deg" 6 "<0.041 deg" 5 "<0.029 deg" 4 "<0.020 deg" 3 "<0.014 deg" 2 "<0.010 deg" 1 "<0.007 deg" 0 "<0.005 deg" ;
VAL_ 1580 Obj_DistLong_rms 31 "Invalid" 30 "<10.000 m" 29 "<7.762 m" 28 "<6.025 m" 27 "<4.676 m" 26 "<3.630 m" 25 "<2.817 m" 24 "<2.187 m" 23 "<1.697 m" 22 "<1.317 m" 21 "<1.023 m" 20 "<0.794 m" 19 "<0.616 m" 18 "<0.478 m" 17 "<0.371 m" 16 "<0.288 m" 15 "<0.224 m" 14 "<0.174 m" 13 "<0.135 m" 12 "<0.105 m" 11 "<0.081 m" 10 "<0.063 m" 9 "<0.049 m" 8 "<0.038 m" 7 "<0.029 m" 6 "<0.023 m" 5 "<0.018 m" 4 "<0.014 m" 3 "<0.011 m" 2 "<0.008 m" 1 "<0.006 m" 0 "<0.005 m" ;
VAL_ 1580 Obj_DistLat_rms 31 "Invalid" 30 "<10.000 m" 29 "<7.762 m" 28 "<6.025 m" 27 "<4.676 m" 26 "<3.630 m" 25 "<2.817 m" 24 "<2.187 m" 23 "<1.697 m" 22 "<1.317 m" 21 "<1.023 m" 20 "<0.794 m" 19 "<0.616 m" 18 "<0.478 m" 17 "<0.371 m" 16 "<0.288 m" 15 "<0.224 m" 14 "<0.174 m" 13 "<0.135 m" 12 "<0.105 m" 11 "<0.081 m" 10 "<0.063 m" 9 "<0.049 m" 8 "<0.038 m" 7 "<0.029 m" 6 "<0.023 m" 5 "<0.018 m" 4 "<0.014 m" 3 "<0.011 m" 2 "<0.008 m" 1 "<0.006 m" 0 "<0.005 m" ;
VAL_ 1564 Obj_ProbOfExist 7 "<=100%" 6 "<99.9%" 5 "<99%" 4 "<90%" 3 "<75%" 2 "<50%" 1 "<25%" 0 "invalid" ;
VAL_ 1564 Obj_MeasState 5 "New from merge" 4 "Deleted for merge" 3 "Predicted" 2 "Measured" 1 "New" 0 "Deleted" ;
VAL_ 1564 Obj_ArelLong_rms 31 "Invalid" 30 "<10.000 m/s�" 29 "<7.762 m/s�" 28 "<6.025 m/s�" 27 "<4.676 m/s�" 26 "<3.630 m/s�" 25 "<2.817 m/s�" 24 "<2.187 m/s�" 23 "<1.697 m/s�" 22 "<1.317 m/s�" 21 "<1.023 m/s�" 20 "<0.794 m/s�" 19 "<0.616 m/s�" 18 "<0.478 m/s�" 17 "<0.371 m/s�" 16 "<0.288 m/s�" 15 "<0.224 m/s�" 14 "<0.174 m/s�" 13 "<0.135 m/s�" 12 "<0.105 m/s�" 11 "<0.081 m/s�" 10 "<0.063 m/s�" 9 "<0.049 m/s�" 8 "<0.038 m/s�" 7 "<0.029 m/s�" 6 "<0.023 m/s�" 5 "<0.018 m/s�" 4 "<0.014 m/s�" 3 "<0.011 m/s�" 2 "<0.008 m/s�" 1 "<0.006 m/s�" 0 "<0.005 m/s�" ;
VAL_ 1564 Obj_ArelLat_rms 31 "Invalid" 30 "<10.000 m/s�" 29 "<7.762 m/s�" 28 "<6.025 m/s�" 27 "<4.676 m/s�" 26 "<3.630 m/s�" 25 "<2.817 m/s�" 24 "<2.187 m/s�" 23 "<1.697 m/s�" 22 "<1.317 m/s�" 21 "<1.023 m/s�" 20 "<0.794 m/s�" 19 "<0.616 m/s�" 18 "<0.478 m/s�" 17 "<0.371 m/s�" 16 "<0.288 m/s�" 15 "<0.224 m/s�" 14 "<0.174 m/s�" 13 "<0.135 m/s�" 12 "<0.105 m/s�" 11 "<0.081 m/s�" 10 "<0.063 m/s�" 9 "<0.049 m/s�" 8 "<0.038 m/s�" 7 "<0.029 m/s�" 6 "<0.023 m/s�" 5 "<0.018 m/s�" 4 "<0.014 m/s�" 3 "<0.011 m/s�" 2 "<0.008 m/s�" 1 "<0.006 m/s�" 0 "<0.005 m/s�" ;
VAL_ 1564 Obj_VrelLong_rms 31 "Invalid" 30 "<10.000 m/s" 29 "<7.762 m/s" 28 "<6.025 m/s" 27 "<4.676 m/s" 26 "<3.630 m/s" 25 "<2.817 m/s" 24 "<2.187 m/s" 23 "<1.697 m/s" 22 "<1.317 m/s" 21 "<1.023 m/s" 20 "<0.794 m/s" 19 "<0.616 m/s" 18 "<0.478 m/s" 17 "<0.371 m/s" 16 "<0.288 m/s" 15 "<0.224 m/s" 14 "<0.174 m/s" 13 "<0.135 m/s" 12 "<0.105 m/s" 11 "<0.081 m/s" 10 "<0.063 m/s" 9 "<0.049 m/s" 8 "<0.038 m/s" 7 "<0.029 m/s" 6 "<0.023 m/s" 5 "<0.018 m/s" 4 "<0.014 m/s" 3 "<0.011 m/s" 2 "<0.008 m/s" 1 "<0.006 m/s" 0 "<0.005 m/s" ;
VAL_ 1564 Obj_VrelLat_rms 31 "Invalid" 30 "<10.000 m/s" 29 "<7.762 m/s" 28 "<6.025 m/s" 27 "<4.676 m/s" 26 "<3.630 m/s" 25 "<2.817 m/s" 24 "<2.187 m/s" 23 "<1.697 m/s" 22 "<1.317 m/s" 21 "<1.023 m/s" 20 "<0.794 m/s" 19 "<0.616 m/s" 18 "<0.478 m/s" 17 "<0.371 m/s" 16 "<0.288 m/s" 15 "<0.224 m/s" 14 "<0.174 m/s" 13 "<0.135 m/s" 12 "<0.105 m/s" 11 "<0.081 m/s" 10 "<0.063 m/s" 9 "<0.049 m/s" 8 "<0.038 m/s" 7 "<0.029 m/s" 6 "<0.023 m/s" 5 "<0.018 m/s" 4 "<0.014 m/s" 3 "<0.011 m/s" 2 "<0.008 m/s" 1 "<0.006 m/s" 0 "<0.005 m/s" ;
VAL_ 1564 Obj_Orientation_rms 31 "Invalid" 30 "<180.000 deg" 29 "<126.881 deg" 28 "<89.437 deg" 27 "<63.044 deg" 26 "<44.439 deg" 25 "<31.325 deg" 24 "<22.081 deg" 23 "<15.565 deg" 22 "<10.971 deg" 21 "<7.734 deg" 20 "<5.451 deg" 19 "<3.843 deg" 18 "<2.709 deg" 17 "<1.909 deg" 16 "<1.346 deg" 15 "<0.949 deg" 14 "<0.669 deg" 13 "<0.471 deg" 12 "<0.332 deg" 11 "<0.234 deg" 10 "<0.165 deg" 9 "<0.116 deg" 8 "<0.082 deg" 7 "<0.058 deg" 6 "<0.041 deg" 5 "<0.029 deg" 4 "<0.020 deg" 3 "<0.014 deg" 2 "<0.010 deg" 1 "<0.007 deg" 0 "<0.005 deg" ;
VAL_ 1564 Obj_DistLong_rms 31 "Invalid" 30 "<10.000 m" 29 "<7.762 m" 28 "<6.025 m" 27 "<4.676 m" 26 "<3.630 m" 25 "<2.817 m" 24 "<2.187 m" 23 "<1.697 m" 22 "<1.317 m" 21 "<1.023 m" 20 "<0.794 m" 19 "<0.616 m" 18 "<0.478 m" 17 "<0.371 m" 16 "<0.288 m" 15 "<0.224 m" 14 "<0.174 m" 13 "<0.135 m" 12 "<0.105 m" 11 "<0.081 m" 10 "<0.063 m" 9 "<0.049 m" 8 "<0.038 m" 7 "<0.029 m" 6 "<0.023 m" 5 "<0.018 m" 4 "<0.014 m" 3 "<0.011 m" 2 "<0.008 m" 1 "<0.006 m" 0 "<0.005 m" ;
VAL_ 1564 Obj_DistLat_rms 31 "Invalid" 30 "<10.000 m" 29 "<7.762 m" 28 "<6.025 m" 27 "<4.676 m" 26 "<3.630 m" 25 "<2.817 m" 24 "<2.187 m" 23 "<1.697 m" 22 "<1.317 m" 21 "<1.023 m" 20 "<0.794 m" 19 "<0.616 m" 18 "<0.478 m" 17 "<0.371 m" 16 "<0.288 m" 15 "<0.224 m" 14 "<0.174 m" 13 "<0.135 m" 12 "<0.105 m" 11 "<0.081 m" 10 "<0.063 m" 9 "<0.049 m" 8 "<0.038 m" 7 "<0.029 m" 6 "<0.023 m" 5 "<0.018 m" 4 "<0.014 m" 3 "<0.011 m" 2 "<0.008 m" 1 "<0.006 m" 0 "<0.005 m" ;
VAL_ 1659 Obj_DynProp 6 "Stopped" 5 "Unknown" 4 "Crossing right" 3 "Crossing left" 2 "Oncoming" 1 "Stationary" 0 "Moving" ;
VAL_ 1643 Obj_DynProp 6 "Stopped" 5 "Unknown" 4 "Crossing right" 3 "Crossing left" 2 "Oncoming" 1 "Stationary" 0 "Moving" ;
VAL_ 1627 Obj_DynProp 6 "Stopped" 5 "Unknown" 4 "Crossing right" 3 "Crossing left" 2 "Oncoming" 1 "Stationary" 0 "Moving" ;
VAL_ 1611 Obj_DynProp 6 "Stopped" 5 "Unknown" 4 "Crossing right" 3 "Crossing left" 2 "Oncoming" 1 "Stationary" 0 "Moving" ;
VAL_ 1595 Obj_DynProp 6 "Stopped" 5 "Unknown" 4 "Crossing right" 3 "Crossing left" 2 "Oncoming" 1 "Stationary" 0 "Moving" ;
VAL_ 1579 Obj_DynProp 6 "Stopped" 5 "Unknown" 4 "Crossing right" 3 "Crossing left" 2 "Oncoming" 1 "Stationary" 0 "Moving" ;
VAL_ 1563 Obj_DynProp 6 "Stopped" 5 "Unknown" 4 "Crossing right" 3 "Crossing left" 2 "Oncoming" 1 "Stationary" 0 "Moving" ;
